VERSION ""

NS_ :

BS_:

BU_: SR_RR SR_RF SR_LR SR_LF DACU

BO_ 2671902706 TesterFuncDiagMsg_Vic4: 8 DACU
 SG_ FuncDiagDataTester : 0|64@1+ (1,0) [0|0] ""  SR_LF,SR_RF,SR_LR,SR_RR

BO_ 1754 SR_RR_Debug10_Vic4: 64 Vector__XXX
 SG_ Debug_10_SR_RR : 0|512@1+ (1,0) [0|0] ""  SR_RR

BO_ 1753 SR_RR_Debug09_Vic4: 64 Vector__XXX
 SG_ Debug_09_SR_RR : 0|512@1+ (1,0) [0|0] ""  SR_RR

BO_ 1752 SR_RR_Debug08_Vic4: 64 Vector__XXX
 SG_ Debug_08_SR_RR : 0|512@1+ (1,0) [0|0] ""  SR_RR

BO_ 1751 SR_RR_Debug07_Vic4: 64 Vector__XXX
 SG_ Debug_07_SR_RR : 0|512@1+ (1,0) [0|0] ""  SR_RR

BO_ 1750 SR_RR_Debug06_Vic4: 64 Vector__XXX
 SG_ Debug_06_SR_RR : 0|512@1+ (1,0) [0|0] ""  SR_RR

BO_ 1749 SR_RR_Debug05_Vic4: 64 SR_RR
 SG_ Debug_05_SR_RR : 0|512@1+ (1,0) [0|0] "" Vector__XXX

BO_ 1748 SR_RR_Debug04_Vic4: 64 SR_RR
 SG_ Debug_04_SR_RR : 0|512@1+ (1,0) [0|0] "" Vector__XXX

BO_ 1747 SR_RR_Debug03_Vic4: 64 SR_RR
 SG_ Debug_03_SR_RR : 0|512@1+ (1,0) [0|0] "" Vector__XXX

BO_ 1746 SR_RR_Debug02_Vic4: 64 SR_RR
 SG_ Debug_02_SR_RR : 0|512@1+ (1,0) [0|0] "" Vector__XXX

BO_ 1745 SR_RR_Debug01_Vic4: 64 SR_RR
 SG_ Debug_01_SR_RR : 0|512@1+ (1,0) [0|0] "" Vector__XXX

BO_ 1738 SR_RF_Debug10_Vic4: 64 Vector__XXX
 SG_ Debug_10_SR_RF : 0|512@1+ (1,0) [0|0] ""  SR_RF

BO_ 1737 SR_RF_Debug09_Vic4: 64 Vector__XXX
 SG_ Debug_09_SR_RF : 0|512@1+ (1,0) [0|0] ""  SR_RF

BO_ 1736 SR_RF_Debug08_Vic4: 64 Vector__XXX
 SG_ Debug_08_SR_RF : 0|512@1+ (1,0) [0|0] ""  SR_RF

BO_ 1735 SR_RF_Debug07_Vic4: 64 Vector__XXX
 SG_ Debug_07_SR_RF : 0|512@1+ (1,0) [0|0] ""  SR_RF

BO_ 1734 SR_RF_Debug06_Vic4: 64 Vector__XXX
 SG_ Debug_06_SR_RF : 0|512@1+ (1,0) [0|0] ""  SR_RF

BO_ 1733 SR_RF_Debug05_Vic4: 64 SR_RF
 SG_ Debug_05_SR_RF : 0|512@1+ (1,0) [0|0] "" Vector__XXX

BO_ 1732 SR_RF_Debug04_Vic4: 64 SR_RF
 SG_ Debug_04_SR_RF : 0|512@1+ (1,0) [0|0] "" Vector__XXX

BO_ 1731 SR_RF_Debug03_Vic4: 64 SR_RF
 SG_ Debug_03_SR_RF : 0|512@1+ (1,0) [0|0] "" Vector__XXX

BO_ 1730 SR_RF_Debug02_Vic4: 64 SR_RF
 SG_ Debug_02_SR_RF : 0|512@1+ (1,0) [0|0] "" Vector__XXX

BO_ 1729 SR_RF_Debug01_Vic4: 64 SR_RF
 SG_ Debug_01_SR_RF : 0|512@1+ (1,0) [0|0] "" Vector__XXX

BO_ 1722 SR_LR_Debug10_Vic4: 64 Vector__XXX
 SG_ Debug_10_SR_LR : 0|512@1+ (1,0) [0|0] ""  SR_LR

BO_ 1721 SR_LR_Debug09_Vic4: 64 Vector__XXX
 SG_ Debug_09_SR_LR : 0|512@1+ (1,0) [0|0] ""  SR_LR

BO_ 1720 SR_LR_Debug08_Vic4: 64 Vector__XXX
 SG_ Debug_08_SR_LR : 0|512@1+ (1,0) [0|0] ""  SR_LR

BO_ 1719 SR_LR_Debug07_Vic4: 64 Vector__XXX
 SG_ Debug_07_SR_LR : 0|512@1+ (1,0) [0|0] ""  SR_LR

BO_ 1718 SR_LR_Debug06_Vic4: 64 Vector__XXX
 SG_ Debug_06_SR_LR : 0|512@1+ (1,0) [0|0] ""  SR_LR

BO_ 1717 SR_LR_Debug05_Vic4: 64 SR_LR
 SG_ Debug_05_SR_LR : 0|512@1+ (1,0) [0|0] "" Vector__XXX

BO_ 1716 SR_LR_Debug04_Vic4: 64 SR_LR
 SG_ Debug_04_SR_LR : 0|512@1+ (1,0) [0|0] "" Vector__XXX

BO_ 1715 SR_LR_Debug03_Vic4: 64 SR_LR
 SG_ Debug_03_SR_LR : 0|512@1+ (1,0) [0|0] "" Vector__XXX

BO_ 1714 SR_LR_Debug02_Vic4: 64 SR_LR
 SG_ Debug_02_SR_LR : 0|512@1+ (1,0) [0|0] "" Vector__XXX

BO_ 1713 SR_LR_Debug01_Vic4: 64 SR_LR
 SG_ Debug_01_SR_LR : 0|512@1+ (1,0) [0|0] "" Vector__XXX

BO_ 1706 SR_LF_Debug10_Vic4: 64 Vector__XXX
 SG_ Debug_10_SR_LF : 0|512@1+ (1,0) [0|0] ""  SR_LF

BO_ 1705 SR_LF_Debug09_Vic4: 64 Vector__XXX
 SG_ Debug_09_SR_LF : 0|512@1+ (1,0) [0|0] ""  SR_LF

BO_ 1704 SR_LF_Debug08_Vic4: 64 Vector__XXX
 SG_ Debug_08_SR_LF : 0|512@1+ (1,0) [0|0] ""  SR_LF

BO_ 1703 SR_LF_Debug07_Vic4: 64 Vector__XXX
 SG_ Debug_07_SR_LF : 0|512@1+ (1,0) [0|0] ""  SR_LF

BO_ 1702 SR_LF_Debug06_Vic4: 64 Vector__XXX
 SG_ Debug_06_SR_LF : 0|512@1+ (1,0) [0|0] ""  SR_LF

BO_ 1701 SR_LF_Debug05_Vic4: 64 SR_LF
 SG_ Debug_05_SR_LF : 0|512@1+ (1,0) [0|0] "" Vector__XXX

BO_ 1700 SR_LF_Debug04_Vic4: 64 SR_LF
 SG_ Debug_04_SR_LF : 0|512@1+ (1,0) [0|0] "" Vector__XXX

BO_ 1699 SR_LF_Debug03_Vic4: 64 SR_LF
 SG_ Debug_03_SR_LF : 0|512@1+ (1,0) [0|0] "" Vector__XXX

BO_ 1698 SR_LF_Debug02_Vic4: 64 SR_LF
 SG_ Debug_02_SR_LF : 0|512@1+ (1,0) [0|0] "" Vector__XXX

BO_ 1697 SR_LF_Debug01_Vic4: 64 SR_LF
 SG_ Debug_01_SR_LF : 0|512@1+ (1,0) [0|0] "" Vector__XXX

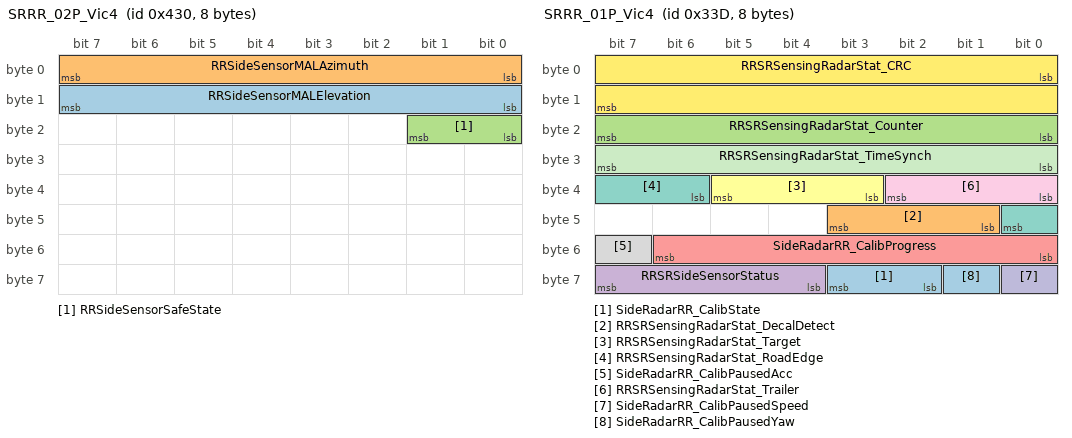
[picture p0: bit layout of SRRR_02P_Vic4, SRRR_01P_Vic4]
BO_ 1072 SRRR_02P_Vic4: 8 SR_RR
 SG_ RRSideSensorMALElevation : 8|8@1+ (0.0016,-0.2) [-0.2|0.208] "rad"  VCM
 SG_ RRSideSensorMALAzimuth : 0|8@1+ (0.0016,-0.2) [-0.2|0.208] "rad"  VCM
 SG_ RRSideSensorSafeState : 16|2@1+ (1,0) [0|0] ""  VCM

BO_ 829 SRRR_01P_Vic4: 8 SR_RR
 SG_ SideRadarRR_CalibState : 58|2@1+ (1,0) [0|0] ""  VCM
 SG_ RRSRSensingRadarStat_DecalDetect : 41|3@1+ (1,0) [0|0] ""  VCM
 SG_ RRSRSensingRadarStat_Counter : 16|8@1+ (1,0) [0|255] "Count"  VCM
 SG_ RRSRSideSensorStatus : 60|4@1+ (1,0) [0|0] ""  VCM
 SG_ SideRadarRR_CalibProgress : 48|7@1+ (1,0) [0|127] "Percent"  VCM
 SG_ RRSRSensingRadarStat_Target : 35|3@1+ (1,0) [0|0] ""  VCM
 SG_ RRSRSensingRadarStat_RoadEdge : 38|3@1+ (1,0) [0|0] ""  VCM
 SG_ SideRadarRR_CalibPausedAcc : 55|1@1+ (1,0) [0|0] ""  VCM
 SG_ RRSRSensingRadarStat_Trailer : 32|3@1+ (1,0) [0|0] ""  VCM
 SG_ SideRadarRR_CalibPausedSpeed : 56|1@1+ (1,0) [0|0] ""  VCM
 SG_ RRSRSensingRadarStat_TimeSynch : 24|8@1+ (1,0) [0|0] ""  VCM
 SG_ RRSRSensingRadarStat_CRC : 0|16@1+ (1,0) [0|65535] "NotApplicable"  VCM
 SG_ SideRadarRR_CalibPausedYaw : 57|1@1+ (1,0) [0|0] ""  VCM

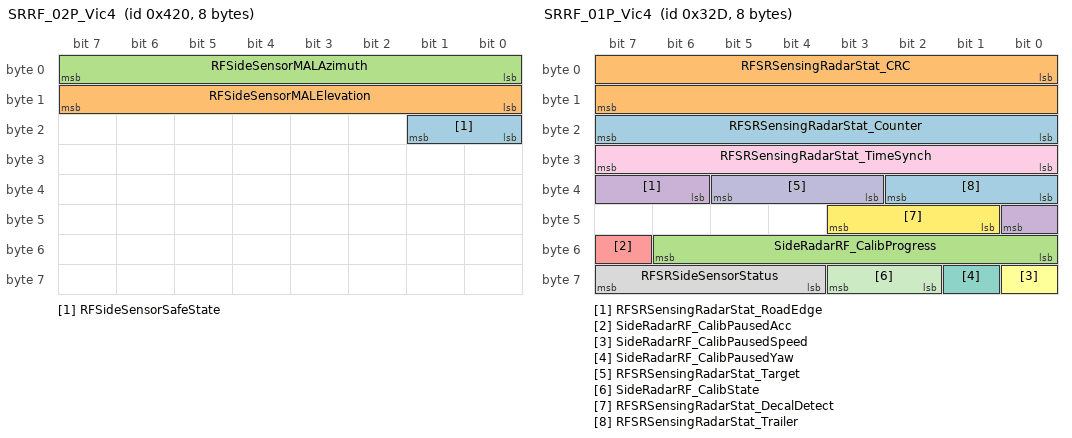
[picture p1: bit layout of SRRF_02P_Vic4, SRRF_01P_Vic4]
BO_ 1056 SRRF_02P_Vic4: 8 SR_RF
 SG_ RFSideSensorSafeState : 16|2@1+ (1,0) [0|0] ""  VCM
 SG_ RFSideSensorMALElevation : 8|8@1+ (0.0016,-0.2) [-0.2|0.208] "rad"  VCM
 SG_ RFSideSensorMALAzimuth : 0|8@1+ (0.0016,-0.2) [-0.2|0.208] "rad"  VCM

BO_ 813 SRRF_01P_Vic4: 8 SR_RF
 SG_ RFSRSensingRadarStat_Counter : 16|8@1+ (1,0) [0|255] "Count"  VCM
 SG_ RFSRSensingRadarStat_CRC : 0|16@1+ (1,0) [0|65535] "NotApplicable"  VCM
 SG_ SideRadarRF_CalibProgress : 48|7@1+ (1,0) [0|127] "Percent"  VCM
 SG_ RFSRSensingRadarStat_RoadEdge : 38|3@1+ (1,0) [0|0] ""  VCM
 SG_ SideRadarRF_CalibPausedAcc : 55|1@1+ (1,0) [0|0] ""  VCM
 SG_ SideRadarRF_CalibPausedSpeed : 56|1@1+ (1,0) [0|0] ""  VCM
 SG_ SideRadarRF_CalibPausedYaw : 57|1@1+ (1,0) [0|0] ""  VCM
 SG_ RFSRSideSensorStatus : 60|4@1+ (1,0) [0|0] ""  VCM
 SG_ RFSRSensingRadarStat_TimeSynch : 24|8@1+ (1,0) [0|0] ""  VCM
 SG_ RFSRSensingRadarStat_Target : 35|3@1+ (1,0) [0|0] ""  VCM
 SG_ SideRadarRF_CalibState : 58|2@1+ (1,0) [0|0] ""  VCM
 SG_ RFSRSensingRadarStat_DecalDetect : 41|3@1+ (1,0) [0|0] ""  VCM
 SG_ RFSRSensingRadarStat_Trailer : 32|3@1+ (1,0) [0|0] ""  VCM

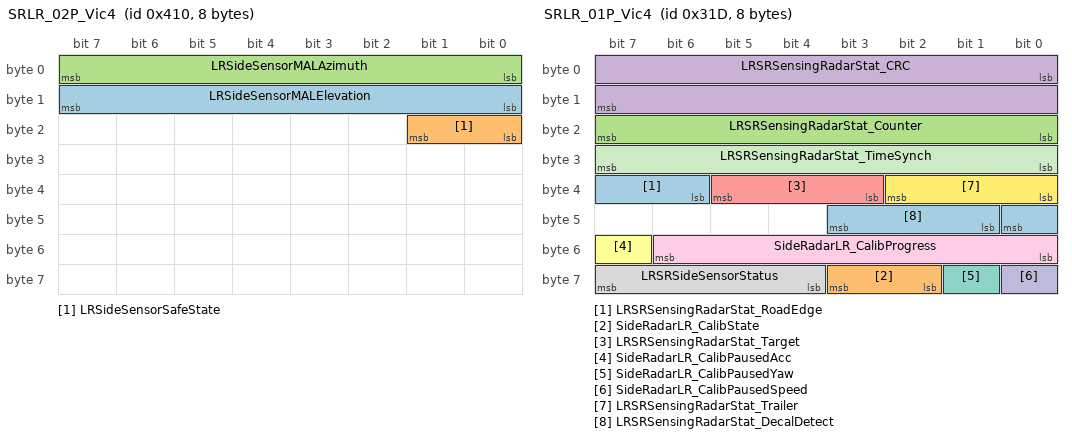
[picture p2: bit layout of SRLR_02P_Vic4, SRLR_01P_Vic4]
BO_ 1040 SRLR_02P_Vic4: 8 SR_LR
 SG_ LRSideSensorMALElevation : 8|8@1+ (0.0016,-0.2) [-0.2|0.208] "rad"  VCM
 SG_ LRSideSensorSafeState : 16|2@1+ (1,0) [0|0] ""  VCM
 SG_ LRSideSensorMALAzimuth : 0|8@1+ (0.0016,-0.2) [-0.2|0.208] "rad"  VCM

BO_ 797 SRLR_01P_Vic4: 8 SR_LR
 SG_ LRSRSensingRadarStat_RoadEdge : 38|3@1+ (1,0) [0|0] ""  VCM
 SG_ SideRadarLR_CalibState : 58|2@1+ (1,0) [0|0] ""  VCM
 SG_ LRSRSensingRadarStat_Counter : 16|8@1+ (1,0) [0|255] "Count"  VCM
 SG_ LRSRSensingRadarStat_CRC : 0|16@1+ (1,0) [0|65535] "NotApplicable"  VCM
 SG_ LRSRSensingRadarStat_Target : 35|3@1+ (1,0) [0|0] ""  VCM
 SG_ SideRadarLR_CalibPausedAcc : 55|1@1+ (1,0) [0|0] ""  VCM
 SG_ SideRadarLR_CalibPausedYaw : 57|1@1+ (1,0) [0|0] ""  VCM
 SG_ LRSRSideSensorStatus : 60|4@1+ (1,0) [0|0] ""  VCM
 SG_ SideRadarLR_CalibProgress : 48|7@1+ (1,0) [0|127] "Percent"  VCM
 SG_ SideRadarLR_CalibPausedSpeed : 56|1@1+ (1,0) [0|0] ""  VCM
 SG_ LRSRSensingRadarStat_TimeSynch : 24|8@1+ (1,0) [0|0] ""  VCM
 SG_ LRSRSensingRadarStat_Trailer : 32|3@1+ (1,0) [0|0] ""  VCM
 SG_ LRSRSensingRadarStat_DecalDetect : 41|3@1+ (1,0) [0|0] ""  VCM

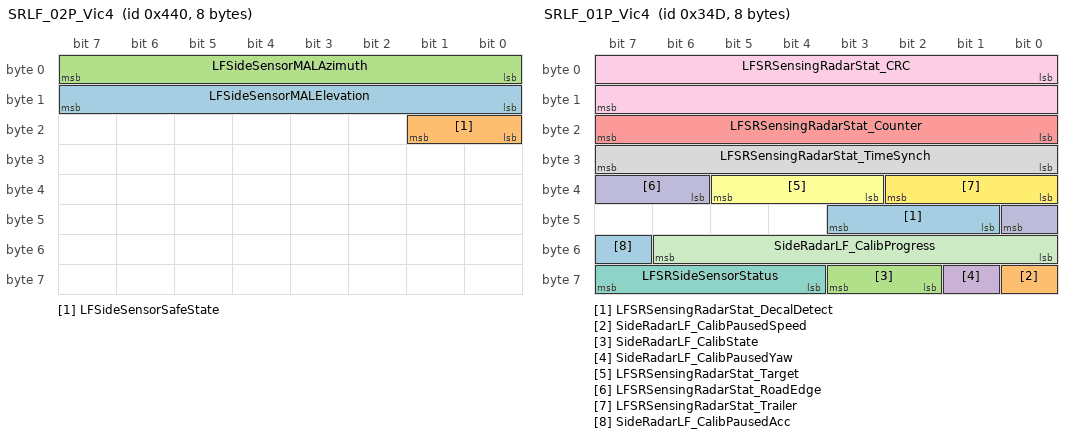
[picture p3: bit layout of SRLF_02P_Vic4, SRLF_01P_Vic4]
BO_ 1088 SRLF_02P_Vic4: 8 SR_LF
 SG_ LFSideSensorMALElevation : 8|8@1+ (0.0016,-0.2) [-0.2|0.208] "rad"  VCM
 SG_ LFSideSensorSafeState : 16|2@1+ (1,0) [0|0] ""  VCM
 SG_ LFSideSensorMALAzimuth : 0|8@1+ (0.0016,-0.2) [-0.2|0.208] "rad"  VCM

BO_ 845 SRLF_01P_Vic4: 8 SR_LF
 SG_ LFSRSensingRadarStat_DecalDetect : 41|3@1+ (1,0) [0|0] ""  VCM
 SG_ SideRadarLF_CalibPausedSpeed : 56|1@1+ (1,0) [0|0] ""  VCM
 SG_ SideRadarLF_CalibState : 58|2@1+ (1,0) [0|0] ""  VCM
 SG_ SideRadarLF_CalibPausedYaw : 57|1@1+ (1,0) [0|0] ""  VCM
 SG_ LFSRSensingRadarStat_Counter : 16|8@1+ (1,0) [0|255] "Count"  VCM
 SG_ LFSRSensingRadarStat_Target : 35|3@1+ (1,0) [0|0] ""  VCM
 SG_ LFSRSideSensorStatus : 60|4@1+ (1,0) [0|0] ""  VCM
 SG_ LFSRSensingRadarStat_TimeSynch : 24|8@1+ (1,0) [0|0] ""  VCM
 SG_ LFSRSensingRadarStat_CRC : 0|16@1+ (1,0) [0|65535] "NotApplicable"  VCM
 SG_ LFSRSensingRadarStat_RoadEdge : 38|3@1+ (1,0) [0|0] ""  VCM
 SG_ SideRadarLF_CalibProgress : 48|7@1+ (1,0) [0|127] "Percent"  VCM
 SG_ LFSRSensingRadarStat_Trailer : 32|3@1+ (1,0) [0|0] ""  VCM
 SG_ SideRadarLF_CalibPausedAcc : 55|1@1+ (1,0) [0|0] ""  VCM

BO_ 828 RRSideSensorTrlrObj: 32 SR_RR
 SG_ RRSideSensorTrlrObj_TrlAnglConf : 174|7@1+ (1,0) [0|0] ""  VCM
 SG_ RRSideSensorTrlrObj_Seg3Length : 9|9@1+ (0.05,0) [0|25.55] "m"  VCM
 SG_ RRSideSensorTrlrObj_SegTrlrType1 : 188|4@1+ (1,0) [0|0] ""  VCM
 SG_ RRSideSensorTrlrObj_SegAngle4 : 81|12@1+ (0.001745,-2.4) [-2.4|4.745775] "rad"  VCM
 SG_ RRSideSensorTrlrObj_WheelBased2 : 130|11@1+ (0.1,0) [0|204.7] "m"  VCM
 SG_ RRSideSensorTrlrObj_SegAngle3 : 69|12@1+ (0.001745,-2.4) [-2.4|4.745775] "rad"  VCM
 SG_ RRSideSensorTrlrObj_SegAngle5 : 93|12@1+ (0.001745,-2.4) [-2.4|4.745775] "rad"  VCM
 SG_ RRSideSensorTrlrObj_SegTrlrType5 : 204|4@1+ (1,0) [0|0] ""  VCM
 SG_ RRSideSensorTrlrObj_WheelBased1 : 119|11@1+ (0.1,0) [0|204.7] "m"  VCM
 SG_ RRSideSensorTrlrObj_SegTrlrType4 : 200|4@1+ (1,0) [0|0] ""  VCM
 SG_ RRSideSensorTrlrObj_WheelBased5 : 163|11@1+ (0.1,0) [0|204.7] "m"  VCM
 SG_ RRSideSensorTrlrObj_SegAngle1 : 45|12@1+ (0.001745,-2.4) [-2.4|4.745775] "rad"  VCM
 SG_ RRSideSensorTrlrObj_Seg5Length : 27|9@1+ (0.05,0) [0|25.55] "m"  VCM
 SG_ RRSideSensorTrlrObj_SegTrlrType3 : 196|4@1+ (1,0) [0|0] ""  VCM
 SG_ RRSideSensorTrlrObj_WheelBased4 : 152|11@1+ (0.1,0) [0|204.7] "m"  VCM
 SG_ RRSideSensorTrlrObj_Seg4Length : 18|9@1+ (0.05,0) [0|25.55] "m"  VCM
 SG_ RRSideSensorTrlrObj_WhlBasedConf : 181|7@1+ (1,0) [0|127] "Percent"  VCM
 SG_ RRSideSensorTrlrObj_Seg1Length : 36|9@1+ (0.05,0) [0|25.55] "m"  VCM
 SG_ RRSideSensorTrlrObj_SegTrlrType2 : 192|4@1+ (1,0) [0|0] ""  VCM
 SG_ RRSideSensorTrlrObj_SegAngle2 : 57|12@1+ (0.001745,-2.4) [-2.4|4.745775] "rad"  VCM
 SG_ RRSideSensorTrlrObj_WheelBased3 : 141|11@1+ (0.1,0) [0|204.7] "m"  VCM
 SG_ RRSideSensorTrlrObj_TotLenConf : 116|3@1+ (1,0) [0|0] ""  VCM
 SG_ RRSideSensorTrlrObj_TrlrTypeConf : 208|7@1+ (1,0) [0|127] "Percent"  VCM
 SG_ RRSideSensorTrlrObj_Seg2Length : 0|9@1+ (0.05,0) [0|25.55] "m"  VCM
 SG_ RRSideSensorTrlrObj_TotalLength : 105|11@1+ (0.1,0) [0|204.7] "m"  VCM

BO_ 827 RRSideSensorObj11: 48 SR_RR
 SG_ RRSideSensorObj11_TrackStatus : 192|3@1+ (1,0) [0|0] ""  VCM
 SG_ RRSideSensorObj11_CoastIndex : 155|5@1+ (1,0) [0|31] "NotApplicable"  VCM
 SG_ RRSideSensorObj11_ExistConf : 283|7@1+ (0.01,0) [0|1.27] "NotApplicable"  VCM
 SG_ RRSideSensorObj11_LatExtLeft : 276|7@1+ (0.05,0) [0|6.35] "m"  VCM
 SG_ RRSideSensorObj11_CRC : 0|16@1+ (1,0) [0|65535] "NotApplicable"  VCM
 SG_ RRSideSensorObj11_LongExtBkVar : 64|8@1+ (0.1,0) [0|25.5] "NotApplicable"  VCM
 SG_ RRSideSensorObj11_MOISPrio : 307|1@1+ (1,0) [0|0] ""  VCM
 SG_ RRSideSensorObj11_LongPosVar : 48|8@1+ (0.01,0) [0|2.55] "NotApplicable"  VCM
 SG_ RRSideSensorObj11_ObjClass : 292|4@1+ (1,0) [0|0] ""  VCM
 SG_ RRSideSensorObj11_LatVel : 208|13@1+ (0.032,-80) [-80|182.112] "m_per_s"  VCM
 SG_ RRSideSensorObj11_LatExtLeftVar : 104|8@1+ (0.1,0) [0|25.5] "NotApplicable"  VCM
 SG_ RRSideSensorObj11_LatPos : 221|13@1+ (0.05,-180) [-180|229.55] "m"  VCM
 SG_ RRSideSensorObj11_LongExtFront : 247|10@1+ (0.05,0) [0|51.15] "m"  VCM
 SG_ RRSideSensorObj11_LongAcc : 176|9@1+ (0.08,-20) [-20|20.88] "m_per_s_squared"  VCM
 SG_ RRSideSensorObj11_LifeTime : 128|16@1+ (0.1,0) [0|6553.5] "s"  VCM
 SG_ RRSideSensorObj11_LongVelVar : 40|8@1+ (0.01,0) [0|2.55] "NotApplicable"  VCM
 SG_ RRSideSensorObj11_TimeStamp : 24|16@1+ (0.1,0) [0|6553.5] "ms"  VCM
 SG_ RRSideSensorObj11_LatAcc : 267|9@1+ (0.08,-20) [-20|20.88] "m_per_s_squared"  VCM
 SG_ RRSideSensorObj11_HeadingVar : 120|8@1+ (0.001,0) [0|0.255] "NotApplicable"  VCM
 SG_ RRSideSensorObj11_Counter : 16|8@1+ (1,0) [0|255] "Count"  VCM
 SG_ RRSideSensorObj11_LatPosVar : 88|8@1+ (0.1,0) [0|25.5] "NotApplicable"  VCM
 SG_ RRSideSensorObj11_LongPos : 234|13@1+ (0.05,-180) [-180|229.55] "m"  VCM
 SG_ RRSideSensorObj11_LongVel : 195|13@1+ (0.032,-80) [-80|182.112] "m_per_s"  VCM
 SG_ RRSideSensorObj11_ObjID : 160|6@1+ (1,0) [0|63] "NotApplicable"  VCM
 SG_ RRSideSensorObj11_ObstacleConf : 300|7@1+ (0.01,0) [0|1.27] "NotApplicable"  VCM
 SG_ RRSideSensorObj11_LatExtRight : 185|7@1+ (0.05,-5) [-5|1.35] "m"  VCM
 SG_ RRSideSensorObj11_LongExtBack : 257|10@1+ (0.05,-50) [-50|1.15000000000001] "m"  VCM
 SG_ RRSideSensorObj11_ObjClassConf : 296|4@1+ (0.1,0) [0|1.5] "NotApplicable"  VCM
 SG_ RRSideSensorObj11_LatVelVar : 80|8@1+ (0.01,0) [0|2.55] "NotApplicable"  VCM
 SG_ RRSideSensorObj11_Heading : 144|11@1+ (0.005818,-4.71) [-4.71|7.199446] "rad"  VCM
 SG_ RRSideSensorObj11_Height : 168|8@1+ (0.02,0) [0|5.1] "m"  VCM
 SG_ RRSideSensorObj11_LatAccVar : 112|8@1+ (0.1,0) [0|25.5] "NotApplicable"  VCM
 SG_ RRSideSensorObj11_LongAccVar : 72|8@1+ (0.1,0) [0|25.5] "NotApplicable"  VCM
 SG_ RRSideSensorObj11_LatExtRtVar : 96|8@1+ (0.1,0) [0|25.5] "NotApplicable"  VCM
 SG_ RRSideSensorObj11_LongExtFrVar : 56|8@1+ (0.1,0) [0|25.5] "NotApplicable"  VCM
 SG_ RRSideSensorObj11_ObjDynClass : 166|2@1+ (1,0) [0|0] ""  VCM
 SG_ RRSideSensorObj11_Prioritisation : 290|2@1+ (1,0) [0|0] ""  VCM

BO_ 826 RRSideSensorObj10: 48 SR_RR
 SG_ RRSideSensorObj10_Counter : 16|8@1+ (1,0) [0|255] "Count"  VCM
 SG_ RRSideSensorObj10_LatExtRight : 185|7@1+ (0.05,-5) [-5|1.35] "m"  VCM
 SG_ RRSideSensorObj10_ObjClassConf : 296|4@1+ (0.1,0) [0|1.5] "NotApplicable"  VCM
 SG_ RRSideSensorObj10_ObjDynClass : 166|2@1+ (1,0) [0|0] ""  VCM
 SG_ RRSideSensorObj10_Prioritisation : 290|2@1+ (1,0) [0|0] ""  VCM
 SG_ RRSideSensorObj10_ObjClass : 292|4@1+ (1,0) [0|0] ""  VCM
 SG_ RRSideSensorObj10_LatPosVar : 88|8@1+ (0.1,0) [0|25.5] "NotApplicable"  VCM
 SG_ RRSideSensorObj10_Height : 168|8@1+ (0.02,0) [0|5.1] "m"  VCM
 SG_ RRSideSensorObj10_LatExtRtVar : 96|8@1+ (0.1,0) [0|25.5] "NotApplicable"  VCM
 SG_ RRSideSensorObj10_LatExtLeft : 276|7@1+ (0.05,0) [0|6.35] "m"  VCM
 SG_ RRSideSensorObj10_LongAccVar : 72|8@1+ (0.1,0) [0|25.5] "NotApplicable"  VCM
 SG_ RRSideSensorObj10_LongExtBack : 257|10@1+ (0.05,-50) [-50|1.15000000000001] "m"  VCM
 SG_ RRSideSensorObj10_HeadingVar : 120|8@1+ (0.001,0) [0|0.255] "NotApplicable"  VCM
 SG_ RRSideSensorObj10_CRC : 0|16@1+ (1,0) [0|65535] "NotApplicable"  VCM
 SG_ RRSideSensorObj10_LongExtBkVar : 64|8@1+ (0.1,0) [0|25.5] "NotApplicable"  VCM
 SG_ RRSideSensorObj10_TrackStatus : 192|3@1+ (1,0) [0|0] ""  VCM
 SG_ RRSideSensorObj10_LongVelVar : 40|8@1+ (0.01,0) [0|2.55] "NotApplicable"  VCM
 SG_ RRSideSensorObj10_ObjID : 160|6@1+ (1,0) [0|63] "NotApplicable"  VCM
 SG_ RRSideSensorObj10_LatExtLeftVar : 104|8@1+ (0.1,0) [0|25.5] "NotApplicable"  VCM
 SG_ RRSideSensorObj10_LongAcc : 176|9@1+ (0.08,-20) [-20|20.88] "m_per_s_squared"  VCM
 SG_ RRSideSensorObj10_ExistConf : 283|7@1+ (0.01,0) [0|1.27] "NotApplicable"  VCM
 SG_ RRSideSensorObj10_Heading : 144|11@1+ (0.005818,-4.71) [-4.71|7.199446] "rad"  VCM
 SG_ RRSideSensorObj10_LatAccVar : 112|8@1+ (0.1,0) [0|25.5] "NotApplicable"  VCM
 SG_ RRSideSensorObj10_LatAcc : 267|9@1+ (0.08,-20) [-20|20.88] "m_per_s_squared"  VCM
 SG_ RRSideSensorObj10_LongExtFront : 247|10@1+ (0.05,0) [0|51.15] "m"  VCM
 SG_ RRSideSensorObj10_LongExtFrVar : 56|8@1+ (0.1,0) [0|25.5] "NotApplicable"  VCM
 SG_ RRSideSensorObj10_LatVel : 208|13@1+ (0.032,-80) [-80|182.112] "m_per_s"  VCM
 SG_ RRSideSensorObj10_LongPos : 234|13@1+ (0.05,-180) [-180|229.55] "m"  VCM
 SG_ RRSideSensorObj10_LatPos : 221|13@1+ (0.05,-180) [-180|229.55] "m"  VCM
 SG_ RRSideSensorObj10_LongPosVar : 48|8@1+ (0.01,0) [0|2.55] "NotApplicable"  VCM
 SG_ RRSideSensorObj10_LongVel : 195|13@1+ (0.032,-80) [-80|182.112] "m_per_s"  VCM
 SG_ RRSideSensorObj10_ObstacleConf : 300|7@1+ (0.01,0) [0|1.27] "NotApplicable"  VCM
 SG_ RRSideSensorObj10_MOISPrio : 307|1@1+ (1,0) [0|0] ""  VCM
 SG_ RRSideSensorObj10_TimeStamp : 24|16@1+ (0.1,0) [0|6553.5] "ms"  VCM
 SG_ RRSideSensorObj10_LifeTime : 128|16@1+ (0.1,0) [0|6553.5] "s"  VCM
 SG_ RRSideSensorObj10_CoastIndex : 155|5@1+ (1,0) [0|31] "NotApplicable"  VCM
 SG_ RRSideSensorObj10_LatVelVar : 80|8@1+ (0.01,0) [0|2.55] "NotApplicable"  VCM

BO_ 825 RRSideSensorObj09: 48 SR_RR
 SG_ RRSideSensorObj09_LatExtRight : 185|7@1+ (0.05,-5) [-5|1.35] "m"  VCM
 SG_ RRSideSensorObj09_LongPosVar : 48|8@1+ (0.01,0) [0|2.55] "NotApplicable"  VCM
 SG_ RRSideSensorObj09_Height : 168|8@1+ (0.02,0) [0|5.1] "m"  VCM
 SG_ RRSideSensorObj09_LongAccVar : 72|8@1+ (0.1,0) [0|25.5] "NotApplicable"  VCM
 SG_ RRSideSensorObj09_LongExtBack : 257|10@1+ (0.05,-50) [-50|1.15000000000001] "m"  VCM
 SG_ RRSideSensorObj09_LatPosVar : 88|8@1+ (0.1,0) [0|25.5] "NotApplicable"  VCM
 SG_ RRSideSensorObj09_LatVelVar : 80|8@1+ (0.01,0) [0|2.55] "NotApplicable"  VCM
 SG_ RRSideSensorObj09_LatVel : 208|13@1+ (0.032,-80) [-80|182.112] "m_per_s"  VCM
 SG_ RRSideSensorObj09_LatExtLeft : 276|7@1+ (0.05,0) [0|6.35] "m"  VCM
 SG_ RRSideSensorObj09_HeadingVar : 120|8@1+ (0.001,0) [0|0.255] "NotApplicable"  VCM
 SG_ RRSideSensorObj09_LatExtRtVar : 96|8@1+ (0.1,0) [0|25.5] "NotApplicable"  VCM
 SG_ RRSideSensorObj09_ObjClassConf : 296|4@1+ (0.1,0) [0|1.5] "NotApplicable"  VCM
 SG_ RRSideSensorObj09_CoastIndex : 155|5@1+ (1,0) [0|31] "NotApplicable"  VCM
 SG_ RRSideSensorObj09_ObjDynClass : 166|2@1+ (1,0) [0|0] ""  VCM
 SG_ RRSideSensorObj09_LongExtFrVar : 56|8@1+ (0.1,0) [0|25.5] "NotApplicable"  VCM
 SG_ RRSideSensorObj09_LongPos : 234|13@1+ (0.05,-180) [-180|229.55] "m"  VCM
 SG_ RRSideSensorObj09_Counter : 16|8@1+ (1,0) [0|255] "Count"  VCM
 SG_ RRSideSensorObj09_CRC : 0|16@1+ (1,0) [0|65535] "NotApplicable"  VCM
 SG_ RRSideSensorObj09_LatAcc : 267|9@1+ (0.08,-20) [-20|20.88] "m_per_s_squared"  VCM
 SG_ RRSideSensorObj09_LongExtBkVar : 64|8@1+ (0.1,0) [0|25.5] "NotApplicable"  VCM
 SG_ RRSideSensorObj09_Heading : 144|11@1+ (0.005818,-4.71) [-4.71|7.199446] "rad"  VCM
 SG_ RRSideSensorObj09_LatAccVar : 112|8@1+ (0.1,0) [0|25.5] "NotApplicable"  VCM
 SG_ RRSideSensorObj09_ObjClass : 292|4@1+ (1,0) [0|0] ""  VCM
 SG_ RRSideSensorObj09_Prioritisation : 290|2@1+ (1,0) [0|0] ""  VCM
 SG_ RRSideSensorObj09_LongVel : 195|13@1+ (0.032,-80) [-80|182.112] "m_per_s"  VCM
 SG_ RRSideSensorObj09_TrackStatus : 192|3@1+ (1,0) [0|0] ""  VCM
 SG_ RRSideSensorObj09_LongExtFront : 247|10@1+ (0.05,0) [0|51.15] "m"  VCM
 SG_ RRSideSensorObj09_LatExtLeftVar : 104|8@1+ (0.1,0) [0|25.5] "NotApplicable"  VCM
 SG_ RRSideSensorObj09_TimeStamp : 24|16@1+ (0.1,0) [0|6553.5] "ms"  VCM
 SG_ RRSideSensorObj09_ObjID : 160|6@1+ (1,0) [0|63] "NotApplicable"  VCM
 SG_ RRSideSensorObj09_LongAcc : 176|9@1+ (0.08,-20) [-20|20.88] "m_per_s_squared"  VCM
 SG_ RRSideSensorObj09_LatPos : 221|13@1+ (0.05,-180) [-180|229.55] "m"  VCM
 SG_ RRSideSensorObj09_ObstacleConf : 300|7@1+ (0.01,0) [0|1.27] "NotApplicable"  VCM
 SG_ RRSideSensorObj09_MOISPrio : 307|1@1+ (1,0) [0|0] ""  VCM
 SG_ RRSideSensorObj09_LongVelVar : 40|8@1+ (0.01,0) [0|2.55] "NotApplicable"  VCM
 SG_ RRSideSensorObj09_ExistConf : 283|7@1+ (0.01,0) [0|1.27] "NotApplicable"  VCM
 SG_ RRSideSensorObj09_LifeTime : 128|16@1+ (0.1,0) [0|6553.5] "s"  VCM

BO_ 824 RRSideSensorObj08: 48 SR_RR
 SG_ RRSideSensorObj08_LongExtBkVar : 64|8@1+ (0.1,0) [0|25.5] "NotApplicable"  VCM
 SG_ RRSideSensorObj08_ExistConf : 283|7@1+ (0.01,0) [0|1.27] "NotApplicable"  VCM
 SG_ RRSideSensorObj08_CRC : 0|16@1+ (1,0) [0|65535] "NotApplicable"  VCM
 SG_ RRSideSensorObj08_LifeTime : 128|16@1+ (0.1,0) [0|6553.5] "s"  VCM
 SG_ RRSideSensorObj08_LatAcc : 267|9@1+ (0.08,-20) [-20|20.88] "m_per_s_squared"  VCM
 SG_ RRSideSensorObj08_LongAcc : 176|9@1+ (0.08,-20) [-20|20.88] "m_per_s_squared"  VCM
 SG_ RRSideSensorObj08_Counter : 16|8@1+ (1,0) [0|255] "Count"  VCM
 SG_ RRSideSensorObj08_LongExtBack : 257|10@1+ (0.05,-50) [-50|1.15000000000001] "m"  VCM
 SG_ RRSideSensorObj08_LatExtLeft : 276|7@1+ (0.05,0) [0|6.35] "m"  VCM
 SG_ RRSideSensorObj08_TimeStamp : 24|16@1+ (0.1,0) [0|6553.5] "ms"  VCM
 SG_ RRSideSensorObj08_LatPosVar : 88|8@1+ (0.1,0) [0|25.5] "NotApplicable"  VCM
 SG_ RRSideSensorObj08_LatExtLeftVar : 104|8@1+ (0.1,0) [0|25.5] "NotApplicable"  VCM
 SG_ RRSideSensorObj08_Height : 168|8@1+ (0.02,0) [0|5.1] "m"  VCM
 SG_ RRSideSensorObj08_LongExtFront : 247|10@1+ (0.05,0) [0|51.15] "m"  VCM
 SG_ RRSideSensorObj08_Prioritisation : 290|2@1+ (1,0) [0|0] ""  VCM
 SG_ RRSideSensorObj08_HeadingVar : 120|8@1+ (0.001,0) [0|0.255] "NotApplicable"  VCM
 SG_ RRSideSensorObj08_LongAccVar : 72|8@1+ (0.1,0) [0|25.5] "NotApplicable"  VCM
 SG_ RRSideSensorObj08_LatAccVar : 112|8@1+ (0.1,0) [0|25.5] "NotApplicable"  VCM
 SG_ RRSideSensorObj08_ObstacleConf : 300|7@1+ (0.01,0) [0|1.27] "NotApplicable"  VCM
 SG_ RRSideSensorObj08_LatVelVar : 80|8@1+ (0.01,0) [0|2.55] "NotApplicable"  VCM
 SG_ RRSideSensorObj08_TrackStatus : 192|3@1+ (1,0) [0|0] ""  VCM
 SG_ RRSideSensorObj08_MOISPrio : 307|1@1+ (1,0) [0|0] ""  VCM
 SG_ RRSideSensorObj08_LatExtRight : 185|7@1+ (0.05,-5) [-5|1.35] "m"  VCM
 SG_ RRSideSensorObj08_LongPosVar : 48|8@1+ (0.01,0) [0|2.55] "NotApplicable"  VCM
 SG_ RRSideSensorObj08_LongExtFrVar : 56|8@1+ (0.1,0) [0|25.5] "NotApplicable"  VCM
 SG_ RRSideSensorObj08_LatVel : 208|13@1+ (0.032,-80) [-80|182.112] "m_per_s"  VCM
 SG_ RRSideSensorObj08_LatExtRtVar : 96|8@1+ (0.1,0) [0|25.5] "NotApplicable"  VCM
 SG_ RRSideSensorObj08_ObjDynClass : 166|2@1+ (1,0) [0|0] ""  VCM
 SG_ RRSideSensorObj08_LongVelVar : 40|8@1+ (0.01,0) [0|2.55] "NotApplicable"  VCM
 SG_ RRSideSensorObj08_Heading : 144|11@1+ (0.005818,-4.71) [-4.71|7.199446] "rad"  VCM
 SG_ RRSideSensorObj08_CoastIndex : 155|5@1+ (1,0) [0|31] "NotApplicable"  VCM
 SG_ RRSideSensorObj08_ObjClass : 292|4@1+ (1,0) [0|0] ""  VCM
 SG_ RRSideSensorObj08_LongVel : 195|13@1+ (0.032,-80) [-80|182.112] "m_per_s"  VCM
 SG_ RRSideSensorObj08_LatPos : 221|13@1+ (0.05,-180) [-180|229.55] "m"  VCM
 SG_ RRSideSensorObj08_ObjID : 160|6@1+ (1,0) [0|63] "NotApplicable"  VCM
 SG_ RRSideSensorObj08_LongPos : 234|13@1+ (0.05,-180) [-180|229.55] "m"  VCM
 SG_ RRSideSensorObj08_ObjClassConf : 296|4@1+ (0.1,0) [0|1.5] "NotApplicable"  VCM

BO_ 823 RRSideSensorObj07: 48 SR_RR
 SG_ RRSideSensorObj07_LifeTime : 128|16@1+ (0.1,0) [0|6553.5] "s"  VCM
 SG_ RRSideSensorObj07_HeadingVar : 120|8@1+ (0.001,0) [0|0.255] "NotApplicable"  VCM
 SG_ RRSideSensorObj07_LongExtFrVar : 56|8@1+ (0.1,0) [0|25.5] "NotApplicable"  VCM
 SG_ RRSideSensorObj07_ObjID : 160|6@1+ (1,0) [0|63] "NotApplicable"  VCM
 SG_ RRSideSensorObj07_Heading : 144|11@1+ (0.005818,-4.71) [-4.71|7.199446] "rad"  VCM
 SG_ RRSideSensorObj07_LongVelVar : 40|8@1+ (0.01,0) [0|2.55] "NotApplicable"  VCM
 SG_ RRSideSensorObj07_TimeStamp : 24|16@1+ (0.1,0) [0|6553.5] "ms"  VCM
 SG_ RRSideSensorObj07_LatPosVar : 88|8@1+ (0.1,0) [0|25.5] "NotApplicable"  VCM
 SG_ RRSideSensorObj07_ExistConf : 283|7@1+ (0.01,0) [0|1.27] "NotApplicable"  VCM
 SG_ RRSideSensorObj07_Prioritisation : 290|2@1+ (1,0) [0|0] ""  VCM
 SG_ RRSideSensorObj07_Counter : 16|8@1+ (1,0) [0|255] "Count"  VCM
 SG_ RRSideSensorObj07_LatPos : 221|13@1+ (0.05,-180) [-180|229.55] "m"  VCM
 SG_ RRSideSensorObj07_LongVel : 195|13@1+ (0.032,-80) [-80|182.112] "m_per_s"  VCM
 SG_ RRSideSensorObj07_LongExtBack : 257|10@1+ (0.05,-50) [-50|1.15000000000001] "m"  VCM
 SG_ RRSideSensorObj07_LongExtFront : 247|10@1+ (0.05,0) [0|51.15] "m"  VCM
 SG_ RRSideSensorObj07_TrackStatus : 192|3@1+ (1,0) [0|0] ""  VCM
 SG_ RRSideSensorObj07_LongExtBkVar : 64|8@1+ (0.1,0) [0|25.5] "NotApplicable"  VCM
 SG_ RRSideSensorObj07_LatAccVar : 112|8@1+ (0.1,0) [0|25.5] "NotApplicable"  VCM
 SG_ RRSideSensorObj07_LongAcc : 176|9@1+ (0.08,-20) [-20|20.88] "m_per_s_squared"  VCM
 SG_ RRSideSensorObj07_LatAcc : 267|9@1+ (0.08,-20) [-20|20.88] "m_per_s_squared"  VCM
 SG_ RRSideSensorObj07_ObjDynClass : 166|2@1+ (1,0) [0|0] ""  VCM
 SG_ RRSideSensorObj07_ObjClassConf : 296|4@1+ (0.1,0) [0|1.5] "NotApplicable"  VCM
 SG_ RRSideSensorObj07_CRC : 0|16@1+ (1,0) [0|65535] "NotApplicable"  VCM
 SG_ RRSideSensorObj07_LongPosVar : 48|8@1+ (0.01,0) [0|2.55] "NotApplicable"  VCM
 SG_ RRSideSensorObj07_LatExtLeftVar : 104|8@1+ (0.1,0) [0|25.5] "NotApplicable"  VCM
 SG_ RRSideSensorObj07_MOISPrio : 307|1@1+ (1,0) [0|0] ""  VCM
 SG_ RRSideSensorObj07_ObjClass : 292|4@1+ (1,0) [0|0] ""  VCM
 SG_ RRSideSensorObj07_ObstacleConf : 300|7@1+ (0.01,0) [0|1.27] "NotApplicable"  VCM
 SG_ RRSideSensorObj07_LatExtRtVar : 96|8@1+ (0.1,0) [0|25.5] "NotApplicable"  VCM
 SG_ RRSideSensorObj07_LatExtRight : 185|7@1+ (0.05,-5) [-5|1.35] "m"  VCM
 SG_ RRSideSensorObj07_LatExtLeft : 276|7@1+ (0.05,0) [0|6.35] "m"  VCM
 SG_ RRSideSensorObj07_Height : 168|8@1+ (0.02,0) [0|5.1] "m"  VCM
 SG_ RRSideSensorObj07_LatVel : 208|13@1+ (0.032,-80) [-80|182.112] "m_per_s"  VCM
 SG_ RRSideSensorObj07_LongAccVar : 72|8@1+ (0.1,0) [0|25.5] "NotApplicable"  VCM
 SG_ RRSideSensorObj07_LongPos : 234|13@1+ (0.05,-180) [-180|229.55] "m"  VCM
 SG_ RRSideSensorObj07_CoastIndex : 155|5@1+ (1,0) [0|31] "NotApplicable"  VCM
 SG_ RRSideSensorObj07_LatVelVar : 80|8@1+ (0.01,0) [0|2.55] "NotApplicable"  VCM

BO_ 822 RRSideSensorObj06: 48 SR_RR
 SG_ RRSideSensorObj06_LongExtFront : 247|10@1+ (0.05,0) [0|51.15] "m"  VCM
 SG_ RRSideSensorObj06_ObjDynClass : 166|2@1+ (1,0) [0|0] ""  VCM
 SG_ RRSideSensorObj06_MOISPrio : 307|1@1+ (1,0) [0|0] ""  VCM
 SG_ RRSideSensorObj06_LatExtLeft : 276|7@1+ (0.05,0) [0|6.35] "m"  VCM
 SG_ RRSideSensorObj06_ObjClassConf : 296|4@1+ (0.1,0) [0|1.5] "NotApplicable"  VCM
 SG_ RRSideSensorObj06_LongPosVar : 48|8@1+ (0.01,0) [0|2.55] "NotApplicable"  VCM
 SG_ RRSideSensorObj06_LatExtRight : 185|7@1+ (0.05,-5) [-5|1.35] "m"  VCM
 SG_ RRSideSensorObj06_LongVel : 195|13@1+ (0.032,-80) [-80|182.112] "m_per_s"  VCM
 SG_ RRSideSensorObj06_LifeTime : 128|16@1+ (0.1,0) [0|6553.5] "s"  VCM
 SG_ RRSideSensorObj06_LongExtBack : 257|10@1+ (0.05,-50) [-50|1.15000000000001] "m"  VCM
 SG_ RRSideSensorObj06_HeadingVar : 120|8@1+ (0.001,0) [0|0.255] "NotApplicable"  VCM
 SG_ RRSideSensorObj06_LatVel : 208|13@1+ (0.032,-80) [-80|182.112] "m_per_s"  VCM
 SG_ RRSideSensorObj06_LatExtRtVar : 96|8@1+ (0.1,0) [0|25.5] "NotApplicable"  VCM
 SG_ RRSideSensorObj06_LongExtFrVar : 56|8@1+ (0.1,0) [0|25.5] "NotApplicable"  VCM
 SG_ RRSideSensorObj06_LongAccVar : 72|8@1+ (0.1,0) [0|25.5] "NotApplicable"  VCM
 SG_ RRSideSensorObj06_LatExtLeftVar : 104|8@1+ (0.1,0) [0|25.5] "NotApplicable"  VCM
 SG_ RRSideSensorObj06_LongVelVar : 40|8@1+ (0.01,0) [0|2.55] "NotApplicable"  VCM
 SG_ RRSideSensorObj06_Prioritisation : 290|2@1+ (1,0) [0|0] ""  VCM
 SG_ RRSideSensorObj06_LongPos : 234|13@1+ (0.05,-180) [-180|229.55] "m"  VCM
 SG_ RRSideSensorObj06_Counter : 16|8@1+ (1,0) [0|255] "Count"  VCM
 SG_ RRSideSensorObj06_LatVelVar : 80|8@1+ (0.01,0) [0|2.55] "NotApplicable"  VCM
 SG_ RRSideSensorObj06_LatAccVar : 112|8@1+ (0.1,0) [0|25.5] "NotApplicable"  VCM
 SG_ RRSideSensorObj06_Heading : 144|11@1+ (0.005818,-4.71) [-4.71|7.199446] "rad"  VCM
 SG_ RRSideSensorObj06_ObjClass : 292|4@1+ (1,0) [0|0] ""  VCM
 SG_ RRSideSensorObj06_ObstacleConf : 300|7@1+ (0.01,0) [0|1.27] "NotApplicable"  VCM
 SG_ RRSideSensorObj06_LatPosVar : 88|8@1+ (0.1,0) [0|25.5] "NotApplicable"  VCM
 SG_ RRSideSensorObj06_LongAcc : 176|9@1+ (0.08,-20) [-20|20.88] "m_per_s_squared"  VCM
 SG_ RRSideSensorObj06_LongExtBkVar : 64|8@1+ (0.1,0) [0|25.5] "NotApplicable"  VCM
 SG_ RRSideSensorObj06_Height : 168|8@1+ (0.02,0) [0|5.1] "m"  VCM
 SG_ RRSideSensorObj06_LatPos : 221|13@1+ (0.05,-180) [-180|229.55] "m"  VCM
 SG_ RRSideSensorObj06_CoastIndex : 155|5@1+ (1,0) [0|31] "NotApplicable"  VCM
 SG_ RRSideSensorObj06_TrackStatus : 192|3@1+ (1,0) [0|0] ""  VCM
 SG_ RRSideSensorObj06_LatAcc : 267|9@1+ (0.08,-20) [-20|20.88] "m_per_s_squared"  VCM
 SG_ RRSideSensorObj06_ExistConf : 283|7@1+ (0.01,0) [0|1.27] "NotApplicable"  VCM
 SG_ RRSideSensorObj06_CRC : 0|16@1+ (1,0) [0|65535] "NotApplicable"  VCM
 SG_ RRSideSensorObj06_ObjID : 160|6@1+ (1,0) [0|63] "NotApplicable"  VCM
 SG_ RRSideSensorObj06_TimeStamp : 24|16@1+ (0.1,0) [0|6553.5] "ms"  VCM

BO_ 821 RRSideSensorObj05: 48 SR_RR
 SG_ RRSideSensorObj05_LatPos : 221|13@1+ (0.05,-180) [-180|229.55] "m"  VCM
 SG_ RRSideSensorObj05_ObjClass : 292|4@1+ (1,0) [0|0] ""  VCM
 SG_ RRSideSensorObj05_LongVel : 195|13@1+ (0.032,-80) [-80|182.112] "m_per_s"  VCM
 SG_ RRSideSensorObj05_ObjID : 160|6@1+ (1,0) [0|63] "NotApplicable"  VCM
 SG_ RRSideSensorObj05_LatPosVar : 88|8@1+ (0.1,0) [0|25.5] "NotApplicable"  VCM
 SG_ RRSideSensorObj05_Prioritisation : 290|2@1+ (1,0) [0|0] ""  VCM
 SG_ RRSideSensorObj05_LifeTime : 128|16@1+ (0.1,0) [0|6553.5] "s"  VCM
 SG_ RRSideSensorObj05_LongAccVar : 72|8@1+ (0.1,0) [0|25.5] "NotApplicable"  VCM
 SG_ RRSideSensorObj05_CRC : 0|16@1+ (1,0) [0|65535] "NotApplicable"  VCM
 SG_ RRSideSensorObj05_TrackStatus : 192|3@1+ (1,0) [0|0] ""  VCM
 SG_ RRSideSensorObj05_ObstacleConf : 300|7@1+ (0.01,0) [0|1.27] "NotApplicable"  VCM
 SG_ RRSideSensorObj05_ObjDynClass : 166|2@1+ (1,0) [0|0] ""  VCM
 SG_ RRSideSensorObj05_LatExtRight : 185|7@1+ (0.05,-5) [-5|1.35] "m"  VCM
 SG_ RRSideSensorObj05_LongPosVar : 48|8@1+ (0.01,0) [0|2.55] "NotApplicable"  VCM
 SG_ RRSideSensorObj05_Heading : 144|11@1+ (0.005818,-4.71) [-4.71|7.199446] "rad"  VCM
 SG_ RRSideSensorObj05_LongExtFront : 247|10@1+ (0.05,0) [0|51.15] "m"  VCM
 SG_ RRSideSensorObj05_LatAcc : 267|9@1+ (0.08,-20) [-20|20.88] "m_per_s_squared"  VCM
 SG_ RRSideSensorObj05_MOISPrio : 307|1@1+ (1,0) [0|0] ""  VCM
 SG_ RRSideSensorObj05_LatVelVar : 80|8@1+ (0.01,0) [0|2.55] "NotApplicable"  VCM
 SG_ RRSideSensorObj05_LatAccVar : 112|8@1+ (0.1,0) [0|25.5] "NotApplicable"  VCM
 SG_ RRSideSensorObj05_LongAcc : 176|9@1+ (0.08,-20) [-20|20.88] "m_per_s_squared"  VCM
 SG_ RRSideSensorObj05_LongExtBack : 257|10@1+ (0.05,-50) [-50|1.15000000000001] "m"  VCM
 SG_ RRSideSensorObj05_ObjClassConf : 296|4@1+ (0.1,0) [0|1.5] "NotApplicable"  VCM
 SG_ RRSideSensorObj05_ExistConf : 283|7@1+ (0.01,0) [0|1.27] "NotApplicable"  VCM
 SG_ RRSideSensorObj05_Height : 168|8@1+ (0.02,0) [0|5.1] "m"  VCM
 SG_ RRSideSensorObj05_LongExtFrVar : 56|8@1+ (0.1,0) [0|25.5] "NotApplicable"  VCM
 SG_ RRSideSensorObj05_Counter : 16|8@1+ (1,0) [0|255] "Count"  VCM
 SG_ RRSideSensorObj05_TimeStamp : 24|16@1+ (0.1,0) [0|6553.5] "ms"  VCM
 SG_ RRSideSensorObj05_LongPos : 234|13@1+ (0.05,-180) [-180|229.55] "m"  VCM
 SG_ RRSideSensorObj05_LongVelVar : 40|8@1+ (0.01,0) [0|2.55] "NotApplicable"  VCM
 SG_ RRSideSensorObj05_HeadingVar : 120|8@1+ (0.001,0) [0|0.255] "NotApplicable"  VCM
 SG_ RRSideSensorObj05_LatExtRtVar : 96|8@1+ (0.1,0) [0|25.5] "NotApplicable"  VCM
 SG_ RRSideSensorObj05_LatVel : 208|13@1+ (0.032,-80) [-80|182.112] "m_per_s"  VCM
 SG_ RRSideSensorObj05_LatExtLeft : 276|7@1+ (0.05,0) [0|6.35] "m"  VCM
 SG_ RRSideSensorObj05_LongExtBkVar : 64|8@1+ (0.1,0) [0|25.5] "NotApplicable"  VCM
 SG_ RRSideSensorObj05_CoastIndex : 155|5@1+ (1,0) [0|31] "NotApplicable"  VCM
 SG_ RRSideSensorObj05_LatExtLeftVar : 104|8@1+ (0.1,0) [0|25.5] "NotApplicable"  VCM

BO_ 820 RRSideSensorObj04: 48 SR_RR
 SG_ RRSideSensorObj04_HeadingVar : 120|8@1+ (0.001,0) [0|0.255] "NotApplicable"  VCM
 SG_ RRSideSensorObj04_TrackStatus : 192|3@1+ (1,0) [0|0] ""  VCM
 SG_ RRSideSensorObj04_LongExtFront : 247|10@1+ (0.05,0) [0|51.15] "m"  VCM
 SG_ RRSideSensorObj04_LatAcc : 267|9@1+ (0.08,-20) [-20|20.88] "m_per_s_squared"  VCM
 SG_ RRSideSensorObj04_LongPosVar : 48|8@1+ (0.01,0) [0|2.55] "NotApplicable"  VCM
 SG_ RRSideSensorObj04_LatVelVar : 80|8@1+ (0.01,0) [0|2.55] "NotApplicable"  VCM
 SG_ RRSideSensorObj04_CoastIndex : 155|5@1+ (1,0) [0|31] "NotApplicable"  VCM
 SG_ RRSideSensorObj04_LatPosVar : 88|8@1+ (0.1,0) [0|25.5] "NotApplicable"  VCM
 SG_ RRSideSensorObj04_ExistConf : 283|7@1+ (0.01,0) [0|1.27] "NotApplicable"  VCM
 SG_ RRSideSensorObj04_LatExtRight : 185|7@1+ (0.05,-5) [-5|1.35] "m"  VCM
 SG_ RRSideSensorObj04_LatAccVar : 112|8@1+ (0.1,0) [0|25.5] "NotApplicable"  VCM
 SG_ RRSideSensorObj04_ObjID : 160|6@1+ (1,0) [0|63] "NotApplicable"  VCM
 SG_ RRSideSensorObj04_LongAccVar : 72|8@1+ (0.1,0) [0|25.5] "NotApplicable"  VCM
 SG_ RRSideSensorObj04_ObstacleConf : 300|7@1+ (0.01,0) [0|1.27] "NotApplicable"  VCM
 SG_ RRSideSensorObj04_MOISPrio : 307|1@1+ (1,0) [0|0] ""  VCM
 SG_ RRSideSensorObj04_LongPos : 234|13@1+ (0.05,-180) [-180|229.55] "m"  VCM
 SG_ RRSideSensorObj04_LatVel : 208|13@1+ (0.032,-80) [-80|182.112] "m_per_s"  VCM
 SG_ RRSideSensorObj04_LongExtBack : 257|10@1+ (0.05,-50) [-50|1.15000000000001] "m"  VCM
 SG_ RRSideSensorObj04_TimeStamp : 24|16@1+ (0.1,0) [0|6553.5] "ms"  VCM
 SG_ RRSideSensorObj04_LatExtRtVar : 96|8@1+ (0.1,0) [0|25.5] "NotApplicable"  VCM
 SG_ RRSideSensorObj04_CRC : 0|16@1+ (1,0) [0|65535] "NotApplicable"  VCM
 SG_ RRSideSensorObj04_LatExtLeft : 276|7@1+ (0.05,0) [0|6.35] "m"  VCM
 SG_ RRSideSensorObj04_LongVel : 195|13@1+ (0.032,-80) [-80|182.112] "m_per_s"  VCM
 SG_ RRSideSensorObj04_LongExtFrVar : 56|8@1+ (0.1,0) [0|25.5] "NotApplicable"  VCM
 SG_ RRSideSensorObj04_Counter : 16|8@1+ (1,0) [0|255] "Count"  VCM
 SG_ RRSideSensorObj04_LatPos : 221|13@1+ (0.05,-180) [-180|229.55] "m"  VCM
 SG_ RRSideSensorObj04_LatExtLeftVar : 104|8@1+ (0.1,0) [0|25.5] "NotApplicable"  VCM
 SG_ RRSideSensorObj04_LifeTime : 128|16@1+ (0.1,0) [0|6553.5] "s"  VCM
 SG_ RRSideSensorObj04_Height : 168|8@1+ (0.02,0) [0|5.1] "m"  VCM
 SG_ RRSideSensorObj04_LongAcc : 176|9@1+ (0.08,-20) [-20|20.88] "m_per_s_squared"  VCM
 SG_ RRSideSensorObj04_ObjDynClass : 166|2@1+ (1,0) [0|0] ""  VCM
 SG_ RRSideSensorObj04_LongVelVar : 40|8@1+ (0.01,0) [0|2.55] "NotApplicable"  VCM
 SG_ RRSideSensorObj04_ObjClass : 292|4@1+ (1,0) [0|0] ""  VCM
 SG_ RRSideSensorObj04_ObjClassConf : 296|4@1+ (0.1,0) [0|1.5] "NotApplicable"  VCM
 SG_ RRSideSensorObj04_Prioritisation : 290|2@1+ (1,0) [0|0] ""  VCM
 SG_ RRSideSensorObj04_Heading : 144|11@1+ (0.005818,-4.71) [-4.71|7.199446] "rad"  VCM
 SG_ RRSideSensorObj04_LongExtBkVar : 64|8@1+ (0.1,0) [0|25.5] "NotApplicable"  VCM

BO_ 819 RRSideSensorObj03: 48 SR_RR
 SG_ RRSideSensorObj03_LongExtBack : 257|10@1+ (0.05,-50) [-50|1.15000000000001] "m"  VCM
 SG_ RRSideSensorObj03_ObjDynClass : 166|2@1+ (1,0) [0|0] ""  VCM
 SG_ RRSideSensorObj03_ObjClass : 292|4@1+ (1,0) [0|0] ""  VCM
 SG_ RRSideSensorObj03_LatAcc : 267|9@1+ (0.08,-20) [-20|20.88] "m_per_s_squared"  VCM
 SG_ RRSideSensorObj03_Heading : 144|11@1+ (0.005818,-4.71) [-4.71|7.199446] "rad"  VCM
 SG_ RRSideSensorObj03_ObjClassConf : 296|4@1+ (0.1,0) [0|1.5] "NotApplicable"  VCM
 SG_ RRSideSensorObj03_LongPos : 234|13@1+ (0.05,-180) [-180|229.55] "m"  VCM
 SG_ RRSideSensorObj03_ObjID : 160|6@1+ (1,0) [0|63] "NotApplicable"  VCM
 SG_ RRSideSensorObj03_TimeStamp : 24|16@1+ (0.1,0) [0|6553.5] "ms"  VCM
 SG_ RRSideSensorObj03_LongPosVar : 48|8@1+ (0.01,0) [0|2.55] "NotApplicable"  VCM
 SG_ RRSideSensorObj03_LatExtLeft : 276|7@1+ (0.05,0) [0|6.35] "m"  VCM
 SG_ RRSideSensorObj03_LongExtFrVar : 56|8@1+ (0.1,0) [0|25.5] "NotApplicable"  VCM
 SG_ RRSideSensorObj03_LongVel : 195|13@1+ (0.032,-80) [-80|182.112] "m_per_s"  VCM
 SG_ RRSideSensorObj03_LatVel : 208|13@1+ (0.032,-80) [-80|182.112] "m_per_s"  VCM
 SG_ RRSideSensorObj03_Prioritisation : 290|2@1+ (1,0) [0|0] ""  VCM
 SG_ RRSideSensorObj03_Height : 168|8@1+ (0.02,0) [0|5.1] "m"  VCM
 SG_ RRSideSensorObj03_CRC : 0|16@1+ (1,0) [0|65535] "NotApplicable"  VCM
 SG_ RRSideSensorObj03_LatExtRtVar : 96|8@1+ (0.1,0) [0|25.5] "NotApplicable"  VCM
 SG_ RRSideSensorObj03_ExistConf : 283|7@1+ (0.01,0) [0|1.27] "NotApplicable"  VCM
 SG_ RRSideSensorObj03_Counter : 16|8@1+ (1,0) [0|255] "Count"  VCM
 SG_ RRSideSensorObj03_LongExtBkVar : 64|8@1+ (0.1,0) [0|25.5] "NotApplicable"  VCM
 SG_ RRSideSensorObj03_LatVelVar : 80|8@1+ (0.01,0) [0|2.55] "NotApplicable"  VCM
 SG_ RRSideSensorObj03_LatExtRight : 185|7@1+ (0.05,-5) [-5|1.35] "m"  VCM
 SG_ RRSideSensorObj03_LifeTime : 128|16@1+ (0.1,0) [0|6553.5] "s"  VCM
 SG_ RRSideSensorObj03_LatExtLeftVar : 104|8@1+ (0.1,0) [0|25.5] "NotApplicable"  VCM
 SG_ RRSideSensorObj03_HeadingVar : 120|8@1+ (0.001,0) [0|0.255] "NotApplicable"  VCM
 SG_ RRSideSensorObj03_LatPos : 221|13@1+ (0.05,-180) [-180|229.55] "m"  VCM
 SG_ RRSideSensorObj03_ObstacleConf : 300|7@1+ (0.01,0) [0|1.27] "NotApplicable"  VCM
 SG_ RRSideSensorObj03_LatPosVar : 88|8@1+ (0.1,0) [0|25.5] "NotApplicable"  VCM
 SG_ RRSideSensorObj03_LongExtFront : 247|10@1+ (0.05,0) [0|51.15] "m"  VCM
 SG_ RRSideSensorObj03_LongAcc : 176|9@1+ (0.08,-20) [-20|20.88] "m_per_s_squared"  VCM
 SG_ RRSideSensorObj03_CoastIndex : 155|5@1+ (1,0) [0|31] "NotApplicable"  VCM
 SG_ RRSideSensorObj03_TrackStatus : 192|3@1+ (1,0) [0|0] ""  VCM
 SG_ RRSideSensorObj03_MOISPrio : 307|1@1+ (1,0) [0|0] ""  VCM
 SG_ RRSideSensorObj03_LongAccVar : 72|8@1+ (0.1,0) [0|25.5] "NotApplicable"  VCM
 SG_ RRSideSensorObj03_LongVelVar : 40|8@1+ (0.01,0) [0|2.55] "NotApplicable"  VCM
 SG_ RRSideSensorObj03_LatAccVar : 112|8@1+ (0.1,0) [0|25.5] "NotApplicable"  VCM

BO_ 818 RRSideSensorObj02: 48 SR_RR
 SG_ RRSideSensorObj02_Prioritisation : 290|2@1+ (1,0) [0|0] ""  VCM
 SG_ RRSideSensorObj02_LongAcc : 176|9@1+ (0.08,-20) [-20|20.88] "m_per_s_squared"  VCM
 SG_ RRSideSensorObj02_LatAcc : 267|9@1+ (0.08,-20) [-20|20.88] "m_per_s_squared"  VCM
 SG_ RRSideSensorObj02_LatExtRight : 185|7@1+ (0.05,-5) [-5|1.35] "m"  VCM
 SG_ RRSideSensorObj02_LongAccVar : 72|8@1+ (0.1,0) [0|25.5] "NotApplicable"  VCM
 SG_ RRSideSensorObj02_LongPos : 234|13@1+ (0.05,-180) [-180|229.55] "m"  VCM
 SG_ RRSideSensorObj02_ObstacleConf : 300|7@1+ (0.01,0) [0|1.27] "NotApplicable"  VCM
 SG_ RRSideSensorObj02_LongExtFrVar : 56|8@1+ (0.1,0) [0|25.5] "NotApplicable"  VCM
 SG_ RRSideSensorObj02_LatVelVar : 80|8@1+ (0.01,0) [0|2.55] "NotApplicable"  VCM
 SG_ RRSideSensorObj02_MOISPrio : 307|1@1+ (1,0) [0|0] ""  VCM
 SG_ RRSideSensorObj02_LatPos : 221|13@1+ (0.05,-180) [-180|229.55] "m"  VCM
 SG_ RRSideSensorObj02_LatVel : 208|13@1+ (0.032,-80) [-80|182.112] "m_per_s"  VCM
 SG_ RRSideSensorObj02_LongVelVar : 40|8@1+ (0.01,0) [0|2.55] "NotApplicable"  VCM
 SG_ RRSideSensorObj02_LongExtBack : 257|10@1+ (0.05,-50) [-50|1.15000000000001] "m"  VCM
 SG_ RRSideSensorObj02_Height : 168|8@1+ (0.02,0) [0|5.1] "m"  VCM
 SG_ RRSideSensorObj02_ExistConf : 283|7@1+ (0.01,0) [0|1.27] "NotApplicable"  VCM
 SG_ RRSideSensorObj02_ObjDynClass : 166|2@1+ (1,0) [0|0] ""  VCM
 SG_ RRSideSensorObj02_ObjID : 160|6@1+ (1,0) [0|63] "NotApplicable"  VCM
 SG_ RRSideSensorObj02_ObjClassConf : 296|4@1+ (0.1,0) [0|1.5] "NotApplicable"  VCM
 SG_ RRSideSensorObj02_LongPosVar : 48|8@1+ (0.01,0) [0|2.55] "NotApplicable"  VCM
 SG_ RRSideSensorObj02_TrackStatus : 192|3@1+ (1,0) [0|0] ""  VCM
 SG_ RRSideSensorObj02_CoastIndex : 155|5@1+ (1,0) [0|31] "NotApplicable"  VCM
 SG_ RRSideSensorObj02_LatExtLeft : 276|7@1+ (0.05,0) [0|6.35] "m"  VCM
 SG_ RRSideSensorObj02_Counter : 16|8@1+ (1,0) [0|255] "Count"  VCM
 SG_ RRSideSensorObj02_HeadingVar : 120|8@1+ (0.001,0) [0|0.255] "NotApplicable"  VCM
 SG_ RRSideSensorObj02_LatExtRtVar : 96|8@1+ (0.1,0) [0|25.5] "NotApplicable"  VCM
 SG_ RRSideSensorObj02_Heading : 144|11@1+ (0.005818,-4.71) [-4.71|7.199446] "rad"  VCM
 SG_ RRSideSensorObj02_TimeStamp : 24|16@1+ (0.1,0) [0|6553.5] "ms"  VCM
 SG_ RRSideSensorObj02_LatExtLeftVar : 104|8@1+ (0.1,0) [0|25.5] "NotApplicable"  VCM
 SG_ RRSideSensorObj02_CRC : 0|16@1+ (1,0) [0|65535] "NotApplicable"  VCM
 SG_ RRSideSensorObj02_LatPosVar : 88|8@1+ (0.1,0) [0|25.5] "NotApplicable"  VCM
 SG_ RRSideSensorObj02_LongVel : 195|13@1+ (0.032,-80) [-80|182.112] "m_per_s"  VCM
 SG_ RRSideSensorObj02_LongExtBkVar : 64|8@1+ (0.1,0) [0|25.5] "NotApplicable"  VCM
 SG_ RRSideSensorObj02_LatAccVar : 112|8@1+ (0.1,0) [0|25.5] "NotApplicable"  VCM
 SG_ RRSideSensorObj02_LifeTime : 128|16@1+ (0.1,0) [0|6553.5] "s"  VCM
 SG_ RRSideSensorObj02_ObjClass : 292|4@1+ (1,0) [0|0] ""  VCM
 SG_ RRSideSensorObj02_LongExtFront : 247|10@1+ (0.05,0) [0|51.15] "m"  VCM

BO_ 817 RRSideSensorObj01: 48 SR_RR
 SG_ RRSideSensorObj01_ExistConf : 283|7@1+ (0.01,0) [0|1.27] "NotApplicable"  VCM
 SG_ RRSideSensorObj01_MOISPrio : 307|1@1+ (1,0) [0|0] ""  VCM
 SG_ RRSideSensorObj01_LatVelVar : 80|8@1+ (0.01,0) [0|2.55] "NotApplicable"  VCM
 SG_ RRSideSensorObj01_LongAcc : 176|9@1+ (0.08,-20) [-20|20.88] "m_per_s_squared"  VCM
 SG_ RRSideSensorObj01_Prioritisation : 290|2@1+ (1,0) [0|0] ""  VCM
 SG_ RRSideSensorObj01_LifeTime : 128|16@1+ (0.1,0) [0|6553.5] "s"  VCM
 SG_ RRSideSensorObj01_LatExtRight : 185|7@1+ (0.05,-5) [-5|1.35] "m"  VCM
 SG_ RRSideSensorObj01_HeadingVar : 120|8@1+ (0.001,0) [0|0.255] "NotApplicable"  VCM
 SG_ RRSideSensorObj01_LatAccVar : 112|8@1+ (0.1,0) [0|25.5] "NotApplicable"  VCM
 SG_ RRSideSensorObj01_LongAccVar : 72|8@1+ (0.1,0) [0|25.5] "NotApplicable"  VCM
 SG_ RRSideSensorObj01_CoastIndex : 155|5@1+ (1,0) [0|31] "NotApplicable"  VCM
 SG_ RRSideSensorObj01_ObstacleConf : 300|7@1+ (0.01,0) [0|1.27] "NotApplicable"  VCM
 SG_ RRSideSensorObj01_TimeStamp : 24|16@1+ (0.1,0) [0|6553.5] "ms"  VCM
 SG_ RRSideSensorObj01_LongVel : 195|13@1+ (0.032,-80) [-80|182.112] "m_per_s"  VCM
 SG_ RRSideSensorObj01_ObjID : 160|6@1+ (1,0) [0|63] "NotApplicable"  VCM
 SG_ RRSideSensorObj01_LongPos : 234|13@1+ (0.05,-180) [-180|229.55] "m"  VCM
 SG_ RRSideSensorObj01_LatPos : 221|13@1+ (0.05,-180) [-180|229.55] "m"  VCM
 SG_ RRSideSensorObj01_LatAcc : 267|9@1+ (0.08,-20) [-20|20.88] "m_per_s_squared"  VCM
 SG_ RRSideSensorObj01_LongExtBack : 257|10@1+ (0.05,-50) [-50|1.15000000000001] "m"  VCM
 SG_ RRSideSensorObj01_LongVelVar : 40|8@1+ (0.01,0) [0|2.55] "NotApplicable"  VCM
 SG_ RRSideSensorObj01_LongExtFrVar : 56|8@1+ (0.1,0) [0|25.5] "NotApplicable"  VCM
 SG_ RRSideSensorObj01_ObjDynClass : 166|2@1+ (1,0) [0|0] ""  VCM
 SG_ RRSideSensorObj01_Counter : 16|8@1+ (1,0) [0|255] "Count"  VCM
 SG_ RRSideSensorObj01_ObjClassConf : 296|4@1+ (0.1,0) [0|1.5] "NotApplicable"  VCM
 SG_ RRSideSensorObj01_LatExtLeft : 276|7@1+ (0.05,0) [0|6.35] "m"  VCM
 SG_ RRSideSensorObj01_Height : 168|8@1+ (0.02,0) [0|5.1] "m"  VCM
 SG_ RRSideSensorObj01_ObjClass : 292|4@1+ (1,0) [0|0] ""  VCM
 SG_ RRSideSensorObj01_LongPosVar : 48|8@1+ (0.01,0) [0|2.55] "NotApplicable"  VCM
 SG_ RRSideSensorObj01_Heading : 144|11@1+ (0.005818,-4.71) [-4.71|7.199446] "rad"  VCM
 SG_ RRSideSensorObj01_LatExtRtVar : 96|8@1+ (0.1,0) [0|25.5] "NotApplicable"  VCM
 SG_ RRSideSensorObj01_LongExtFront : 247|10@1+ (0.05,0) [0|51.15] "m"  VCM
 SG_ RRSideSensorObj01_LatExtLeftVar : 104|8@1+ (0.1,0) [0|25.5] "NotApplicable"  VCM
 SG_ RRSideSensorObj01_LatPosVar : 88|8@1+ (0.1,0) [0|25.5] "NotApplicable"  VCM
 SG_ RRSideSensorObj01_TrackStatus : 192|3@1+ (1,0) [0|0] ""  VCM
 SG_ RRSideSensorObj01_LatVel : 208|13@1+ (0.032,-80) [-80|182.112] "m_per_s"  VCM
 SG_ RRSideSensorObj01_LongExtBkVar : 64|8@1+ (0.1,0) [0|25.5] "NotApplicable"  VCM
 SG_ RRSideSensorObj01_CRC : 0|16@1+ (1,0) [0|65535] "NotApplicable"  VCM

CM_ "COM_MATRIX_T2_1.27.0";
CM_ BU_ SR_RR "Side Radar, Right-hand side, Rearward-looking";
CM_ BU_ SR_RF "Side Radar, Right-hand side, Forward-looking";
CM_ BU_ SR_LR "Side Radar, Left-hand side, Rearward-looking";
CM_ BU_ SR_LF "Side Radar, Left-hand side, Forward-looking";
CM_ BU_ DACU "Driver Assistance Control Unit";
BA_DEF_ BO_  "GenMsgStartDelayTime" INT 0 0;
BA_DEF_ BO_  "GenMsgDelayTime" INT 0 0;
BA_DEF_ BO_  "GenMsgCycleTime" INT 0 0;
BA_DEF_ BO_  "GenMsgSendType" ENUM  "Cyclic","NotUsed","NotUsed","NotUsed","NotUsed","NotUsed","NotUsed","IfActive","NoMsgSendType","NotUsed";
BA_DEF_ SG_  "GenSigStartValue" INT 0 0;
BA_DEF_ SG_  "GenSigCycleTimeActive" INT 0 0;
BA_DEF_ SG_  "GenSigCycleTime" INT 0 0;
BA_DEF_ SG_  "GenSigSendType" ENUM  "Cyclic","OnWrite","OnWriteWithRepetition","OnChange","OnChangeWithRepetition","IfActive","IfActiveWithRepetition","NoSigSendType","NotUsed","NotUsed","NotUsed","NotUsed","NotUsed";
BA_DEF_  "Baudrate" INT 0 1000000;
BA_DEF_  "NmType" STRING ;
BA_DEF_  "Manufacturer" STRING ;
BA_DEF_  "VersionYear" INT 0 99;
BA_DEF_  "VersionNumber" INT 0 99;
BA_DEF_  "VersionMonth" INT 1 12;
BA_DEF_  "VersionDay" INT 1 31;
BA_DEF_ BO_  "VFrameFormat" ENUM  "StandardCAN","ExtendedCAN","reserved","J1939PG","reserved","reserved","reserved","reserved","reserved","reserved","reserved","reserved","reserved","reserved","StandardCAN_FD","ExtendedCAN_FD";
BA_DEF_ BU_  "TpOwnSystemEcuNumber" HEX 0 255;
BA_DEF_ SG_  "SigType" ENUM  "Default","Range","RangeSigned","ASCII","Discrete","Control","ReferencePGN","DTC","StringDelimiter","StringLength","StringLengthControl";
BA_DEF_ SG_  "SeToolVersion_SIGNAL" STRING ;
BA_DEF_ SG_  "SeToolUniqueID_SIGNAL" STRING ;
BA_DEF_ SG_  "SeToolName_SIGNAL" STRING ;
BA_DEF_ SG_  "SeToolItemID_SIGNAL" STRING ;
BA_DEF_ SG_  "SeToolAncestorID_SIGNAL" STRING ;
BA_DEF_  "ProtocolType" STRING ;
BA_DEF_ SG_  "Platform_VMCU1_Sig" ENUM  "No","Yes";
BA_DEF_ BU_  "NmStationAddress" INT 0 255;
BA_DEF_  "NmAsrWaitBusSleepTime" INT 0 65535;
BA_DEF_  "NmAsrTimeoutTime" INT 0 65535;
BA_DEF_  "NmAsrRepeatMessageTime" INT 0 65535;
BA_DEF_ BU_  "NmAsrNodeIdentifier" HEX 0 253;
BA_DEF_ BU_  "NmAsrNode" ENUM  "No","Yes";
BA_DEF_  "NmAsrMessageCount" INT 1 256;
BA_DEF_  "NmAsrCanMsgCycleTime" INT 0 65535;
BA_DEF_  "NmAsrBaseAddress" HEX 0 536870911;
BA_DEF_ SG_  "NeedsUpdateBit" ENUM  "No","Yes";
BA_DEF_ SG_  "GenSigMaxLatency" INT 0 65535;
BA_DEF_ SG_  "GenSigILSupport" ENUM  "Yes","No";
BA_DEF_ BO_  "GenMsgILSupport" ENUM  "No","Yes";
BA_DEF_ SG_  "E2EProfile" STRING ;
BA_DEF_  "E2EP05WindowSize" INT 0 65535;
BA_DEF_  "E2EP05ProfileName" STRING ;
BA_DEF_  "E2EP05MinOkStateValid" INT 0 65535;
BA_DEF_  "E2EP05MinOkStateInvalid" INT 0 65535;
BA_DEF_  "E2EP05MinOkStateInit" INT 0 65535;
BA_DEF_  "E2EP05MaxErrorStateValid" INT 0 65535;
BA_DEF_  "E2EP05MaxErrorStateInvalid" INT 0 65535;
BA_DEF_  "E2EP05MaxErrorStateInit" INT 0 65535;
BA_DEF_  "E2EP05MaxDeltaCounter" INT 0 65535;
BA_DEF_  "E2EP01WindowSize" INT 0 65535;
BA_DEF_  "E2EP01SyncCounterInit" INT 0 65535;
BA_DEF_  "E2EP01ProfileName" STRING ;
BA_DEF_  "E2EP01MinOkStateValid" INT 0 65535;
BA_DEF_  "E2EP01MinOkStateInvalid" INT 0 65535;
BA_DEF_  "E2EP01MinOkStateInit" INT 0 65535;
BA_DEF_  "E2EP01MaxNoNewOrRepeatedData" INT 0 65535;
BA_DEF_  "E2EP01MaxErrorStateValid" INT 0 65535;
BA_DEF_  "E2EP01MaxErrorStateInvalid" INT 0 65535;
BA_DEF_  "E2EP01MaxErrorStateInit" INT 0 65535;
BA_DEF_  "E2EP01MaxDeltaCounter" INT 0 65535;
BA_DEF_  "E2EP01DataIdMode" ENUM  "all16Bit","alternating8Bit","lower12Bit","lower8Bit";
BA_DEF_  "E2EP01CounterOffset" INT 0 65535;
BA_DEF_ SG_  "E2EDataLength" INT 0 65535;
BA_DEF_ SG_  "E2EDataId" INT 0 65535;
BA_DEF_ BO_  "DiagUUDTResponse" ENUM  "No","Yes";
BA_DEF_ BO_  "DiagState" ENUM  "No","Yes";
BA_DEF_ BO_  "DiagResponse" ENUM  "No","Yes";
BA_DEF_ BO_  "DiagRequest" ENUM  "No","Yes";
BA_DEF_ BO_  "DiagConnection" HEX 0 65535;
BA_DEF_  "DBName" STRING ;
BA_DEF_ BO_  "CanTpFcFrameId" HEX 0 2147483647;
BA_DEF_ BO_  "CanTpBs" INT 0 255;
BA_DEF_ BO_  "CANFD_BRS" ENUM  "0","1";
BA_DEF_  "BusType" STRING ;
BA_DEF_  "BaudrateCANFD" INT 0 5000000;
BA_DEF_REL_ BU_SG_REL_  "GenSigTimeoutTime" INT 0 65535;
BA_DEF_REL_ BU_SG_REL_  "GenSigFirstTimeoutTime" INT 0 65535;
BA_DEF_DEF_  "GenMsgStartDelayTime" 0;
BA_DEF_DEF_  "GenMsgDelayTime" 0;
BA_DEF_DEF_  "GenMsgCycleTime" 0;
BA_DEF_DEF_  "GenMsgSendType" "Cyclic";
BA_DEF_DEF_  "GenSigStartValue" 0;
BA_DEF_DEF_  "GenSigCycleTimeActive" 0;
BA_DEF_DEF_  "GenSigCycleTime" 0;
BA_DEF_DEF_  "GenSigSendType" "Cyclic";
BA_DEF_DEF_  "Baudrate" 500000;
BA_DEF_DEF_  "NmType" "";
BA_DEF_DEF_  "Manufacturer" "VOLVO_AB";
BA_DEF_DEF_  "VersionYear" 0;
BA_DEF_DEF_  "VersionNumber" 0;
BA_DEF_DEF_  "VersionMonth" 1;
BA_DEF_DEF_  "VersionDay" 1;
BA_DEF_DEF_  "VFrameFormat" "ExtendedCAN";
BA_DEF_DEF_  "TpOwnSystemEcuNumber" 0;
BA_DEF_DEF_  "SigType" "Default";
BA_DEF_DEF_  "SeToolVersion_SIGNAL" "";
BA_DEF_DEF_  "SeToolUniqueID_SIGNAL" "";
BA_DEF_DEF_  "SeToolName_SIGNAL" "";
BA_DEF_DEF_  "SeToolItemID_SIGNAL" "";
BA_DEF_DEF_  "SeToolAncestorID_SIGNAL" "";
BA_DEF_DEF_  "ProtocolType" "";
BA_DEF_DEF_  "Platform_VMCU1_Sig" "No";
BA_DEF_DEF_  "NmStationAddress" 254;
BA_DEF_DEF_  "NmAsrWaitBusSleepTime" 750;
BA_DEF_DEF_  "NmAsrTimeoutTime" 5000;
BA_DEF_DEF_  "NmAsrRepeatMessageTime" 300;
BA_DEF_DEF_  "NmAsrNodeIdentifier" 0;
BA_DEF_DEF_  "NmAsrNode" "Yes";
BA_DEF_DEF_  "NmAsrMessageCount" 256;
BA_DEF_DEF_  "NmAsrCanMsgCycleTime" 200;
BA_DEF_DEF_  "NmAsrBaseAddress" 486506496;
BA_DEF_DEF_  "NeedsUpdateBit" "No";
BA_DEF_DEF_  "GenSigMaxLatency" 0;
BA_DEF_DEF_  "GenSigILSupport" "Yes";
BA_DEF_DEF_  "GenMsgILSupport" "Yes";
BA_DEF_DEF_  "E2EProfile" "none";
BA_DEF_DEF_  "E2EP05WindowSize" 5;
BA_DEF_DEF_  "E2EP05ProfileName" "PROFILE_05";
BA_DEF_DEF_  "E2EP05MinOkStateValid" 1;
BA_DEF_DEF_  "E2EP05MinOkStateInvalid" 3;
BA_DEF_DEF_  "E2EP05MinOkStateInit" 1;
BA_DEF_DEF_  "E2EP05MaxErrorStateValid" 3;
BA_DEF_DEF_  "E2EP05MaxErrorStateInvalid" 1;
BA_DEF_DEF_  "E2EP05MaxErrorStateInit" 2;
BA_DEF_DEF_  "E2EP05MaxDeltaCounter" 1;
BA_DEF_DEF_  "E2EP01WindowSize" 5;
BA_DEF_DEF_  "E2EP01SyncCounterInit" 1;
BA_DEF_DEF_  "E2EP01ProfileName" "PROFILE_01";
BA_DEF_DEF_  "E2EP01MinOkStateValid" 1;
BA_DEF_DEF_  "E2EP01MinOkStateInvalid" 3;
BA_DEF_DEF_  "E2EP01MinOkStateInit" 1;
BA_DEF_DEF_  "E2EP01MaxNoNewOrRepeatedData" 5;
BA_DEF_DEF_  "E2EP01MaxErrorStateValid" 3;
BA_DEF_DEF_  "E2EP01MaxErrorStateInvalid" 1;
BA_DEF_DEF_  "E2EP01MaxErrorStateInit" 2;
BA_DEF_DEF_  "E2EP01MaxDeltaCounter" 1;
BA_DEF_DEF_  "E2EP01DataIdMode" "all16Bit";
BA_DEF_DEF_  "E2EP01CounterOffset" 8;
BA_DEF_DEF_  "E2EDataLength" 0;
BA_DEF_DEF_  "E2EDataId" 0;
BA_DEF_DEF_  "DiagUUDTResponse" "No";
BA_DEF_DEF_  "DiagState" "No";
BA_DEF_DEF_  "DiagResponse" "No";
BA_DEF_DEF_  "DiagRequest" "No";
BA_DEF_DEF_  "DiagConnection" 0;
BA_DEF_DEF_  "DBName" "";
BA_DEF_DEF_  "CanTpFcFrameId" 2147483647;
BA_DEF_DEF_  "CanTpBs" 255;
BA_DEF_DEF_  "CANFD_BRS" "0";
BA_DEF_DEF_  "BusType" "";
BA_DEF_DEF_  "BaudrateCANFD" 0;
BA_DEF_DEF_REL_ "GenSigTimeoutTime" 0;
BA_DEF_DEF_REL_ "GenSigFirstTimeoutTime" 0;
BA_ "BusType" "CAN FD";
BA_ "BaudrateCANFD" 1000000;
BA_ "ProtocolType" "CAN";
BA_ "VersionDay" 8;
BA_ "VersionMonth" 6;
BA_ "VersionNumber" 1;
BA_ "VersionYear" 22;
BA_ "DBName" "VicinityNet4";
BA_ "TpOwnSystemEcuNumber" BU_ SR_RR 106;
BA_ "NmAsrNode" BU_ SR_RR 0;
BA_ "NmAsrNodeIdentifier" BU_ SR_RR 106;
BA_ "TpOwnSystemEcuNumber" BU_ SR_RF 107;
BA_ "NmAsrNode" BU_ SR_RF 0;
BA_ "NmAsrNodeIdentifier" BU_ SR_RF 107;
BA_ "TpOwnSystemEcuNumber" BU_ SR_LR 104;
BA_ "NmAsrNode" BU_ SR_LR 0;
BA_ "NmAsrNodeIdentifier" BU_ SR_LR 104;
BA_ "TpOwnSystemEcuNumber" BU_ SR_LF 105;
BA_ "NmAsrNode" BU_ SR_LF 0;
BA_ "NmAsrNodeIdentifier" BU_ SR_LF 105;
BA_ "TpOwnSystemEcuNumber" BU_ DACU 80;
BA_ "NmAsrNode" BU_ DACU 0;
BA_ "NmAsrNodeIdentifier" BU_ DACU 80;
BA_ "DiagConnection" BO_ 2671902706 62056;
BA_ "DiagState" BO_ 2671902706 1;
BA_ "GenMsgILSupport" BO_ 2671902706 0;
BA_ "GenMsgSendType" BO_ 2671902706 8;
BA_ "CANFD_BRS" BO_ 1754 1;
BA_ "VFrameFormat" BO_ 1754 14;
BA_ "CANFD_BRS" BO_ 1753 1;
BA_ "VFrameFormat" BO_ 1753 14;
BA_ "CANFD_BRS" BO_ 1752 1;
BA_ "VFrameFormat" BO_ 1752 14;
BA_ "CANFD_BRS" BO_ 1751 1;
BA_ "VFrameFormat" BO_ 1751 14;
BA_ "CANFD_BRS" BO_ 1750 1;
BA_ "VFrameFormat" BO_ 1750 14;
BA_ "CANFD_BRS" BO_ 1749 1;
BA_ "GenMsgSendType" BO_ 1749 8;
BA_ "VFrameFormat" BO_ 1749 14;
BA_ "CANFD_BRS" BO_ 1748 1;
BA_ "GenMsgSendType" BO_ 1748 8;
BA_ "VFrameFormat" BO_ 1748 14;
BA_ "CANFD_BRS" BO_ 1747 1;
BA_ "GenMsgSendType" BO_ 1747 8;
BA_ "VFrameFormat" BO_ 1747 14;
BA_ "CANFD_BRS" BO_ 1746 1;
BA_ "GenMsgSendType" BO_ 1746 8;
BA_ "VFrameFormat" BO_ 1746 14;
BA_ "CANFD_BRS" BO_ 1745 1;
BA_ "GenMsgSendType" BO_ 1745 8;
BA_ "VFrameFormat" BO_ 1745 14;
BA_ "CANFD_BRS" BO_ 1738 1;
BA_ "VFrameFormat" BO_ 1738 14;
BA_ "CANFD_BRS" BO_ 1737 1;
BA_ "VFrameFormat" BO_ 1737 14;
BA_ "CANFD_BRS" BO_ 1736 1;
BA_ "VFrameFormat" BO_ 1736 14;
BA_ "CANFD_BRS" BO_ 1735 1;
BA_ "VFrameFormat" BO_ 1735 14;
BA_ "CANFD_BRS" BO_ 1734 1;
BA_ "VFrameFormat" BO_ 1734 14;
BA_ "CANFD_BRS" BO_ 1733 1;
BA_ "GenMsgSendType" BO_ 1733 8;
BA_ "VFrameFormat" BO_ 1733 14;
BA_ "CANFD_BRS" BO_ 1732 1;
BA_ "GenMsgSendType" BO_ 1732 8;
BA_ "VFrameFormat" BO_ 1732 14;
BA_ "CANFD_BRS" BO_ 1731 1;
BA_ "GenMsgSendType" BO_ 1731 8;
BA_ "VFrameFormat" BO_ 1731 14;
BA_ "CANFD_BRS" BO_ 1730 1;
BA_ "GenMsgSendType" BO_ 1730 8;
BA_ "VFrameFormat" BO_ 1730 14;
BA_ "CANFD_BRS" BO_ 1729 1;
BA_ "GenMsgSendType" BO_ 1729 8;
BA_ "VFrameFormat" BO_ 1729 14;
BA_ "CANFD_BRS" BO_ 1722 1;
BA_ "VFrameFormat" BO_ 1722 14;
BA_ "CANFD_BRS" BO_ 1721 1;
BA_ "VFrameFormat" BO_ 1721 14;
BA_ "CANFD_BRS" BO_ 1720 1;
BA_ "VFrameFormat" BO_ 1720 14;
BA_ "CANFD_BRS" BO_ 1719 1;
BA_ "VFrameFormat" BO_ 1719 14;
BA_ "CANFD_BRS" BO_ 1718 1;
BA_ "VFrameFormat" BO_ 1718 14;
BA_ "CANFD_BRS" BO_ 1717 1;
BA_ "GenMsgSendType" BO_ 1717 8;
BA_ "VFrameFormat" BO_ 1717 14;
BA_ "CANFD_BRS" BO_ 1716 1;
BA_ "GenMsgSendType" BO_ 1716 8;
BA_ "VFrameFormat" BO_ 1716 14;
BA_ "CANFD_BRS" BO_ 1715 1;
BA_ "GenMsgSendType" BO_ 1715 8;
BA_ "VFrameFormat" BO_ 1715 14;
BA_ "CANFD_BRS" BO_ 1714 1;
BA_ "GenMsgSendType" BO_ 1714 8;
BA_ "VFrameFormat" BO_ 1714 14;
BA_ "CANFD_BRS" BO_ 1713 1;
BA_ "GenMsgSendType" BO_ 1713 8;
BA_ "VFrameFormat" BO_ 1713 14;
BA_ "CANFD_BRS" BO_ 1706 1;
BA_ "VFrameFormat" BO_ 1706 14;
BA_ "CANFD_BRS" BO_ 1705 1;
BA_ "VFrameFormat" BO_ 1705 14;
BA_ "CANFD_BRS" BO_ 1704 1;
BA_ "VFrameFormat" BO_ 1704 14;
BA_ "CANFD_BRS" BO_ 1703 1;
BA_ "VFrameFormat" BO_ 1703 14;
BA_ "CANFD_BRS" BO_ 1702 1;
BA_ "VFrameFormat" BO_ 1702 14;
BA_ "CANFD_BRS" BO_ 1701 1;
BA_ "GenMsgSendType" BO_ 1701 8;
BA_ "VFrameFormat" BO_ 1701 14;
BA_ "CANFD_BRS" BO_ 1700 1;
BA_ "GenMsgSendType" BO_ 1700 8;
BA_ "VFrameFormat" BO_ 1700 14;
BA_ "CANFD_BRS" BO_ 1699 1;
BA_ "GenMsgSendType" BO_ 1699 8;
BA_ "VFrameFormat" BO_ 1699 14;
BA_ "CANFD_BRS" BO_ 1698 1;
BA_ "GenMsgSendType" BO_ 1698 8;
BA_ "VFrameFormat" BO_ 1698 14;
BA_ "CANFD_BRS" BO_ 1697 1;
BA_ "GenMsgSendType" BO_ 1697 8;
BA_ "VFrameFormat" BO_ 1697 14;
BA_ "CANFD_BRS" BO_ 1072 1;
BA_ "GenMsgSendType" BO_ 1072 8;
BA_ "VFrameFormat" BO_ 1072 14;
BA_ "CANFD_BRS" BO_ 829 1;
BA_ "GenMsgSendType" BO_ 829 8;
BA_ "GenMsgDelayTime" BO_ 829 10;
BA_ "VFrameFormat" BO_ 829 14;
BA_ "CANFD_BRS" BO_ 1056 1;
BA_ "GenMsgSendType" BO_ 1056 8;
BA_ "VFrameFormat" BO_ 1056 14;
BA_ "CANFD_BRS" BO_ 813 1;
BA_ "GenMsgSendType" BO_ 813 8;
BA_ "GenMsgDelayTime" BO_ 813 10;
BA_ "VFrameFormat" BO_ 813 14;
BA_ "CANFD_BRS" BO_ 1040 1;
BA_ "GenMsgSendType" BO_ 1040 8;
BA_ "VFrameFormat" BO_ 1040 14;
BA_ "CANFD_BRS" BO_ 797 1;
BA_ "GenMsgSendType" BO_ 797 8;
BA_ "GenMsgDelayTime" BO_ 797 10;
BA_ "VFrameFormat" BO_ 797 14;
BA_ "CANFD_BRS" BO_ 1088 1;
BA_ "GenMsgSendType" BO_ 1088 8;
BA_ "VFrameFormat" BO_ 1088 14;
BA_ "CANFD_BRS" BO_ 845 1;
BA_ "GenMsgSendType" BO_ 845 8;
BA_ "GenMsgDelayTime" BO_ 845 10;
BA_ "VFrameFormat" BO_ 845 14;
BA_ "CANFD_BRS" BO_ 828 1;
BA_ "GenMsgSendType" BO_ 828 8;
BA_ "GenMsgDelayTime" BO_ 828 10;
BA_ "VFrameFormat" BO_ 828 14;
BA_ "CANFD_BRS" BO_ 827 1;
BA_ "GenMsgSendType" BO_ 827 8;
BA_ "GenMsgDelayTime" BO_ 827 10;
BA_ "VFrameFormat" BO_ 827 14;
BA_ "CANFD_BRS" BO_ 826 1;
BA_ "GenMsgSendType" BO_ 826 8;
BA_ "GenMsgDelayTime" BO_ 826 10;
BA_ "VFrameFormat" BO_ 826 14;
BA_ "CANFD_BRS" BO_ 825 1;
BA_ "GenMsgSendType" BO_ 825 8;
BA_ "GenMsgDelayTime" BO_ 825 10;
BA_ "VFrameFormat" BO_ 825 14;
BA_ "CANFD_BRS" BO_ 824 1;
BA_ "GenMsgSendType" BO_ 824 8;
BA_ "GenMsgDelayTime" BO_ 824 10;
BA_ "VFrameFormat" BO_ 824 14;
BA_ "CANFD_BRS" BO_ 823 1;
BA_ "GenMsgSendType" BO_ 823 8;
BA_ "GenMsgDelayTime" BO_ 823 10;
BA_ "VFrameFormat" BO_ 823 14;
BA_ "CANFD_BRS" BO_ 822 1;
BA_ "GenMsgSendType" BO_ 822 8;
BA_ "GenMsgDelayTime" BO_ 822 10;
BA_ "VFrameFormat" BO_ 822 14;
BA_ "CANFD_BRS" BO_ 821 1;
BA_ "GenMsgSendType" BO_ 821 8;
BA_ "GenMsgDelayTime" BO_ 821 10;
BA_ "VFrameFormat" BO_ 821 14;
BA_ "CANFD_BRS" BO_ 820 1;
BA_ "GenMsgSendType" BO_ 820 8;
BA_ "GenMsgDelayTime" BO_ 820 10;
BA_ "VFrameFormat" BO_ 820 14;
BA_ "CANFD_BRS" BO_ 819 1;
BA_ "GenMsgSendType" BO_ 819 8;
BA_ "GenMsgDelayTime" BO_ 819 10;
BA_ "VFrameFormat" BO_ 819 14;
BA_ "CANFD_BRS" BO_ 818 1;
BA_ "GenMsgSendType" BO_ 818 8;
BA_ "GenMsgDelayTime" BO_ 818 10;
BA_ "VFrameFormat" BO_ 818 14;
BA_ "CANFD_BRS" BO_ 817 1;
BA_ "GenMsgSendType" BO_ 817 8;
BA_ "GenMsgDelayTime" BO_ 817 10;
BA_ "VFrameFormat" BO_ 817 14;
BA_ "GenSigSendType" SG_ 2671902706 FuncDiagDataTester 7;
BA_ "Platform_VMCU1_Sig" SG_ 2671902706 FuncDiagDataTester 1;
BA_ "GenSigSendType" SG_ 1754 Debug_10_SR_RR 1;
BA_ "GenSigSendType" SG_ 1753 Debug_09_SR_RR 1;
BA_ "GenSigSendType" SG_ 1752 Debug_08_SR_RR 1;
BA_ "GenSigSendType" SG_ 1751 Debug_07_SR_RR 1;
BA_ "GenSigSendType" SG_ 1750 Debug_06_SR_RR 1;
BA_ "GenSigSendType" SG_ 1749 Debug_05_SR_RR 1;
BA_ "GenSigSendType" SG_ 1748 Debug_04_SR_RR 1;
BA_ "GenSigSendType" SG_ 1747 Debug_03_SR_RR 1;
BA_ "GenSigSendType" SG_ 1746 Debug_02_SR_RR 1;
BA_ "GenSigSendType" SG_ 1745 Debug_01_SR_RR 1;
BA_ "GenSigSendType" SG_ 1738 Debug_10_SR_RF 1;
BA_ "GenSigSendType" SG_ 1737 Debug_09_SR_RF 1;
BA_ "GenSigSendType" SG_ 1736 Debug_08_SR_RF 1;
BA_ "GenSigSendType" SG_ 1735 Debug_07_SR_RF 1;
BA_ "GenSigSendType" SG_ 1734 Debug_06_SR_RF 1;
BA_ "GenSigSendType" SG_ 1733 Debug_05_SR_RF 1;
BA_ "GenSigSendType" SG_ 1732 Debug_04_SR_RF 1;
BA_ "GenSigSendType" SG_ 1731 Debug_03_SR_RF 1;
BA_ "GenSigSendType" SG_ 1730 Debug_02_SR_RF 1;
BA_ "GenSigSendType" SG_ 1729 Debug_01_SR_RF 1;
BA_ "GenSigSendType" SG_ 1722 Debug_10_SR_LR 1;
BA_ "GenSigSendType" SG_ 1721 Debug_09_SR_LR 1;
BA_ "GenSigSendType" SG_ 1720 Debug_08_SR_LR 1;
BA_ "GenSigSendType" SG_ 1719 Debug_07_SR_LR 1;
BA_ "GenSigSendType" SG_ 1718 Debug_06_SR_LR 1;
BA_ "GenSigSendType" SG_ 1717 Debug_05_SR_LR 1;
BA_ "GenSigSendType" SG_ 1716 Debug_04_SR_LR 1;
BA_ "GenSigSendType" SG_ 1715 Debug_03_SR_LR 1;
BA_ "GenSigSendType" SG_ 1714 Debug_02_SR_LR 1;
BA_ "GenSigSendType" SG_ 1713 Debug_01_SR_LR 1;
BA_ "GenSigSendType" SG_ 1706 Debug_10_SR_LF 1;
BA_ "GenSigSendType" SG_ 1705 Debug_09_SR_LF 1;
BA_ "GenSigSendType" SG_ 1704 Debug_08_SR_LF 1;
BA_ "GenSigSendType" SG_ 1703 Debug_07_SR_LF 1;
BA_ "GenSigSendType" SG_ 1702 Debug_06_SR_LF 1;
BA_ "GenSigSendType" SG_ 1701 Debug_05_SR_LF 1;
BA_ "GenSigSendType" SG_ 1700 Debug_04_SR_LF 1;
BA_ "GenSigSendType" SG_ 1699 Debug_03_SR_LF 1;
BA_ "GenSigSendType" SG_ 1698 Debug_02_SR_LF 1;
BA_ "GenSigSendType" SG_ 1697 Debug_01_SR_LF 1;
BA_ "GenSigSendType" SG_ 1072 RRSideSensorMALElevation 1;
BA_ "GenSigStartValue" SG_ 1072 RRSideSensorMALElevation 255;
BA_ "GenSigSendType" SG_ 1072 RRSideSensorMALAzimuth 1;
BA_ "GenSigStartValue" SG_ 1072 RRSideSensorMALAzimuth 255;
BA_ "GenSigSendType" SG_ 1072 RRSideSensorSafeState 1;
BA_ "GenSigStartValue" SG_ 1072 RRSideSensorSafeState 3;
BA_ "GenSigSendType" SG_ 829 SideRadarRR_CalibState 1;
BA_ "GenSigStartValue" SG_ 829 SideRadarRR_CalibState 3;
BA_ "GenSigSendType" SG_ 829 RRSRSensingRadarStat_DecalDetect 1;
BA_ "GenSigStartValue" SG_ 829 RRSRSensingRadarStat_DecalDetect 7;
BA_ "GenSigSendType" SG_ 829 RRSRSensingRadarStat_Counter 1;
BA_ "GenSigStartValue" SG_ 829 RRSRSensingRadarStat_Counter 255;
BA_ "GenSigSendType" SG_ 829 RRSRSideSensorStatus 1;
BA_ "GenSigStartValue" SG_ 829 RRSRSideSensorStatus 15;
BA_ "GenSigSendType" SG_ 829 SideRadarRR_CalibProgress 1;
BA_ "GenSigStartValue" SG_ 829 SideRadarRR_CalibProgress 127;
BA_ "GenSigSendType" SG_ 829 RRSRSensingRadarStat_Target 1;
BA_ "GenSigStartValue" SG_ 829 RRSRSensingRadarStat_Target 7;
BA_ "GenSigSendType" SG_ 829 RRSRSensingRadarStat_RoadEdge 1;
BA_ "GenSigStartValue" SG_ 829 RRSRSensingRadarStat_RoadEdge 7;
BA_ "GenSigSendType" SG_ 829 SideRadarRR_CalibPausedAcc 1;
BA_ "GenSigSendType" SG_ 829 RRSRSensingRadarStat_Trailer 1;
BA_ "GenSigStartValue" SG_ 829 RRSRSensingRadarStat_Trailer 7;
BA_ "GenSigSendType" SG_ 829 SideRadarRR_CalibPausedSpeed 1;
BA_ "GenSigSendType" SG_ 829 RRSRSensingRadarStat_TimeSynch 1;
BA_ "GenSigSendType" SG_ 829 RRSRSensingRadarStat_CRC 1;
BA_ "GenSigStartValue" SG_ 829 RRSRSensingRadarStat_CRC 65535;
BA_ "E2EDataId" SG_ 829 RRSRSensingRadarStat_CRC 160;
BA_ "E2EDataLength" SG_ 829 RRSRSensingRadarStat_CRC 48;
BA_ "E2EProfile" SG_ 829 RRSRSensingRadarStat_CRC "P05";
BA_ "GenSigSendType" SG_ 829 SideRadarRR_CalibPausedYaw 1;
BA_ "GenSigSendType" SG_ 1056 RFSideSensorSafeState 1;
BA_ "GenSigStartValue" SG_ 1056 RFSideSensorSafeState 3;
BA_ "GenSigSendType" SG_ 1056 RFSideSensorMALElevation 1;
BA_ "GenSigStartValue" SG_ 1056 RFSideSensorMALElevation 255;
BA_ "GenSigSendType" SG_ 1056 RFSideSensorMALAzimuth 1;
BA_ "GenSigStartValue" SG_ 1056 RFSideSensorMALAzimuth 255;
BA_ "GenSigSendType" SG_ 813 RFSRSensingRadarStat_Counter 1;
BA_ "GenSigStartValue" SG_ 813 RFSRSensingRadarStat_Counter 255;
BA_ "GenSigSendType" SG_ 813 RFSRSensingRadarStat_CRC 1;
BA_ "GenSigStartValue" SG_ 813 RFSRSensingRadarStat_CRC 65535;
BA_ "E2EDataId" SG_ 813 RFSRSensingRadarStat_CRC 159;
BA_ "E2EDataLength" SG_ 813 RFSRSensingRadarStat_CRC 48;
BA_ "E2EProfile" SG_ 813 RFSRSensingRadarStat_CRC "P05";
BA_ "GenSigSendType" SG_ 813 SideRadarRF_CalibProgress 1;
BA_ "GenSigStartValue" SG_ 813 SideRadarRF_CalibProgress 127;
BA_ "GenSigSendType" SG_ 813 RFSRSensingRadarStat_RoadEdge 1;
BA_ "GenSigStartValue" SG_ 813 RFSRSensingRadarStat_RoadEdge 7;
BA_ "GenSigSendType" SG_ 813 SideRadarRF_CalibPausedAcc 1;
BA_ "GenSigSendType" SG_ 813 SideRadarRF_CalibPausedSpeed 1;
BA_ "GenSigSendType" SG_ 813 SideRadarRF_CalibPausedYaw 1;
BA_ "GenSigSendType" SG_ 813 RFSRSideSensorStatus 1;
BA_ "GenSigStartValue" SG_ 813 RFSRSideSensorStatus 15;
BA_ "GenSigSendType" SG_ 813 RFSRSensingRadarStat_TimeSynch 1;
BA_ "GenSigSendType" SG_ 813 RFSRSensingRadarStat_Target 1;
BA_ "GenSigStartValue" SG_ 813 RFSRSensingRadarStat_Target 7;
BA_ "GenSigSendType" SG_ 813 SideRadarRF_CalibState 1;
BA_ "GenSigStartValue" SG_ 813 SideRadarRF_CalibState 3;
BA_ "GenSigSendType" SG_ 813 RFSRSensingRadarStat_DecalDetect 1;
BA_ "GenSigStartValue" SG_ 813 RFSRSensingRadarStat_DecalDetect 7;
BA_ "GenSigSendType" SG_ 813 RFSRSensingRadarStat_Trailer 1;
BA_ "GenSigStartValue" SG_ 813 RFSRSensingRadarStat_Trailer 7;
BA_ "GenSigSendType" SG_ 1040 LRSideSensorMALElevation 1;
BA_ "GenSigStartValue" SG_ 1040 LRSideSensorMALElevation 255;
BA_ "GenSigSendType" SG_ 1040 LRSideSensorSafeState 1;
BA_ "GenSigStartValue" SG_ 1040 LRSideSensorSafeState 3;
BA_ "GenSigSendType" SG_ 1040 LRSideSensorMALAzimuth 1;
BA_ "GenSigStartValue" SG_ 1040 LRSideSensorMALAzimuth 255;
BA_ "GenSigSendType" SG_ 797 LRSRSensingRadarStat_RoadEdge 1;
BA_ "GenSigStartValue" SG_ 797 LRSRSensingRadarStat_RoadEdge 7;
BA_ "GenSigSendType" SG_ 797 SideRadarLR_CalibState 1;
BA_ "GenSigStartValue" SG_ 797 SideRadarLR_CalibState 3;
BA_ "GenSigSendType" SG_ 797 LRSRSensingRadarStat_Counter 1;
BA_ "GenSigStartValue" SG_ 797 LRSRSensingRadarStat_Counter 255;
BA_ "GenSigSendType" SG_ 797 LRSRSensingRadarStat_CRC 1;
BA_ "GenSigStartValue" SG_ 797 LRSRSensingRadarStat_CRC 65535;
BA_ "E2EDataId" SG_ 797 LRSRSensingRadarStat_CRC 158;
BA_ "E2EDataLength" SG_ 797 LRSRSensingRadarStat_CRC 48;
BA_ "E2EProfile" SG_ 797 LRSRSensingRadarStat_CRC "P05";
BA_ "GenSigSendType" SG_ 797 LRSRSensingRadarStat_Target 1;
BA_ "GenSigStartValue" SG_ 797 LRSRSensingRadarStat_Target 7;
BA_ "GenSigSendType" SG_ 797 SideRadarLR_CalibPausedAcc 1;
BA_ "GenSigSendType" SG_ 797 SideRadarLR_CalibPausedYaw 1;
BA_ "GenSigSendType" SG_ 797 LRSRSideSensorStatus 1;
BA_ "GenSigStartValue" SG_ 797 LRSRSideSensorStatus 15;
BA_ "GenSigSendType" SG_ 797 SideRadarLR_CalibProgress 1;
BA_ "GenSigStartValue" SG_ 797 SideRadarLR_CalibProgress 127;
BA_ "GenSigSendType" SG_ 797 SideRadarLR_CalibPausedSpeed 1;
BA_ "GenSigSendType" SG_ 797 LRSRSensingRadarStat_TimeSynch 1;
BA_ "GenSigSendType" SG_ 797 LRSRSensingRadarStat_Trailer 1;
BA_ "GenSigStartValue" SG_ 797 LRSRSensingRadarStat_Trailer 7;
BA_ "GenSigSendType" SG_ 797 LRSRSensingRadarStat_DecalDetect 1;
BA_ "GenSigStartValue" SG_ 797 LRSRSensingRadarStat_DecalDetect 7;
BA_ "GenSigSendType" SG_ 1088 LFSideSensorMALElevation 1;
BA_ "GenSigStartValue" SG_ 1088 LFSideSensorMALElevation 255;
BA_ "GenSigSendType" SG_ 1088 LFSideSensorSafeState 1;
BA_ "GenSigStartValue" SG_ 1088 LFSideSensorSafeState 3;
BA_ "GenSigSendType" SG_ 1088 LFSideSensorMALAzimuth 1;
BA_ "GenSigStartValue" SG_ 1088 LFSideSensorMALAzimuth 255;
BA_ "GenSigSendType" SG_ 845 LFSRSensingRadarStat_DecalDetect 1;
BA_ "GenSigStartValue" SG_ 845 LFSRSensingRadarStat_DecalDetect 7;
BA_ "GenSigSendType" SG_ 845 SideRadarLF_CalibPausedSpeed 1;
BA_ "GenSigSendType" SG_ 845 SideRadarLF_CalibState 1;
BA_ "GenSigStartValue" SG_ 845 SideRadarLF_CalibState 3;
BA_ "GenSigSendType" SG_ 845 SideRadarLF_CalibPausedYaw 1;
BA_ "GenSigSendType" SG_ 845 LFSRSensingRadarStat_Counter 1;
BA_ "GenSigStartValue" SG_ 845 LFSRSensingRadarStat_Counter 255;
BA_ "GenSigSendType" SG_ 845 LFSRSensingRadarStat_Target 1;
BA_ "GenSigStartValue" SG_ 845 LFSRSensingRadarStat_Target 7;
BA_ "GenSigSendType" SG_ 845 LFSRSideSensorStatus 1;
BA_ "GenSigStartValue" SG_ 845 LFSRSideSensorStatus 15;
BA_ "GenSigSendType" SG_ 845 LFSRSensingRadarStat_TimeSynch 1;
BA_ "GenSigSendType" SG_ 845 LFSRSensingRadarStat_CRC 1;
BA_ "GenSigStartValue" SG_ 845 LFSRSensingRadarStat_CRC 65535;
BA_ "E2EDataId" SG_ 845 LFSRSensingRadarStat_CRC 157;
BA_ "E2EDataLength" SG_ 845 LFSRSensingRadarStat_CRC 48;
BA_ "E2EProfile" SG_ 845 LFSRSensingRadarStat_CRC "P05";
BA_ "GenSigSendType" SG_ 845 LFSRSensingRadarStat_RoadEdge 1;
BA_ "GenSigStartValue" SG_ 845 LFSRSensingRadarStat_RoadEdge 7;
BA_ "GenSigSendType" SG_ 845 SideRadarLF_CalibProgress 1;
BA_ "GenSigStartValue" SG_ 845 SideRadarLF_CalibProgress 127;
BA_ "GenSigSendType" SG_ 845 LFSRSensingRadarStat_Trailer 1;
BA_ "GenSigStartValue" SG_ 845 LFSRSensingRadarStat_Trailer 7;
BA_ "GenSigSendType" SG_ 845 SideRadarLF_CalibPausedAcc 1;
BA_ "GenSigSendType" SG_ 828 RRSideSensorTrlrObj_TrlAnglConf 1;
BA_ "GenSigStartValue" SG_ 828 RRSideSensorTrlrObj_TrlAnglConf 127;
BA_ "GenSigSendType" SG_ 828 RRSideSensorTrlrObj_Seg3Length 1;
BA_ "GenSigStartValue" SG_ 828 RRSideSensorTrlrObj_Seg3Length 511;
BA_ "GenSigSendType" SG_ 828 RRSideSensorTrlrObj_SegTrlrType1 1;
BA_ "GenSigStartValue" SG_ 828 RRSideSensorTrlrObj_SegTrlrType1 15;
BA_ "GenSigSendType" SG_ 828 RRSideSensorTrlrObj_SegAngle4 1;
BA_ "GenSigStartValue" SG_ 828 RRSideSensorTrlrObj_SegAngle4 4095;
BA_ "GenSigSendType" SG_ 828 RRSideSensorTrlrObj_WheelBased2 1;
BA_ "GenSigStartValue" SG_ 828 RRSideSensorTrlrObj_WheelBased2 2047;
BA_ "GenSigSendType" SG_ 828 RRSideSensorTrlrObj_SegAngle3 1;
BA_ "GenSigStartValue" SG_ 828 RRSideSensorTrlrObj_SegAngle3 4095;
BA_ "GenSigSendType" SG_ 828 RRSideSensorTrlrObj_SegAngle5 1;
BA_ "GenSigStartValue" SG_ 828 RRSideSensorTrlrObj_SegAngle5 4095;
BA_ "GenSigSendType" SG_ 828 RRSideSensorTrlrObj_SegTrlrType5 1;
BA_ "GenSigStartValue" SG_ 828 RRSideSensorTrlrObj_SegTrlrType5 15;
BA_ "GenSigSendType" SG_ 828 RRSideSensorTrlrObj_WheelBased1 1;
BA_ "GenSigStartValue" SG_ 828 RRSideSensorTrlrObj_WheelBased1 2047;
BA_ "GenSigSendType" SG_ 828 RRSideSensorTrlrObj_SegTrlrType4 1;
BA_ "GenSigStartValue" SG_ 828 RRSideSensorTrlrObj_SegTrlrType4 15;
BA_ "GenSigSendType" SG_ 828 RRSideSensorTrlrObj_WheelBased5 1;
BA_ "GenSigStartValue" SG_ 828 RRSideSensorTrlrObj_WheelBased5 2047;
BA_ "GenSigSendType" SG_ 828 RRSideSensorTrlrObj_SegAngle1 1;
BA_ "GenSigStartValue" SG_ 828 RRSideSensorTrlrObj_SegAngle1 4095;
BA_ "GenSigSendType" SG_ 828 RRSideSensorTrlrObj_Seg5Length 1;
BA_ "GenSigStartValue" SG_ 828 RRSideSensorTrlrObj_Seg5Length 511;
BA_ "GenSigSendType" SG_ 828 RRSideSensorTrlrObj_SegTrlrType3 1;
BA_ "GenSigStartValue" SG_ 828 RRSideSensorTrlrObj_SegTrlrType3 15;
BA_ "GenSigSendType" SG_ 828 RRSideSensorTrlrObj_WheelBased4 1;
BA_ "GenSigStartValue" SG_ 828 RRSideSensorTrlrObj_WheelBased4 2047;
BA_ "GenSigSendType" SG_ 828 RRSideSensorTrlrObj_Seg4Length 1;
BA_ "GenSigStartValue" SG_ 828 RRSideSensorTrlrObj_Seg4Length 511;
BA_ "GenSigSendType" SG_ 828 RRSideSensorTrlrObj_WhlBasedConf 1;
BA_ "GenSigStartValue" SG_ 828 RRSideSensorTrlrObj_WhlBasedConf 127;
BA_ "GenSigSendType" SG_ 828 RRSideSensorTrlrObj_Seg1Length 1;
BA_ "GenSigStartValue" SG_ 828 RRSideSensorTrlrObj_Seg1Length 511;
BA_ "GenSigSendType" SG_ 828 RRSideSensorTrlrObj_SegTrlrType2 1;
BA_ "GenSigStartValue" SG_ 828 RRSideSensorTrlrObj_SegTrlrType2 15;
BA_ "GenSigSendType" SG_ 828 RRSideSensorTrlrObj_SegAngle2 1;
BA_ "GenSigStartValue" SG_ 828 RRSideSensorTrlrObj_SegAngle2 4095;
BA_ "GenSigSendType" SG_ 828 RRSideSensorTrlrObj_WheelBased3 1;
BA_ "GenSigStartValue" SG_ 828 RRSideSensorTrlrObj_WheelBased3 2047;
BA_ "GenSigSendType" SG_ 828 RRSideSensorTrlrObj_TotLenConf 1;
BA_ "GenSigStartValue" SG_ 828 RRSideSensorTrlrObj_TotLenConf 7;
BA_ "GenSigSendType" SG_ 828 RRSideSensorTrlrObj_TrlrTypeConf 1;
BA_ "GenSigStartValue" SG_ 828 RRSideSensorTrlrObj_TrlrTypeConf 127;
BA_ "GenSigSendType" SG_ 828 RRSideSensorTrlrObj_Seg2Length 1;
BA_ "GenSigStartValue" SG_ 828 RRSideSensorTrlrObj_Seg2Length 511;
BA_ "GenSigSendType" SG_ 828 RRSideSensorTrlrObj_TotalLength 1;
BA_ "GenSigStartValue" SG_ 828 RRSideSensorTrlrObj_TotalLength 2047;
BA_ "GenSigSendType" SG_ 827 RRSideSensorObj11_TrackStatus 1;
BA_ "GenSigStartValue" SG_ 827 RRSideSensorObj11_TrackStatus 7;
BA_ "GenSigSendType" SG_ 827 RRSideSensorObj11_CoastIndex 1;
BA_ "GenSigStartValue" SG_ 827 RRSideSensorObj11_CoastIndex 31;
BA_ "GenSigSendType" SG_ 827 RRSideSensorObj11_ExistConf 1;
BA_ "GenSigStartValue" SG_ 827 RRSideSensorObj11_ExistConf 127;
BA_ "GenSigSendType" SG_ 827 RRSideSensorObj11_LatExtLeft 1;
BA_ "GenSigStartValue" SG_ 827 RRSideSensorObj11_LatExtLeft 127;
BA_ "GenSigSendType" SG_ 827 RRSideSensorObj11_CRC 1;
BA_ "GenSigStartValue" SG_ 827 RRSideSensorObj11_CRC 65535;
BA_ "E2EDataId" SG_ 827 RRSideSensorObj11_CRC 65;
BA_ "E2EDataLength" SG_ 827 RRSideSensorObj11_CRC 312;
BA_ "E2EProfile" SG_ 827 RRSideSensorObj11_CRC "P05";
BA_ "GenSigSendType" SG_ 827 RRSideSensorObj11_LongExtBkVar 1;
BA_ "GenSigStartValue" SG_ 827 RRSideSensorObj11_LongExtBkVar 255;
BA_ "GenSigSendType" SG_ 827 RRSideSensorObj11_MOISPrio 1;
BA_ "GenSigSendType" SG_ 827 RRSideSensorObj11_LongPosVar 1;
BA_ "GenSigStartValue" SG_ 827 RRSideSensorObj11_LongPosVar 255;
BA_ "GenSigSendType" SG_ 827 RRSideSensorObj11_ObjClass 1;
BA_ "GenSigStartValue" SG_ 827 RRSideSensorObj11_ObjClass 15;
BA_ "GenSigSendType" SG_ 827 RRSideSensorObj11_LatVel 1;
BA_ "GenSigStartValue" SG_ 827 RRSideSensorObj11_LatVel 8191;
BA_ "GenSigSendType" SG_ 827 RRSideSensorObj11_LatExtLeftVar 1;
BA_ "GenSigStartValue" SG_ 827 RRSideSensorObj11_LatExtLeftVar 255;
BA_ "GenSigSendType" SG_ 827 RRSideSensorObj11_LatPos 1;
BA_ "GenSigStartValue" SG_ 827 RRSideSensorObj11_LatPos 8191;
BA_ "GenSigSendType" SG_ 827 RRSideSensorObj11_LongExtFront 1;
BA_ "GenSigStartValue" SG_ 827 RRSideSensorObj11_LongExtFront 1023;
BA_ "GenSigSendType" SG_ 827 RRSideSensorObj11_LongAcc 1;
BA_ "GenSigStartValue" SG_ 827 RRSideSensorObj11_LongAcc 511;
BA_ "GenSigSendType" SG_ 827 RRSideSensorObj11_LifeTime 1;
BA_ "GenSigStartValue" SG_ 827 RRSideSensorObj11_LifeTime 65535;
BA_ "GenSigSendType" SG_ 827 RRSideSensorObj11_LongVelVar 1;
BA_ "GenSigStartValue" SG_ 827 RRSideSensorObj11_LongVelVar 255;
BA_ "GenSigSendType" SG_ 827 RRSideSensorObj11_TimeStamp 1;
BA_ "GenSigStartValue" SG_ 827 RRSideSensorObj11_TimeStamp 65535;
BA_ "GenSigSendType" SG_ 827 RRSideSensorObj11_LatAcc 1;
BA_ "GenSigStartValue" SG_ 827 RRSideSensorObj11_LatAcc 511;
BA_ "GenSigSendType" SG_ 827 RRSideSensorObj11_HeadingVar 1;
BA_ "GenSigStartValue" SG_ 827 RRSideSensorObj11_HeadingVar 255;
BA_ "GenSigSendType" SG_ 827 RRSideSensorObj11_Counter 1;
BA_ "GenSigStartValue" SG_ 827 RRSideSensorObj11_Counter 255;
BA_ "GenSigSendType" SG_ 827 RRSideSensorObj11_LatPosVar 1;
BA_ "GenSigStartValue" SG_ 827 RRSideSensorObj11_LatPosVar 255;
BA_ "GenSigSendType" SG_ 827 RRSideSensorObj11_LongPos 1;
BA_ "GenSigStartValue" SG_ 827 RRSideSensorObj11_LongPos 8191;
BA_ "GenSigSendType" SG_ 827 RRSideSensorObj11_LongVel 1;
BA_ "GenSigStartValue" SG_ 827 RRSideSensorObj11_LongVel 8191;
BA_ "GenSigSendType" SG_ 827 RRSideSensorObj11_ObjID 1;
BA_ "GenSigStartValue" SG_ 827 RRSideSensorObj11_ObjID 63;
BA_ "GenSigSendType" SG_ 827 RRSideSensorObj11_ObstacleConf 1;
BA_ "GenSigStartValue" SG_ 827 RRSideSensorObj11_ObstacleConf 127;
BA_ "GenSigSendType" SG_ 827 RRSideSensorObj11_LatExtRight 1;
BA_ "GenSigStartValue" SG_ 827 RRSideSensorObj11_LatExtRight 127;
BA_ "GenSigSendType" SG_ 827 RRSideSensorObj11_LongExtBack 1;
BA_ "GenSigStartValue" SG_ 827 RRSideSensorObj11_LongExtBack 1023;
BA_ "GenSigSendType" SG_ 827 RRSideSensorObj11_ObjClassConf 1;
BA_ "GenSigStartValue" SG_ 827 RRSideSensorObj11_ObjClassConf 15;
BA_ "GenSigSendType" SG_ 827 RRSideSensorObj11_LatVelVar 1;
BA_ "GenSigStartValue" SG_ 827 RRSideSensorObj11_LatVelVar 255;
BA_ "GenSigSendType" SG_ 827 RRSideSensorObj11_Heading 1;
BA_ "GenSigStartValue" SG_ 827 RRSideSensorObj11_Heading 2047;
BA_ "GenSigSendType" SG_ 827 RRSideSensorObj11_Height 1;
BA_ "GenSigStartValue" SG_ 827 RRSideSensorObj11_Height 255;
BA_ "GenSigSendType" SG_ 827 RRSideSensorObj11_LatAccVar 1;
BA_ "GenSigStartValue" SG_ 827 RRSideSensorObj11_LatAccVar 255;
BA_ "GenSigSendType" SG_ 827 RRSideSensorObj11_LongAccVar 1;
BA_ "GenSigStartValue" SG_ 827 RRSideSensorObj11_LongAccVar 255;
BA_ "GenSigSendType" SG_ 827 RRSideSensorObj11_LatExtRtVar 1;
BA_ "GenSigStartValue" SG_ 827 RRSideSensorObj11_LatExtRtVar 255;
BA_ "GenSigSendType" SG_ 827 RRSideSensorObj11_LongExtFrVar 1;
BA_ "GenSigStartValue" SG_ 827 RRSideSensorObj11_LongExtFrVar 255;
BA_ "GenSigSendType" SG_ 827 RRSideSensorObj11_ObjDynClass 1;
BA_ "GenSigStartValue" SG_ 827 RRSideSensorObj11_ObjDynClass 3;
BA_ "GenSigSendType" SG_ 827 RRSideSensorObj11_Prioritisation 1;
BA_ "GenSigStartValue" SG_ 827 RRSideSensorObj11_Prioritisation 3;
BA_ "GenSigSendType" SG_ 826 RRSideSensorObj10_Counter 1;
BA_ "GenSigStartValue" SG_ 826 RRSideSensorObj10_Counter 255;
BA_ "GenSigSendType" SG_ 826 RRSideSensorObj10_LatExtRight 1;
BA_ "GenSigStartValue" SG_ 826 RRSideSensorObj10_LatExtRight 127;
BA_ "GenSigSendType" SG_ 826 RRSideSensorObj10_ObjClassConf 1;
BA_ "GenSigStartValue" SG_ 826 RRSideSensorObj10_ObjClassConf 15;
BA_ "GenSigSendType" SG_ 826 RRSideSensorObj10_ObjDynClass 1;
BA_ "GenSigStartValue" SG_ 826 RRSideSensorObj10_ObjDynClass 3;
BA_ "GenSigSendType" SG_ 826 RRSideSensorObj10_Prioritisation 1;
BA_ "GenSigStartValue" SG_ 826 RRSideSensorObj10_Prioritisation 3;
BA_ "GenSigSendType" SG_ 826 RRSideSensorObj10_ObjClass 1;
BA_ "GenSigStartValue" SG_ 826 RRSideSensorObj10_ObjClass 15;
BA_ "GenSigSendType" SG_ 826 RRSideSensorObj10_LatPosVar 1;
BA_ "GenSigStartValue" SG_ 826 RRSideSensorObj10_LatPosVar 255;
BA_ "GenSigSendType" SG_ 826 RRSideSensorObj10_Height 1;
BA_ "GenSigStartValue" SG_ 826 RRSideSensorObj10_Height 255;
BA_ "GenSigSendType" SG_ 826 RRSideSensorObj10_LatExtRtVar 1;
BA_ "GenSigStartValue" SG_ 826 RRSideSensorObj10_LatExtRtVar 255;
BA_ "GenSigSendType" SG_ 826 RRSideSensorObj10_LatExtLeft 1;
BA_ "GenSigStartValue" SG_ 826 RRSideSensorObj10_LatExtLeft 127;
BA_ "GenSigSendType" SG_ 826 RRSideSensorObj10_LongAccVar 1;
BA_ "GenSigStartValue" SG_ 826 RRSideSensorObj10_LongAccVar 255;
BA_ "GenSigSendType" SG_ 826 RRSideSensorObj10_LongExtBack 1;
BA_ "GenSigStartValue" SG_ 826 RRSideSensorObj10_LongExtBack 1023;
BA_ "GenSigSendType" SG_ 826 RRSideSensorObj10_HeadingVar 1;
BA_ "GenSigStartValue" SG_ 826 RRSideSensorObj10_HeadingVar 255;
BA_ "GenSigSendType" SG_ 826 RRSideSensorObj10_CRC 1;
BA_ "GenSigStartValue" SG_ 826 RRSideSensorObj10_CRC 65535;
BA_ "E2EDataId" SG_ 826 RRSideSensorObj10_CRC 64;
BA_ "E2EDataLength" SG_ 826 RRSideSensorObj10_CRC 312;
BA_ "E2EProfile" SG_ 826 RRSideSensorObj10_CRC "P05";
BA_ "GenSigSendType" SG_ 826 RRSideSensorObj10_LongExtBkVar 1;
BA_ "GenSigStartValue" SG_ 826 RRSideSensorObj10_LongExtBkVar 255;
BA_ "GenSigSendType" SG_ 826 RRSideSensorObj10_TrackStatus 1;
BA_ "GenSigStartValue" SG_ 826 RRSideSensorObj10_TrackStatus 7;
BA_ "GenSigSendType" SG_ 826 RRSideSensorObj10_LongVelVar 1;
BA_ "GenSigStartValue" SG_ 826 RRSideSensorObj10_LongVelVar 255;
BA_ "GenSigSendType" SG_ 826 RRSideSensorObj10_ObjID 1;
BA_ "GenSigStartValue" SG_ 826 RRSideSensorObj10_ObjID 63;
BA_ "GenSigSendType" SG_ 826 RRSideSensorObj10_LatExtLeftVar 1;
BA_ "GenSigStartValue" SG_ 826 RRSideSensorObj10_LatExtLeftVar 255;
BA_ "GenSigSendType" SG_ 826 RRSideSensorObj10_LongAcc 1;
BA_ "GenSigStartValue" SG_ 826 RRSideSensorObj10_LongAcc 511;
BA_ "GenSigSendType" SG_ 826 RRSideSensorObj10_ExistConf 1;
BA_ "GenSigStartValue" SG_ 826 RRSideSensorObj10_ExistConf 127;
BA_ "GenSigSendType" SG_ 826 RRSideSensorObj10_Heading 1;
BA_ "GenSigStartValue" SG_ 826 RRSideSensorObj10_Heading 2047;
BA_ "GenSigSendType" SG_ 826 RRSideSensorObj10_LatAccVar 1;
BA_ "GenSigStartValue" SG_ 826 RRSideSensorObj10_LatAccVar 255;
BA_ "GenSigSendType" SG_ 826 RRSideSensorObj10_LatAcc 1;
BA_ "GenSigStartValue" SG_ 826 RRSideSensorObj10_LatAcc 511;
BA_ "GenSigSendType" SG_ 826 RRSideSensorObj10_LongExtFront 1;
BA_ "GenSigStartValue" SG_ 826 RRSideSensorObj10_LongExtFront 1023;
BA_ "GenSigSendType" SG_ 826 RRSideSensorObj10_LongExtFrVar 1;
BA_ "GenSigStartValue" SG_ 826 RRSideSensorObj10_LongExtFrVar 255;
BA_ "GenSigSendType" SG_ 826 RRSideSensorObj10_LatVel 1;
BA_ "GenSigStartValue" SG_ 826 RRSideSensorObj10_LatVel 8191;
BA_ "GenSigSendType" SG_ 826 RRSideSensorObj10_LongPos 1;
BA_ "GenSigStartValue" SG_ 826 RRSideSensorObj10_LongPos 8191;
BA_ "GenSigSendType" SG_ 826 RRSideSensorObj10_LatPos 1;
BA_ "GenSigStartValue" SG_ 826 RRSideSensorObj10_LatPos 8191;
BA_ "GenSigSendType" SG_ 826 RRSideSensorObj10_LongPosVar 1;
BA_ "GenSigStartValue" SG_ 826 RRSideSensorObj10_LongPosVar 255;
BA_ "GenSigSendType" SG_ 826 RRSideSensorObj10_LongVel 1;
BA_ "GenSigStartValue" SG_ 826 RRSideSensorObj10_LongVel 8191;
BA_ "GenSigSendType" SG_ 826 RRSideSensorObj10_ObstacleConf 1;
BA_ "GenSigStartValue" SG_ 826 RRSideSensorObj10_ObstacleConf 127;
BA_ "GenSigSendType" SG_ 826 RRSideSensorObj10_MOISPrio 1;
BA_ "GenSigSendType" SG_ 826 RRSideSensorObj10_TimeStamp 1;
BA_ "GenSigStartValue" SG_ 826 RRSideSensorObj10_TimeStamp 65535;
BA_ "GenSigSendType" SG_ 826 RRSideSensorObj10_LifeTime 1;
BA_ "GenSigStartValue" SG_ 826 RRSideSensorObj10_LifeTime 65535;
BA_ "GenSigSendType" SG_ 826 RRSideSensorObj10_CoastIndex 1;
BA_ "GenSigStartValue" SG_ 826 RRSideSensorObj10_CoastIndex 31;
BA_ "GenSigSendType" SG_ 826 RRSideSensorObj10_LatVelVar 1;
BA_ "GenSigStartValue" SG_ 826 RRSideSensorObj10_LatVelVar 255;
BA_ "GenSigSendType" SG_ 825 RRSideSensorObj09_LatExtRight 1;
BA_ "GenSigStartValue" SG_ 825 RRSideSensorObj09_LatExtRight 127;
BA_ "GenSigSendType" SG_ 825 RRSideSensorObj09_LongPosVar 1;
BA_ "GenSigStartValue" SG_ 825 RRSideSensorObj09_LongPosVar 255;
BA_ "GenSigSendType" SG_ 825 RRSideSensorObj09_Height 1;
BA_ "GenSigStartValue" SG_ 825 RRSideSensorObj09_Height 255;
BA_ "GenSigSendType" SG_ 825 RRSideSensorObj09_LongAccVar 1;
BA_ "GenSigStartValue" SG_ 825 RRSideSensorObj09_LongAccVar 255;
BA_ "GenSigSendType" SG_ 825 RRSideSensorObj09_LongExtBack 1;
BA_ "GenSigStartValue" SG_ 825 RRSideSensorObj09_LongExtBack 1023;
BA_ "GenSigSendType" SG_ 825 RRSideSensorObj09_LatPosVar 1;
BA_ "GenSigStartValue" SG_ 825 RRSideSensorObj09_LatPosVar 255;
BA_ "GenSigSendType" SG_ 825 RRSideSensorObj09_LatVelVar 1;
BA_ "GenSigStartValue" SG_ 825 RRSideSensorObj09_LatVelVar 255;
BA_ "GenSigSendType" SG_ 825 RRSideSensorObj09_LatVel 1;
BA_ "GenSigStartValue" SG_ 825 RRSideSensorObj09_LatVel 8191;
BA_ "GenSigSendType" SG_ 825 RRSideSensorObj09_LatExtLeft 1;
BA_ "GenSigStartValue" SG_ 825 RRSideSensorObj09_LatExtLeft 127;
BA_ "GenSigSendType" SG_ 825 RRSideSensorObj09_HeadingVar 1;
BA_ "GenSigStartValue" SG_ 825 RRSideSensorObj09_HeadingVar 255;
BA_ "GenSigSendType" SG_ 825 RRSideSensorObj09_LatExtRtVar 1;
BA_ "GenSigStartValue" SG_ 825 RRSideSensorObj09_LatExtRtVar 255;
BA_ "GenSigSendType" SG_ 825 RRSideSensorObj09_ObjClassConf 1;
BA_ "GenSigStartValue" SG_ 825 RRSideSensorObj09_ObjClassConf 15;
BA_ "GenSigSendType" SG_ 825 RRSideSensorObj09_CoastIndex 1;
BA_ "GenSigStartValue" SG_ 825 RRSideSensorObj09_CoastIndex 31;
BA_ "GenSigSendType" SG_ 825 RRSideSensorObj09_ObjDynClass 1;
BA_ "GenSigStartValue" SG_ 825 RRSideSensorObj09_ObjDynClass 3;
BA_ "GenSigSendType" SG_ 825 RRSideSensorObj09_LongExtFrVar 1;
BA_ "GenSigStartValue" SG_ 825 RRSideSensorObj09_LongExtFrVar 255;
BA_ "GenSigSendType" SG_ 825 RRSideSensorObj09_LongPos 1;
BA_ "GenSigStartValue" SG_ 825 RRSideSensorObj09_LongPos 8191;
BA_ "GenSigSendType" SG_ 825 RRSideSensorObj09_Counter 1;
BA_ "GenSigStartValue" SG_ 825 RRSideSensorObj09_Counter 255;
BA_ "GenSigSendType" SG_ 825 RRSideSensorObj09_CRC 1;
BA_ "GenSigStartValue" SG_ 825 RRSideSensorObj09_CRC 65535;
BA_ "E2EDataId" SG_ 825 RRSideSensorObj09_CRC 63;
BA_ "E2EDataLength" SG_ 825 RRSideSensorObj09_CRC 312;
BA_ "E2EProfile" SG_ 825 RRSideSensorObj09_CRC "P05";
BA_ "GenSigSendType" SG_ 825 RRSideSensorObj09_LatAcc 1;
BA_ "GenSigStartValue" SG_ 825 RRSideSensorObj09_LatAcc 511;
BA_ "GenSigSendType" SG_ 825 RRSideSensorObj09_LongExtBkVar 1;
BA_ "GenSigStartValue" SG_ 825 RRSideSensorObj09_LongExtBkVar 255;
BA_ "GenSigSendType" SG_ 825 RRSideSensorObj09_Heading 1;
BA_ "GenSigStartValue" SG_ 825 RRSideSensorObj09_Heading 2047;
BA_ "GenSigSendType" SG_ 825 RRSideSensorObj09_LatAccVar 1;
BA_ "GenSigStartValue" SG_ 825 RRSideSensorObj09_LatAccVar 255;
BA_ "GenSigSendType" SG_ 825 RRSideSensorObj09_ObjClass 1;
BA_ "GenSigStartValue" SG_ 825 RRSideSensorObj09_ObjClass 15;
BA_ "GenSigSendType" SG_ 825 RRSideSensorObj09_Prioritisation 1;
BA_ "GenSigStartValue" SG_ 825 RRSideSensorObj09_Prioritisation 3;
BA_ "GenSigSendType" SG_ 825 RRSideSensorObj09_LongVel 1;
BA_ "GenSigStartValue" SG_ 825 RRSideSensorObj09_LongVel 8191;
BA_ "GenSigSendType" SG_ 825 RRSideSensorObj09_TrackStatus 1;
BA_ "GenSigStartValue" SG_ 825 RRSideSensorObj09_TrackStatus 7;
BA_ "GenSigSendType" SG_ 825 RRSideSensorObj09_LongExtFront 1;
BA_ "GenSigStartValue" SG_ 825 RRSideSensorObj09_LongExtFront 1023;
BA_ "GenSigSendType" SG_ 825 RRSideSensorObj09_LatExtLeftVar 1;
BA_ "GenSigStartValue" SG_ 825 RRSideSensorObj09_LatExtLeftVar 255;
BA_ "GenSigSendType" SG_ 825 RRSideSensorObj09_TimeStamp 1;
BA_ "GenSigStartValue" SG_ 825 RRSideSensorObj09_TimeStamp 65535;
BA_ "GenSigSendType" SG_ 825 RRSideSensorObj09_ObjID 1;
BA_ "GenSigStartValue" SG_ 825 RRSideSensorObj09_ObjID 63;
BA_ "GenSigSendType" SG_ 825 RRSideSensorObj09_LongAcc 1;
BA_ "GenSigStartValue" SG_ 825 RRSideSensorObj09_LongAcc 511;
BA_ "GenSigSendType" SG_ 825 RRSideSensorObj09_LatPos 1;
BA_ "GenSigStartValue" SG_ 825 RRSideSensorObj09_LatPos 8191;
BA_ "GenSigSendType" SG_ 825 RRSideSensorObj09_ObstacleConf 1;
BA_ "GenSigStartValue" SG_ 825 RRSideSensorObj09_ObstacleConf 127;
BA_ "GenSigSendType" SG_ 825 RRSideSensorObj09_MOISPrio 1;
BA_ "GenSigSendType" SG_ 825 RRSideSensorObj09_LongVelVar 1;
BA_ "GenSigStartValue" SG_ 825 RRSideSensorObj09_LongVelVar 255;
BA_ "GenSigSendType" SG_ 825 RRSideSensorObj09_ExistConf 1;
BA_ "GenSigStartValue" SG_ 825 RRSideSensorObj09_ExistConf 127;
BA_ "GenSigSendType" SG_ 825 RRSideSensorObj09_LifeTime 1;
BA_ "GenSigStartValue" SG_ 825 RRSideSensorObj09_LifeTime 65535;
BA_ "GenSigSendType" SG_ 824 RRSideSensorObj08_LongExtBkVar 1;
BA_ "GenSigStartValue" SG_ 824 RRSideSensorObj08_LongExtBkVar 255;
BA_ "GenSigSendType" SG_ 824 RRSideSensorObj08_ExistConf 1;
BA_ "GenSigStartValue" SG_ 824 RRSideSensorObj08_ExistConf 127;
BA_ "GenSigSendType" SG_ 824 RRSideSensorObj08_CRC 1;
BA_ "GenSigStartValue" SG_ 824 RRSideSensorObj08_CRC 65535;
BA_ "E2EDataId" SG_ 824 RRSideSensorObj08_CRC 62;
BA_ "E2EDataLength" SG_ 824 RRSideSensorObj08_CRC 312;
BA_ "E2EProfile" SG_ 824 RRSideSensorObj08_CRC "P05";
BA_ "GenSigSendType" SG_ 824 RRSideSensorObj08_LifeTime 1;
BA_ "GenSigStartValue" SG_ 824 RRSideSensorObj08_LifeTime 65535;
BA_ "GenSigSendType" SG_ 824 RRSideSensorObj08_LatAcc 1;
BA_ "GenSigStartValue" SG_ 824 RRSideSensorObj08_LatAcc 511;
BA_ "GenSigSendType" SG_ 824 RRSideSensorObj08_LongAcc 1;
BA_ "GenSigStartValue" SG_ 824 RRSideSensorObj08_LongAcc 511;
BA_ "GenSigSendType" SG_ 824 RRSideSensorObj08_Counter 1;
BA_ "GenSigStartValue" SG_ 824 RRSideSensorObj08_Counter 255;
BA_ "GenSigSendType" SG_ 824 RRSideSensorObj08_LongExtBack 1;
BA_ "GenSigStartValue" SG_ 824 RRSideSensorObj08_LongExtBack 1023;
BA_ "GenSigSendType" SG_ 824 RRSideSensorObj08_LatExtLeft 1;
BA_ "GenSigStartValue" SG_ 824 RRSideSensorObj08_LatExtLeft 127;
BA_ "GenSigSendType" SG_ 824 RRSideSensorObj08_TimeStamp 1;
BA_ "GenSigStartValue" SG_ 824 RRSideSensorObj08_TimeStamp 65535;
BA_ "GenSigSendType" SG_ 824 RRSideSensorObj08_LatPosVar 1;
BA_ "GenSigStartValue" SG_ 824 RRSideSensorObj08_LatPosVar 255;
BA_ "GenSigSendType" SG_ 824 RRSideSensorObj08_LatExtLeftVar 1;
BA_ "GenSigStartValue" SG_ 824 RRSideSensorObj08_LatExtLeftVar 255;
BA_ "GenSigSendType" SG_ 824 RRSideSensorObj08_Height 1;
BA_ "GenSigStartValue" SG_ 824 RRSideSensorObj08_Height 255;
BA_ "GenSigSendType" SG_ 824 RRSideSensorObj08_LongExtFront 1;
BA_ "GenSigStartValue" SG_ 824 RRSideSensorObj08_LongExtFront 1023;
BA_ "GenSigSendType" SG_ 824 RRSideSensorObj08_Prioritisation 1;
BA_ "GenSigStartValue" SG_ 824 RRSideSensorObj08_Prioritisation 3;
BA_ "GenSigSendType" SG_ 824 RRSideSensorObj08_HeadingVar 1;
BA_ "GenSigStartValue" SG_ 824 RRSideSensorObj08_HeadingVar 255;
BA_ "GenSigSendType" SG_ 824 RRSideSensorObj08_LongAccVar 1;
BA_ "GenSigStartValue" SG_ 824 RRSideSensorObj08_LongAccVar 255;
BA_ "GenSigSendType" SG_ 824 RRSideSensorObj08_LatAccVar 1;
BA_ "GenSigStartValue" SG_ 824 RRSideSensorObj08_LatAccVar 255;
BA_ "GenSigSendType" SG_ 824 RRSideSensorObj08_ObstacleConf 1;
BA_ "GenSigStartValue" SG_ 824 RRSideSensorObj08_ObstacleConf 127;
BA_ "GenSigSendType" SG_ 824 RRSideSensorObj08_LatVelVar 1;
BA_ "GenSigStartValue" SG_ 824 RRSideSensorObj08_LatVelVar 255;
BA_ "GenSigSendType" SG_ 824 RRSideSensorObj08_TrackStatus 1;
BA_ "GenSigStartValue" SG_ 824 RRSideSensorObj08_TrackStatus 7;
BA_ "GenSigSendType" SG_ 824 RRSideSensorObj08_MOISPrio 1;
BA_ "GenSigSendType" SG_ 824 RRSideSensorObj08_LatExtRight 1;
BA_ "GenSigStartValue" SG_ 824 RRSideSensorObj08_LatExtRight 127;
BA_ "GenSigSendType" SG_ 824 RRSideSensorObj08_LongPosVar 1;
BA_ "GenSigStartValue" SG_ 824 RRSideSensorObj08_LongPosVar 255;
BA_ "GenSigSendType" SG_ 824 RRSideSensorObj08_LongExtFrVar 1;
BA_ "GenSigStartValue" SG_ 824 RRSideSensorObj08_LongExtFrVar 255;
BA_ "GenSigSendType" SG_ 824 RRSideSensorObj08_LatVel 1;
BA_ "GenSigStartValue" SG_ 824 RRSideSensorObj08_LatVel 8191;
BA_ "GenSigSendType" SG_ 824 RRSideSensorObj08_LatExtRtVar 1;
BA_ "GenSigStartValue" SG_ 824 RRSideSensorObj08_LatExtRtVar 255;
BA_ "GenSigSendType" SG_ 824 RRSideSensorObj08_ObjDynClass 1;
BA_ "GenSigStartValue" SG_ 824 RRSideSensorObj08_ObjDynClass 3;
BA_ "GenSigSendType" SG_ 824 RRSideSensorObj08_LongVelVar 1;
BA_ "GenSigStartValue" SG_ 824 RRSideSensorObj08_LongVelVar 255;
BA_ "GenSigSendType" SG_ 824 RRSideSensorObj08_Heading 1;
BA_ "GenSigStartValue" SG_ 824 RRSideSensorObj08_Heading 2047;
BA_ "GenSigSendType" SG_ 824 RRSideSensorObj08_CoastIndex 1;
BA_ "GenSigStartValue" SG_ 824 RRSideSensorObj08_CoastIndex 31;
BA_ "GenSigSendType" SG_ 824 RRSideSensorObj08_ObjClass 1;
BA_ "GenSigStartValue" SG_ 824 RRSideSensorObj08_ObjClass 15;
BA_ "GenSigSendType" SG_ 824 RRSideSensorObj08_LongVel 1;
BA_ "GenSigStartValue" SG_ 824 RRSideSensorObj08_LongVel 8191;
BA_ "GenSigSendType" SG_ 824 RRSideSensorObj08_LatPos 1;
BA_ "GenSigStartValue" SG_ 824 RRSideSensorObj08_LatPos 8191;
BA_ "GenSigSendType" SG_ 824 RRSideSensorObj08_ObjID 1;
BA_ "GenSigStartValue" SG_ 824 RRSideSensorObj08_ObjID 63;
BA_ "GenSigSendType" SG_ 824 RRSideSensorObj08_LongPos 1;
BA_ "GenSigStartValue" SG_ 824 RRSideSensorObj08_LongPos 8191;
BA_ "GenSigSendType" SG_ 824 RRSideSensorObj08_ObjClassConf 1;
BA_ "GenSigStartValue" SG_ 824 RRSideSensorObj08_ObjClassConf 15;
BA_ "GenSigSendType" SG_ 823 RRSideSensorObj07_LifeTime 1;
BA_ "GenSigStartValue" SG_ 823 RRSideSensorObj07_LifeTime 65535;
BA_ "GenSigSendType" SG_ 823 RRSideSensorObj07_HeadingVar 1;
BA_ "GenSigStartValue" SG_ 823 RRSideSensorObj07_HeadingVar 255;
BA_ "GenSigSendType" SG_ 823 RRSideSensorObj07_LongExtFrVar 1;
BA_ "GenSigStartValue" SG_ 823 RRSideSensorObj07_LongExtFrVar 255;
BA_ "GenSigSendType" SG_ 823 RRSideSensorObj07_ObjID 1;
BA_ "GenSigStartValue" SG_ 823 RRSideSensorObj07_ObjID 63;
BA_ "GenSigSendType" SG_ 823 RRSideSensorObj07_Heading 1;
BA_ "GenSigStartValue" SG_ 823 RRSideSensorObj07_Heading 2047;
BA_ "GenSigSendType" SG_ 823 RRSideSensorObj07_LongVelVar 1;
BA_ "GenSigStartValue" SG_ 823 RRSideSensorObj07_LongVelVar 255;
BA_ "GenSigSendType" SG_ 823 RRSideSensorObj07_TimeStamp 1;
BA_ "GenSigStartValue" SG_ 823 RRSideSensorObj07_TimeStamp 65535;
BA_ "GenSigSendType" SG_ 823 RRSideSensorObj07_LatPosVar 1;
BA_ "GenSigStartValue" SG_ 823 RRSideSensorObj07_LatPosVar 255;
BA_ "GenSigSendType" SG_ 823 RRSideSensorObj07_ExistConf 1;
BA_ "GenSigStartValue" SG_ 823 RRSideSensorObj07_ExistConf 127;
BA_ "GenSigSendType" SG_ 823 RRSideSensorObj07_Prioritisation 1;
BA_ "GenSigStartValue" SG_ 823 RRSideSensorObj07_Prioritisation 3;
BA_ "GenSigSendType" SG_ 823 RRSideSensorObj07_Counter 1;
BA_ "GenSigStartValue" SG_ 823 RRSideSensorObj07_Counter 255;
BA_ "GenSigSendType" SG_ 823 RRSideSensorObj07_LatPos 1;
BA_ "GenSigStartValue" SG_ 823 RRSideSensorObj07_LatPos 8191;
BA_ "GenSigSendType" SG_ 823 RRSideSensorObj07_LongVel 1;
BA_ "GenSigStartValue" SG_ 823 RRSideSensorObj07_LongVel 8191;
BA_ "GenSigSendType" SG_ 823 RRSideSensorObj07_LongExtBack 1;
BA_ "GenSigStartValue" SG_ 823 RRSideSensorObj07_LongExtBack 1023;
BA_ "GenSigSendType" SG_ 823 RRSideSensorObj07_LongExtFront 1;
BA_ "GenSigStartValue" SG_ 823 RRSideSensorObj07_LongExtFront 1023;
BA_ "GenSigSendType" SG_ 823 RRSideSensorObj07_TrackStatus 1;
BA_ "GenSigStartValue" SG_ 823 RRSideSensorObj07_TrackStatus 7;
BA_ "GenSigSendType" SG_ 823 RRSideSensorObj07_LongExtBkVar 1;
BA_ "GenSigStartValue" SG_ 823 RRSideSensorObj07_LongExtBkVar 255;
BA_ "GenSigSendType" SG_ 823 RRSideSensorObj07_LatAccVar 1;
BA_ "GenSigStartValue" SG_ 823 RRSideSensorObj07_LatAccVar 255;
BA_ "GenSigSendType" SG_ 823 RRSideSensorObj07_LongAcc 1;
BA_ "GenSigStartValue" SG_ 823 RRSideSensorObj07_LongAcc 511;
BA_ "GenSigSendType" SG_ 823 RRSideSensorObj07_LatAcc 1;
BA_ "GenSigStartValue" SG_ 823 RRSideSensorObj07_LatAcc 511;
BA_ "GenSigSendType" SG_ 823 RRSideSensorObj07_ObjDynClass 1;
BA_ "GenSigStartValue" SG_ 823 RRSideSensorObj07_ObjDynClass 3;
BA_ "GenSigSendType" SG_ 823 RRSideSensorObj07_ObjClassConf 1;
BA_ "GenSigStartValue" SG_ 823 RRSideSensorObj07_ObjClassConf 15;
BA_ "GenSigSendType" SG_ 823 RRSideSensorObj07_CRC 1;
BA_ "GenSigStartValue" SG_ 823 RRSideSensorObj07_CRC 65535;
BA_ "E2EDataId" SG_ 823 RRSideSensorObj07_CRC 61;
BA_ "E2EDataLength" SG_ 823 RRSideSensorObj07_CRC 312;
BA_ "E2EProfile" SG_ 823 RRSideSensorObj07_CRC "P05";
BA_ "GenSigSendType" SG_ 823 RRSideSensorObj07_LongPosVar 1;
BA_ "GenSigStartValue" SG_ 823 RRSideSensorObj07_LongPosVar 255;
BA_ "GenSigSendType" SG_ 823 RRSideSensorObj07_LatExtLeftVar 1;
BA_ "GenSigStartValue" SG_ 823 RRSideSensorObj07_LatExtLeftVar 255;
BA_ "GenSigSendType" SG_ 823 RRSideSensorObj07_MOISPrio 1;
BA_ "GenSigSendType" SG_ 823 RRSideSensorObj07_ObjClass 1;
BA_ "GenSigStartValue" SG_ 823 RRSideSensorObj07_ObjClass 15;
BA_ "GenSigSendType" SG_ 823 RRSideSensorObj07_ObstacleConf 1;
BA_ "GenSigStartValue" SG_ 823 RRSideSensorObj07_ObstacleConf 127;
BA_ "GenSigSendType" SG_ 823 RRSideSensorObj07_LatExtRtVar 1;
BA_ "GenSigStartValue" SG_ 823 RRSideSensorObj07_LatExtRtVar 255;
BA_ "GenSigSendType" SG_ 823 RRSideSensorObj07_LatExtRight 1;
BA_ "GenSigStartValue" SG_ 823 RRSideSensorObj07_LatExtRight 127;
BA_ "GenSigSendType" SG_ 823 RRSideSensorObj07_LatExtLeft 1;
BA_ "GenSigStartValue" SG_ 823 RRSideSensorObj07_LatExtLeft 127;
BA_ "GenSigSendType" SG_ 823 RRSideSensorObj07_Height 1;
BA_ "GenSigStartValue" SG_ 823 RRSideSensorObj07_Height 255;
BA_ "GenSigSendType" SG_ 823 RRSideSensorObj07_LatVel 1;
BA_ "GenSigStartValue" SG_ 823 RRSideSensorObj07_LatVel 8191;
BA_ "GenSigSendType" SG_ 823 RRSideSensorObj07_LongAccVar 1;
BA_ "GenSigStartValue" SG_ 823 RRSideSensorObj07_LongAccVar 255;
BA_ "GenSigSendType" SG_ 823 RRSideSensorObj07_LongPos 1;
BA_ "GenSigStartValue" SG_ 823 RRSideSensorObj07_LongPos 8191;
BA_ "GenSigSendType" SG_ 823 RRSideSensorObj07_CoastIndex 1;
BA_ "GenSigStartValue" SG_ 823 RRSideSensorObj07_CoastIndex 31;
BA_ "GenSigSendType" SG_ 823 RRSideSensorObj07_LatVelVar 1;
BA_ "GenSigStartValue" SG_ 823 RRSideSensorObj07_LatVelVar 255;
BA_ "GenSigSendType" SG_ 822 RRSideSensorObj06_LongExtFront 1;
BA_ "GenSigStartValue" SG_ 822 RRSideSensorObj06_LongExtFront 1023;
BA_ "GenSigSendType" SG_ 822 RRSideSensorObj06_ObjDynClass 1;
BA_ "GenSigStartValue" SG_ 822 RRSideSensorObj06_ObjDynClass 3;
BA_ "GenSigSendType" SG_ 822 RRSideSensorObj06_MOISPrio 1;
BA_ "GenSigSendType" SG_ 822 RRSideSensorObj06_LatExtLeft 1;
BA_ "GenSigStartValue" SG_ 822 RRSideSensorObj06_LatExtLeft 127;
BA_ "GenSigSendType" SG_ 822 RRSideSensorObj06_ObjClassConf 1;
BA_ "GenSigStartValue" SG_ 822 RRSideSensorObj06_ObjClassConf 15;
BA_ "GenSigSendType" SG_ 822 RRSideSensorObj06_LongPosVar 1;
BA_ "GenSigStartValue" SG_ 822 RRSideSensorObj06_LongPosVar 255;
BA_ "GenSigSendType" SG_ 822 RRSideSensorObj06_LatExtRight 1;
BA_ "GenSigStartValue" SG_ 822 RRSideSensorObj06_LatExtRight 127;
BA_ "GenSigSendType" SG_ 822 RRSideSensorObj06_LongVel 1;
BA_ "GenSigStartValue" SG_ 822 RRSideSensorObj06_LongVel 8191;
BA_ "GenSigSendType" SG_ 822 RRSideSensorObj06_LifeTime 1;
BA_ "GenSigStartValue" SG_ 822 RRSideSensorObj06_LifeTime 65535;
BA_ "GenSigSendType" SG_ 822 RRSideSensorObj06_LongExtBack 1;
BA_ "GenSigStartValue" SG_ 822 RRSideSensorObj06_LongExtBack 1023;
BA_ "GenSigSendType" SG_ 822 RRSideSensorObj06_HeadingVar 1;
BA_ "GenSigStartValue" SG_ 822 RRSideSensorObj06_HeadingVar 255;
BA_ "GenSigSendType" SG_ 822 RRSideSensorObj06_LatVel 1;
BA_ "GenSigStartValue" SG_ 822 RRSideSensorObj06_LatVel 8191;
BA_ "GenSigSendType" SG_ 822 RRSideSensorObj06_LatExtRtVar 1;
BA_ "GenSigStartValue" SG_ 822 RRSideSensorObj06_LatExtRtVar 255;
BA_ "GenSigSendType" SG_ 822 RRSideSensorObj06_LongExtFrVar 1;
BA_ "GenSigStartValue" SG_ 822 RRSideSensorObj06_LongExtFrVar 255;
BA_ "GenSigSendType" SG_ 822 RRSideSensorObj06_LongAccVar 1;
BA_ "GenSigStartValue" SG_ 822 RRSideSensorObj06_LongAccVar 255;
BA_ "GenSigSendType" SG_ 822 RRSideSensorObj06_LatExtLeftVar 1;
BA_ "GenSigStartValue" SG_ 822 RRSideSensorObj06_LatExtLeftVar 255;
BA_ "GenSigSendType" SG_ 822 RRSideSensorObj06_LongVelVar 1;
BA_ "GenSigStartValue" SG_ 822 RRSideSensorObj06_LongVelVar 255;
BA_ "GenSigSendType" SG_ 822 RRSideSensorObj06_Prioritisation 1;
BA_ "GenSigStartValue" SG_ 822 RRSideSensorObj06_Prioritisation 3;
BA_ "GenSigSendType" SG_ 822 RRSideSensorObj06_LongPos 1;
BA_ "GenSigStartValue" SG_ 822 RRSideSensorObj06_LongPos 8191;
BA_ "GenSigSendType" SG_ 822 RRSideSensorObj06_Counter 1;
BA_ "GenSigStartValue" SG_ 822 RRSideSensorObj06_Counter 255;
BA_ "GenSigSendType" SG_ 822 RRSideSensorObj06_LatVelVar 1;
BA_ "GenSigStartValue" SG_ 822 RRSideSensorObj06_LatVelVar 255;
BA_ "GenSigSendType" SG_ 822 RRSideSensorObj06_LatAccVar 1;
BA_ "GenSigStartValue" SG_ 822 RRSideSensorObj06_LatAccVar 255;
BA_ "GenSigSendType" SG_ 822 RRSideSensorObj06_Heading 1;
BA_ "GenSigStartValue" SG_ 822 RRSideSensorObj06_Heading 2047;
BA_ "GenSigSendType" SG_ 822 RRSideSensorObj06_ObjClass 1;
BA_ "GenSigStartValue" SG_ 822 RRSideSensorObj06_ObjClass 15;
BA_ "GenSigSendType" SG_ 822 RRSideSensorObj06_ObstacleConf 1;
BA_ "GenSigStartValue" SG_ 822 RRSideSensorObj06_ObstacleConf 127;
BA_ "GenSigSendType" SG_ 822 RRSideSensorObj06_LatPosVar 1;
BA_ "GenSigStartValue" SG_ 822 RRSideSensorObj06_LatPosVar 255;
BA_ "GenSigSendType" SG_ 822 RRSideSensorObj06_LongAcc 1;
BA_ "GenSigStartValue" SG_ 822 RRSideSensorObj06_LongAcc 511;
BA_ "GenSigSendType" SG_ 822 RRSideSensorObj06_LongExtBkVar 1;
BA_ "GenSigStartValue" SG_ 822 RRSideSensorObj06_LongExtBkVar 255;
BA_ "GenSigSendType" SG_ 822 RRSideSensorObj06_Height 1;
BA_ "GenSigStartValue" SG_ 822 RRSideSensorObj06_Height 255;
BA_ "GenSigSendType" SG_ 822 RRSideSensorObj06_LatPos 1;
BA_ "GenSigStartValue" SG_ 822 RRSideSensorObj06_LatPos 8191;
BA_ "GenSigSendType" SG_ 822 RRSideSensorObj06_CoastIndex 1;
BA_ "GenSigStartValue" SG_ 822 RRSideSensorObj06_CoastIndex 31;
BA_ "GenSigSendType" SG_ 822 RRSideSensorObj06_TrackStatus 1;
BA_ "GenSigStartValue" SG_ 822 RRSideSensorObj06_TrackStatus 7;
BA_ "GenSigSendType" SG_ 822 RRSideSensorObj06_LatAcc 1;
BA_ "GenSigStartValue" SG_ 822 RRSideSensorObj06_LatAcc 511;
BA_ "GenSigSendType" SG_ 822 RRSideSensorObj06_ExistConf 1;
BA_ "GenSigStartValue" SG_ 822 RRSideSensorObj06_ExistConf 127;
BA_ "GenSigSendType" SG_ 822 RRSideSensorObj06_CRC 1;
BA_ "GenSigStartValue" SG_ 822 RRSideSensorObj06_CRC 65535;
BA_ "E2EDataId" SG_ 822 RRSideSensorObj06_CRC 60;
BA_ "E2EDataLength" SG_ 822 RRSideSensorObj06_CRC 312;
BA_ "E2EProfile" SG_ 822 RRSideSensorObj06_CRC "P05";
BA_ "GenSigSendType" SG_ 822 RRSideSensorObj06_ObjID 1;
BA_ "GenSigStartValue" SG_ 822 RRSideSensorObj06_ObjID 63;
BA_ "GenSigSendType" SG_ 822 RRSideSensorObj06_TimeStamp 1;
BA_ "GenSigStartValue" SG_ 822 RRSideSensorObj06_TimeStamp 65535;
BA_ "GenSigSendType" SG_ 821 RRSideSensorObj05_LatPos 1;
BA_ "GenSigStartValue" SG_ 821 RRSideSensorObj05_LatPos 8191;
BA_ "GenSigSendType" SG_ 821 RRSideSensorObj05_ObjClass 1;
BA_ "GenSigStartValue" SG_ 821 RRSideSensorObj05_ObjClass 15;
BA_ "GenSigSendType" SG_ 821 RRSideSensorObj05_LongVel 1;
BA_ "GenSigStartValue" SG_ 821 RRSideSensorObj05_LongVel 8191;
BA_ "GenSigSendType" SG_ 821 RRSideSensorObj05_ObjID 1;
BA_ "GenSigStartValue" SG_ 821 RRSideSensorObj05_ObjID 63;
BA_ "GenSigSendType" SG_ 821 RRSideSensorObj05_LatPosVar 1;
BA_ "GenSigStartValue" SG_ 821 RRSideSensorObj05_LatPosVar 255;
BA_ "GenSigSendType" SG_ 821 RRSideSensorObj05_Prioritisation 1;
BA_ "GenSigStartValue" SG_ 821 RRSideSensorObj05_Prioritisation 3;
BA_ "GenSigSendType" SG_ 821 RRSideSensorObj05_LifeTime 1;
BA_ "GenSigStartValue" SG_ 821 RRSideSensorObj05_LifeTime 65535;
BA_ "GenSigSendType" SG_ 821 RRSideSensorObj05_LongAccVar 1;
BA_ "GenSigStartValue" SG_ 821 RRSideSensorObj05_LongAccVar 255;
BA_ "GenSigSendType" SG_ 821 RRSideSensorObj05_CRC 1;
BA_ "GenSigStartValue" SG_ 821 RRSideSensorObj05_CRC 65535;
BA_ "E2EDataId" SG_ 821 RRSideSensorObj05_CRC 59;
BA_ "E2EDataLength" SG_ 821 RRSideSensorObj05_CRC 312;
BA_ "E2EProfile" SG_ 821 RRSideSensorObj05_CRC "P05";
BA_ "GenSigSendType" SG_ 821 RRSideSensorObj05_TrackStatus 1;
BA_ "GenSigStartValue" SG_ 821 RRSideSensorObj05_TrackStatus 7;
BA_ "GenSigSendType" SG_ 821 RRSideSensorObj05_ObstacleConf 1;
BA_ "GenSigStartValue" SG_ 821 RRSideSensorObj05_ObstacleConf 127;
BA_ "GenSigSendType" SG_ 821 RRSideSensorObj05_ObjDynClass 1;
BA_ "GenSigStartValue" SG_ 821 RRSideSensorObj05_ObjDynClass 3;
BA_ "GenSigSendType" SG_ 821 RRSideSensorObj05_LatExtRight 1;
BA_ "GenSigStartValue" SG_ 821 RRSideSensorObj05_LatExtRight 127;
BA_ "GenSigSendType" SG_ 821 RRSideSensorObj05_LongPosVar 1;
BA_ "GenSigStartValue" SG_ 821 RRSideSensorObj05_LongPosVar 255;
BA_ "GenSigSendType" SG_ 821 RRSideSensorObj05_Heading 1;
BA_ "GenSigStartValue" SG_ 821 RRSideSensorObj05_Heading 2047;
BA_ "GenSigSendType" SG_ 821 RRSideSensorObj05_LongExtFront 1;
BA_ "GenSigStartValue" SG_ 821 RRSideSensorObj05_LongExtFront 1023;
BA_ "GenSigSendType" SG_ 821 RRSideSensorObj05_LatAcc 1;
BA_ "GenSigStartValue" SG_ 821 RRSideSensorObj05_LatAcc 511;
BA_ "GenSigSendType" SG_ 821 RRSideSensorObj05_MOISPrio 1;
BA_ "GenSigSendType" SG_ 821 RRSideSensorObj05_LatVelVar 1;
BA_ "GenSigStartValue" SG_ 821 RRSideSensorObj05_LatVelVar 255;
BA_ "GenSigSendType" SG_ 821 RRSideSensorObj05_LatAccVar 1;
BA_ "GenSigStartValue" SG_ 821 RRSideSensorObj05_LatAccVar 255;
BA_ "GenSigSendType" SG_ 821 RRSideSensorObj05_LongAcc 1;
BA_ "GenSigStartValue" SG_ 821 RRSideSensorObj05_LongAcc 511;
BA_ "GenSigSendType" SG_ 821 RRSideSensorObj05_LongExtBack 1;
BA_ "GenSigStartValue" SG_ 821 RRSideSensorObj05_LongExtBack 1023;
BA_ "GenSigSendType" SG_ 821 RRSideSensorObj05_ObjClassConf 1;
BA_ "GenSigStartValue" SG_ 821 RRSideSensorObj05_ObjClassConf 15;
BA_ "GenSigSendType" SG_ 821 RRSideSensorObj05_ExistConf 1;
BA_ "GenSigStartValue" SG_ 821 RRSideSensorObj05_ExistConf 127;
BA_ "GenSigSendType" SG_ 821 RRSideSensorObj05_Height 1;
BA_ "GenSigStartValue" SG_ 821 RRSideSensorObj05_Height 255;
BA_ "GenSigSendType" SG_ 821 RRSideSensorObj05_LongExtFrVar 1;
BA_ "GenSigStartValue" SG_ 821 RRSideSensorObj05_LongExtFrVar 255;
BA_ "GenSigSendType" SG_ 821 RRSideSensorObj05_Counter 1;
BA_ "GenSigStartValue" SG_ 821 RRSideSensorObj05_Counter 255;
BA_ "GenSigSendType" SG_ 821 RRSideSensorObj05_TimeStamp 1;
BA_ "GenSigStartValue" SG_ 821 RRSideSensorObj05_TimeStamp 65535;
BA_ "GenSigSendType" SG_ 821 RRSideSensorObj05_LongPos 1;
BA_ "GenSigStartValue" SG_ 821 RRSideSensorObj05_LongPos 8191;
BA_ "GenSigSendType" SG_ 821 RRSideSensorObj05_LongVelVar 1;
BA_ "GenSigStartValue" SG_ 821 RRSideSensorObj05_LongVelVar 255;
BA_ "GenSigSendType" SG_ 821 RRSideSensorObj05_HeadingVar 1;
BA_ "GenSigStartValue" SG_ 821 RRSideSensorObj05_HeadingVar 255;
BA_ "GenSigSendType" SG_ 821 RRSideSensorObj05_LatExtRtVar 1;
BA_ "GenSigStartValue" SG_ 821 RRSideSensorObj05_LatExtRtVar 255;
BA_ "GenSigSendType" SG_ 821 RRSideSensorObj05_LatVel 1;
BA_ "GenSigStartValue" SG_ 821 RRSideSensorObj05_LatVel 8191;
BA_ "GenSigSendType" SG_ 821 RRSideSensorObj05_LatExtLeft 1;
BA_ "GenSigStartValue" SG_ 821 RRSideSensorObj05_LatExtLeft 127;
BA_ "GenSigSendType" SG_ 821 RRSideSensorObj05_LongExtBkVar 1;
BA_ "GenSigStartValue" SG_ 821 RRSideSensorObj05_LongExtBkVar 255;
BA_ "GenSigSendType" SG_ 821 RRSideSensorObj05_CoastIndex 1;
BA_ "GenSigStartValue" SG_ 821 RRSideSensorObj05_CoastIndex 31;
BA_ "GenSigSendType" SG_ 821 RRSideSensorObj05_LatExtLeftVar 1;
BA_ "GenSigStartValue" SG_ 821 RRSideSensorObj05_LatExtLeftVar 255;
BA_ "GenSigSendType" SG_ 820 RRSideSensorObj04_HeadingVar 1;
BA_ "GenSigStartValue" SG_ 820 RRSideSensorObj04_HeadingVar 255;
BA_ "GenSigSendType" SG_ 820 RRSideSensorObj04_TrackStatus 1;
BA_ "GenSigStartValue" SG_ 820 RRSideSensorObj04_TrackStatus 7;
BA_ "GenSigSendType" SG_ 820 RRSideSensorObj04_LongExtFront 1;
BA_ "GenSigStartValue" SG_ 820 RRSideSensorObj04_LongExtFront 1023;
BA_ "GenSigSendType" SG_ 820 RRSideSensorObj04_LatAcc 1;
BA_ "GenSigStartValue" SG_ 820 RRSideSensorObj04_LatAcc 511;
BA_ "GenSigSendType" SG_ 820 RRSideSensorObj04_LongPosVar 1;
BA_ "GenSigStartValue" SG_ 820 RRSideSensorObj04_LongPosVar 255;
BA_ "GenSigSendType" SG_ 820 RRSideSensorObj04_LatVelVar 1;
BA_ "GenSigStartValue" SG_ 820 RRSideSensorObj04_LatVelVar 255;
BA_ "GenSigSendType" SG_ 820 RRSideSensorObj04_CoastIndex 1;
BA_ "GenSigStartValue" SG_ 820 RRSideSensorObj04_CoastIndex 31;
BA_ "GenSigSendType" SG_ 820 RRSideSensorObj04_LatPosVar 1;
BA_ "GenSigStartValue" SG_ 820 RRSideSensorObj04_LatPosVar 255;
BA_ "GenSigSendType" SG_ 820 RRSideSensorObj04_ExistConf 1;
BA_ "GenSigStartValue" SG_ 820 RRSideSensorObj04_ExistConf 127;
BA_ "GenSigSendType" SG_ 820 RRSideSensorObj04_LatExtRight 1;
BA_ "GenSigStartValue" SG_ 820 RRSideSensorObj04_LatExtRight 127;
BA_ "GenSigSendType" SG_ 820 RRSideSensorObj04_LatAccVar 1;
BA_ "GenSigStartValue" SG_ 820 RRSideSensorObj04_LatAccVar 255;
BA_ "GenSigSendType" SG_ 820 RRSideSensorObj04_ObjID 1;
BA_ "GenSigStartValue" SG_ 820 RRSideSensorObj04_ObjID 63;
BA_ "GenSigSendType" SG_ 820 RRSideSensorObj04_LongAccVar 1;
BA_ "GenSigStartValue" SG_ 820 RRSideSensorObj04_LongAccVar 255;
BA_ "GenSigSendType" SG_ 820 RRSideSensorObj04_ObstacleConf 1;
BA_ "GenSigStartValue" SG_ 820 RRSideSensorObj04_ObstacleConf 127;
BA_ "GenSigSendType" SG_ 820 RRSideSensorObj04_MOISPrio 1;
BA_ "GenSigSendType" SG_ 820 RRSideSensorObj04_LongPos 1;
BA_ "GenSigStartValue" SG_ 820 RRSideSensorObj04_LongPos 8191;
BA_ "GenSigSendType" SG_ 820 RRSideSensorObj04_LatVel 1;
BA_ "GenSigStartValue" SG_ 820 RRSideSensorObj04_LatVel 8191;
BA_ "GenSigSendType" SG_ 820 RRSideSensorObj04_LongExtBack 1;
BA_ "GenSigStartValue" SG_ 820 RRSideSensorObj04_LongExtBack 1023;
BA_ "GenSigSendType" SG_ 820 RRSideSensorObj04_TimeStamp 1;
BA_ "GenSigStartValue" SG_ 820 RRSideSensorObj04_TimeStamp 65535;
BA_ "GenSigSendType" SG_ 820 RRSideSensorObj04_LatExtRtVar 1;
BA_ "GenSigStartValue" SG_ 820 RRSideSensorObj04_LatExtRtVar 255;
BA_ "GenSigSendType" SG_ 820 RRSideSensorObj04_CRC 1;
BA_ "GenSigStartValue" SG_ 820 RRSideSensorObj04_CRC 65535;
BA_ "E2EDataId" SG_ 820 RRSideSensorObj04_CRC 58;
BA_ "E2EDataLength" SG_ 820 RRSideSensorObj04_CRC 312;
BA_ "E2EProfile" SG_ 820 RRSideSensorObj04_CRC "P05";
BA_ "GenSigSendType" SG_ 820 RRSideSensorObj04_LatExtLeft 1;
BA_ "GenSigStartValue" SG_ 820 RRSideSensorObj04_LatExtLeft 127;
BA_ "GenSigSendType" SG_ 820 RRSideSensorObj04_LongVel 1;
BA_ "GenSigStartValue" SG_ 820 RRSideSensorObj04_LongVel 8191;
BA_ "GenSigSendType" SG_ 820 RRSideSensorObj04_LongExtFrVar 1;
BA_ "GenSigStartValue" SG_ 820 RRSideSensorObj04_LongExtFrVar 255;
BA_ "GenSigSendType" SG_ 820 RRSideSensorObj04_Counter 1;
BA_ "GenSigStartValue" SG_ 820 RRSideSensorObj04_Counter 255;
BA_ "GenSigSendType" SG_ 820 RRSideSensorObj04_LatPos 1;
BA_ "GenSigStartValue" SG_ 820 RRSideSensorObj04_LatPos 8191;
BA_ "GenSigSendType" SG_ 820 RRSideSensorObj04_LatExtLeftVar 1;
BA_ "GenSigStartValue" SG_ 820 RRSideSensorObj04_LatExtLeftVar 255;
BA_ "GenSigSendType" SG_ 820 RRSideSensorObj04_LifeTime 1;
BA_ "GenSigStartValue" SG_ 820 RRSideSensorObj04_LifeTime 65535;
BA_ "GenSigSendType" SG_ 820 RRSideSensorObj04_Height 1;
BA_ "GenSigStartValue" SG_ 820 RRSideSensorObj04_Height 255;
BA_ "GenSigSendType" SG_ 820 RRSideSensorObj04_LongAcc 1;
BA_ "GenSigStartValue" SG_ 820 RRSideSensorObj04_LongAcc 511;
BA_ "GenSigSendType" SG_ 820 RRSideSensorObj04_ObjDynClass 1;
BA_ "GenSigStartValue" SG_ 820 RRSideSensorObj04_ObjDynClass 3;
BA_ "GenSigSendType" SG_ 820 RRSideSensorObj04_LongVelVar 1;
BA_ "GenSigStartValue" SG_ 820 RRSideSensorObj04_LongVelVar 255;
BA_ "GenSigSendType" SG_ 820 RRSideSensorObj04_ObjClass 1;
BA_ "GenSigStartValue" SG_ 820 RRSideSensorObj04_ObjClass 15;
BA_ "GenSigSendType" SG_ 820 RRSideSensorObj04_ObjClassConf 1;
BA_ "GenSigStartValue" SG_ 820 RRSideSensorObj04_ObjClassConf 15;
BA_ "GenSigSendType" SG_ 820 RRSideSensorObj04_Prioritisation 1;
BA_ "GenSigStartValue" SG_ 820 RRSideSensorObj04_Prioritisation 3;
BA_ "GenSigSendType" SG_ 820 RRSideSensorObj04_Heading 1;
BA_ "GenSigStartValue" SG_ 820 RRSideSensorObj04_Heading 2047;
BA_ "GenSigSendType" SG_ 820 RRSideSensorObj04_LongExtBkVar 1;
BA_ "GenSigStartValue" SG_ 820 RRSideSensorObj04_LongExtBkVar 255;
BA_ "GenSigSendType" SG_ 819 RRSideSensorObj03_LongExtBack 1;
BA_ "GenSigStartValue" SG_ 819 RRSideSensorObj03_LongExtBack 1023;
BA_ "GenSigSendType" SG_ 819 RRSideSensorObj03_ObjDynClass 1;
BA_ "GenSigStartValue" SG_ 819 RRSideSensorObj03_ObjDynClass 3;
BA_ "GenSigSendType" SG_ 819 RRSideSensorObj03_ObjClass 1;
BA_ "GenSigStartValue" SG_ 819 RRSideSensorObj03_ObjClass 15;
BA_ "GenSigSendType" SG_ 819 RRSideSensorObj03_LatAcc 1;
BA_ "GenSigStartValue" SG_ 819 RRSideSensorObj03_LatAcc 511;
BA_ "GenSigSendType" SG_ 819 RRSideSensorObj03_Heading 1;
BA_ "GenSigStartValue" SG_ 819 RRSideSensorObj03_Heading 2047;
BA_ "GenSigSendType" SG_ 819 RRSideSensorObj03_ObjClassConf 1;
BA_ "GenSigStartValue" SG_ 819 RRSideSensorObj03_ObjClassConf 15;
BA_ "GenSigSendType" SG_ 819 RRSideSensorObj03_LongPos 1;
BA_ "GenSigStartValue" SG_ 819 RRSideSensorObj03_LongPos 8191;
BA_ "GenSigSendType" SG_ 819 RRSideSensorObj03_ObjID 1;
BA_ "GenSigStartValue" SG_ 819 RRSideSensorObj03_ObjID 63;
BA_ "GenSigSendType" SG_ 819 RRSideSensorObj03_TimeStamp 1;
BA_ "GenSigStartValue" SG_ 819 RRSideSensorObj03_TimeStamp 65535;
BA_ "GenSigSendType" SG_ 819 RRSideSensorObj03_LongPosVar 1;
BA_ "GenSigStartValue" SG_ 819 RRSideSensorObj03_LongPosVar 255;
BA_ "GenSigSendType" SG_ 819 RRSideSensorObj03_LatExtLeft 1;
BA_ "GenSigStartValue" SG_ 819 RRSideSensorObj03_LatExtLeft 127;
BA_ "GenSigSendType" SG_ 819 RRSideSensorObj03_LongExtFrVar 1;
BA_ "GenSigStartValue" SG_ 819 RRSideSensorObj03_LongExtFrVar 255;
BA_ "GenSigSendType" SG_ 819 RRSideSensorObj03_LongVel 1;
BA_ "GenSigStartValue" SG_ 819 RRSideSensorObj03_LongVel 8191;
BA_ "GenSigSendType" SG_ 819 RRSideSensorObj03_LatVel 1;
BA_ "GenSigStartValue" SG_ 819 RRSideSensorObj03_LatVel 8191;
BA_ "GenSigSendType" SG_ 819 RRSideSensorObj03_Prioritisation 1;
BA_ "GenSigStartValue" SG_ 819 RRSideSensorObj03_Prioritisation 3;
BA_ "GenSigSendType" SG_ 819 RRSideSensorObj03_Height 1;
BA_ "GenSigStartValue" SG_ 819 RRSideSensorObj03_Height 255;
BA_ "GenSigSendType" SG_ 819 RRSideSensorObj03_CRC 1;
BA_ "GenSigStartValue" SG_ 819 RRSideSensorObj03_CRC 65535;
BA_ "E2EDataId" SG_ 819 RRSideSensorObj03_CRC 57;
BA_ "E2EDataLength" SG_ 819 RRSideSensorObj03_CRC 312;
BA_ "E2EProfile" SG_ 819 RRSideSensorObj03_CRC "P05";
BA_ "GenSigSendType" SG_ 819 RRSideSensorObj03_LatExtRtVar 1;
BA_ "GenSigStartValue" SG_ 819 RRSideSensorObj03_LatExtRtVar 255;
BA_ "GenSigSendType" SG_ 819 RRSideSensorObj03_ExistConf 1;
BA_ "GenSigStartValue" SG_ 819 RRSideSensorObj03_ExistConf 127;
BA_ "GenSigSendType" SG_ 819 RRSideSensorObj03_Counter 1;
BA_ "GenSigStartValue" SG_ 819 RRSideSensorObj03_Counter 255;
BA_ "GenSigSendType" SG_ 819 RRSideSensorObj03_LongExtBkVar 1;
BA_ "GenSigStartValue" SG_ 819 RRSideSensorObj03_LongExtBkVar 255;
BA_ "GenSigSendType" SG_ 819 RRSideSensorObj03_LatVelVar 1;
BA_ "GenSigStartValue" SG_ 819 RRSideSensorObj03_LatVelVar 255;
BA_ "GenSigSendType" SG_ 819 RRSideSensorObj03_LatExtRight 1;
BA_ "GenSigStartValue" SG_ 819 RRSideSensorObj03_LatExtRight 127;
BA_ "GenSigSendType" SG_ 819 RRSideSensorObj03_LifeTime 1;
BA_ "GenSigStartValue" SG_ 819 RRSideSensorObj03_LifeTime 65535;
BA_ "GenSigSendType" SG_ 819 RRSideSensorObj03_LatExtLeftVar 1;
BA_ "GenSigStartValue" SG_ 819 RRSideSensorObj03_LatExtLeftVar 255;
BA_ "GenSigSendType" SG_ 819 RRSideSensorObj03_HeadingVar 1;
BA_ "GenSigStartValue" SG_ 819 RRSideSensorObj03_HeadingVar 255;
BA_ "GenSigSendType" SG_ 819 RRSideSensorObj03_LatPos 1;
BA_ "GenSigStartValue" SG_ 819 RRSideSensorObj03_LatPos 8191;
BA_ "GenSigSendType" SG_ 819 RRSideSensorObj03_ObstacleConf 1;
BA_ "GenSigStartValue" SG_ 819 RRSideSensorObj03_ObstacleConf 127;
BA_ "GenSigSendType" SG_ 819 RRSideSensorObj03_LatPosVar 1;
BA_ "GenSigStartValue" SG_ 819 RRSideSensorObj03_LatPosVar 255;
BA_ "GenSigSendType" SG_ 819 RRSideSensorObj03_LongExtFront 1;
BA_ "GenSigStartValue" SG_ 819 RRSideSensorObj03_LongExtFront 1023;
BA_ "GenSigSendType" SG_ 819 RRSideSensorObj03_LongAcc 1;
BA_ "GenSigStartValue" SG_ 819 RRSideSensorObj03_LongAcc 511;
BA_ "GenSigSendType" SG_ 819 RRSideSensorObj03_CoastIndex 1;
BA_ "GenSigStartValue" SG_ 819 RRSideSensorObj03_CoastIndex 31;
BA_ "GenSigSendType" SG_ 819 RRSideSensorObj03_TrackStatus 1;
BA_ "GenSigStartValue" SG_ 819 RRSideSensorObj03_TrackStatus 7;
BA_ "GenSigSendType" SG_ 819 RRSideSensorObj03_MOISPrio 1;
BA_ "GenSigSendType" SG_ 819 RRSideSensorObj03_LongAccVar 1;
BA_ "GenSigStartValue" SG_ 819 RRSideSensorObj03_LongAccVar 255;
BA_ "GenSigSendType" SG_ 819 RRSideSensorObj03_LongVelVar 1;
BA_ "GenSigStartValue" SG_ 819 RRSideSensorObj03_LongVelVar 255;
BA_ "GenSigSendType" SG_ 819 RRSideSensorObj03_LatAccVar 1;
BA_ "GenSigStartValue" SG_ 819 RRSideSensorObj03_LatAccVar 255;
BA_ "GenSigSendType" SG_ 818 RRSideSensorObj02_Prioritisation 1;
BA_ "GenSigStartValue" SG_ 818 RRSideSensorObj02_Prioritisation 3;
BA_ "GenSigSendType" SG_ 818 RRSideSensorObj02_LongAcc 1;
BA_ "GenSigStartValue" SG_ 818 RRSideSensorObj02_LongAcc 511;
BA_ "GenSigSendType" SG_ 818 RRSideSensorObj02_LatAcc 1;
BA_ "GenSigStartValue" SG_ 818 RRSideSensorObj02_LatAcc 511;
BA_ "GenSigSendType" SG_ 818 RRSideSensorObj02_LatExtRight 1;
BA_ "GenSigStartValue" SG_ 818 RRSideSensorObj02_LatExtRight 127;
BA_ "GenSigSendType" SG_ 818 RRSideSensorObj02_LongAccVar 1;
BA_ "GenSigStartValue" SG_ 818 RRSideSensorObj02_LongAccVar 255;
BA_ "GenSigSendType" SG_ 818 RRSideSensorObj02_LongPos 1;
BA_ "GenSigStartValue" SG_ 818 RRSideSensorObj02_LongPos 8191;
BA_ "GenSigSendType" SG_ 818 RRSideSensorObj02_ObstacleConf 1;
BA_ "GenSigStartValue" SG_ 818 RRSideSensorObj02_ObstacleConf 127;
BA_ "GenSigSendType" SG_ 818 RRSideSensorObj02_LongExtFrVar 1;
BA_ "GenSigStartValue" SG_ 818 RRSideSensorObj02_LongExtFrVar 255;
BA_ "GenSigSendType" SG_ 818 RRSideSensorObj02_LatVelVar 1;
BA_ "GenSigStartValue" SG_ 818 RRSideSensorObj02_LatVelVar 255;
BA_ "GenSigSendType" SG_ 818 RRSideSensorObj02_MOISPrio 1;
BA_ "GenSigSendType" SG_ 818 RRSideSensorObj02_LatPos 1;
BA_ "GenSigStartValue" SG_ 818 RRSideSensorObj02_LatPos 8191;
BA_ "GenSigSendType" SG_ 818 RRSideSensorObj02_LatVel 1;
BA_ "GenSigStartValue" SG_ 818 RRSideSensorObj02_LatVel 8191;
BA_ "GenSigSendType" SG_ 818 RRSideSensorObj02_LongVelVar 1;
BA_ "GenSigStartValue" SG_ 818 RRSideSensorObj02_LongVelVar 255;
BA_ "GenSigSendType" SG_ 818 RRSideSensorObj02_LongExtBack 1;
BA_ "GenSigStartValue" SG_ 818 RRSideSensorObj02_LongExtBack 1023;
BA_ "GenSigSendType" SG_ 818 RRSideSensorObj02_Height 1;
BA_ "GenSigStartValue" SG_ 818 RRSideSensorObj02_Height 255;
BA_ "GenSigSendType" SG_ 818 RRSideSensorObj02_ExistConf 1;
BA_ "GenSigStartValue" SG_ 818 RRSideSensorObj02_ExistConf 127;
BA_ "GenSigSendType" SG_ 818 RRSideSensorObj02_ObjDynClass 1;
BA_ "GenSigStartValue" SG_ 818 RRSideSensorObj02_ObjDynClass 3;
BA_ "GenSigSendType" SG_ 818 RRSideSensorObj02_ObjID 1;
BA_ "GenSigStartValue" SG_ 818 RRSideSensorObj02_ObjID 63;
BA_ "GenSigSendType" SG_ 818 RRSideSensorObj02_ObjClassConf 1;
BA_ "GenSigStartValue" SG_ 818 RRSideSensorObj02_ObjClassConf 15;
BA_ "GenSigSendType" SG_ 818 RRSideSensorObj02_LongPosVar 1;
BA_ "GenSigStartValue" SG_ 818 RRSideSensorObj02_LongPosVar 255;
BA_ "GenSigSendType" SG_ 818 RRSideSensorObj02_TrackStatus 1;
BA_ "GenSigStartValue" SG_ 818 RRSideSensorObj02_TrackStatus 7;
BA_ "GenSigSendType" SG_ 818 RRSideSensorObj02_CoastIndex 1;
BA_ "GenSigStartValue" SG_ 818 RRSideSensorObj02_CoastIndex 31;
BA_ "GenSigSendType" SG_ 818 RRSideSensorObj02_LatExtLeft 1;
BA_ "GenSigStartValue" SG_ 818 RRSideSensorObj02_LatExtLeft 127;
BA_ "GenSigSendType" SG_ 818 RRSideSensorObj02_Counter 1;
BA_ "GenSigStartValue" SG_ 818 RRSideSensorObj02_Counter 255;
BA_ "GenSigSendType" SG_ 818 RRSideSensorObj02_HeadingVar 1;
BA_ "GenSigStartValue" SG_ 818 RRSideSensorObj02_HeadingVar 255;
BA_ "GenSigSendType" SG_ 818 RRSideSensorObj02_LatExtRtVar 1;
BA_ "GenSigStartValue" SG_ 818 RRSideSensorObj02_LatExtRtVar 255;
BA_ "GenSigSendType" SG_ 818 RRSideSensorObj02_Heading 1;
BA_ "GenSigStartValue" SG_ 818 RRSideSensorObj02_Heading 2047;
BA_ "GenSigSendType" SG_ 818 RRSideSensorObj02_TimeStamp 1;
BA_ "GenSigStartValue" SG_ 818 RRSideSensorObj02_TimeStamp 65535;
BA_ "GenSigSendType" SG_ 818 RRSideSensorObj02_LatExtLeftVar 1;
BA_ "GenSigStartValue" SG_ 818 RRSideSensorObj02_LatExtLeftVar 255;
BA_ "GenSigSendType" SG_ 818 RRSideSensorObj02_CRC 1;
BA_ "GenSigStartValue" SG_ 818 RRSideSensorObj02_CRC 65535;
BA_ "E2EDataId" SG_ 818 RRSideSensorObj02_CRC 56;
BA_ "E2EDataLength" SG_ 818 RRSideSensorObj02_CRC 312;
BA_ "E2EProfile" SG_ 818 RRSideSensorObj02_CRC "P05";
BA_ "GenSigSendType" SG_ 818 RRSideSensorObj02_LatPosVar 1;
BA_ "GenSigStartValue" SG_ 818 RRSideSensorObj02_LatPosVar 255;
BA_ "GenSigSendType" SG_ 818 RRSideSensorObj02_LongVel 1;
BA_ "GenSigStartValue" SG_ 818 RRSideSensorObj02_LongVel 8191;
BA_ "GenSigSendType" SG_ 818 RRSideSensorObj02_LongExtBkVar 1;
BA_ "GenSigStartValue" SG_ 818 RRSideSensorObj02_LongExtBkVar 255;
BA_ "GenSigSendType" SG_ 818 RRSideSensorObj02_LatAccVar 1;
BA_ "GenSigStartValue" SG_ 818 RRSideSensorObj02_LatAccVar 255;
BA_ "GenSigSendType" SG_ 818 RRSideSensorObj02_LifeTime 1;
BA_ "GenSigStartValue" SG_ 818 RRSideSensorObj02_LifeTime 65535;
BA_ "GenSigSendType" SG_ 818 RRSideSensorObj02_ObjClass 1;
BA_ "GenSigStartValue" SG_ 818 RRSideSensorObj02_ObjClass 15;
BA_ "GenSigSendType" SG_ 818 RRSideSensorObj02_LongExtFront 1;
BA_ "GenSigStartValue" SG_ 818 RRSideSensorObj02_LongExtFront 1023;
BA_ "GenSigSendType" SG_ 817 RRSideSensorObj01_ExistConf 1;
BA_ "GenSigStartValue" SG_ 817 RRSideSensorObj01_ExistConf 127;
BA_ "GenSigSendType" SG_ 817 RRSideSensorObj01_MOISPrio 1;
BA_ "GenSigSendType" SG_ 817 RRSideSensorObj01_LatVelVar 1;
BA_ "GenSigStartValue" SG_ 817 RRSideSensorObj01_LatVelVar 255;
BA_ "GenSigSendType" SG_ 817 RRSideSensorObj01_LongAcc 1;
BA_ "GenSigStartValue" SG_ 817 RRSideSensorObj01_LongAcc 511;
BA_ "GenSigSendType" SG_ 817 RRSideSensorObj01_Prioritisation 1;
BA_ "GenSigStartValue" SG_ 817 RRSideSensorObj01_Prioritisation 3;
BA_ "GenSigSendType" SG_ 817 RRSideSensorObj01_LifeTime 1;
BA_ "GenSigStartValue" SG_ 817 RRSideSensorObj01_LifeTime 65535;
BA_ "GenSigSendType" SG_ 817 RRSideSensorObj01_LatExtRight 1;
BA_ "GenSigStartValue" SG_ 817 RRSideSensorObj01_LatExtRight 127;
BA_ "GenSigSendType" SG_ 817 RRSideSensorObj01_HeadingVar 1;
BA_ "GenSigStartValue" SG_ 817 RRSideSensorObj01_HeadingVar 255;
BA_ "GenSigSendType" SG_ 817 RRSideSensorObj01_LatAccVar 1;
BA_ "GenSigStartValue" SG_ 817 RRSideSensorObj01_LatAccVar 255;
BA_ "GenSigSendType" SG_ 817 RRSideSensorObj01_LongAccVar 1;
BA_ "GenSigStartValue" SG_ 817 RRSideSensorObj01_LongAccVar 255;
BA_ "GenSigSendType" SG_ 817 RRSideSensorObj01_CoastIndex 1;
BA_ "GenSigStartValue" SG_ 817 RRSideSensorObj01_CoastIndex 31;
BA_ "GenSigSendType" SG_ 817 RRSideSensorObj01_ObstacleConf 1;
BA_ "GenSigStartValue" SG_ 817 RRSideSensorObj01_ObstacleConf 127;
BA_ "GenSigSendType" SG_ 817 RRSideSensorObj01_TimeStamp 1;
BA_ "GenSigStartValue" SG_ 817 RRSideSensorObj01_TimeStamp 65535;
BA_ "GenSigSendType" SG_ 817 RRSideSensorObj01_LongVel 1;
BA_ "GenSigStartValue" SG_ 817 RRSideSensorObj01_LongVel 8191;
BA_ "GenSigSendType" SG_ 817 RRSideSensorObj01_ObjID 1;
BA_ "GenSigStartValue" SG_ 817 RRSideSensorObj01_ObjID 63;
BA_ "GenSigSendType" SG_ 817 RRSideSensorObj01_LongPos 1;
BA_ "GenSigStartValue" SG_ 817 RRSideSensorObj01_LongPos 8191;
BA_ "GenSigSendType" SG_ 817 RRSideSensorObj01_LatPos 1;
BA_ "GenSigStartValue" SG_ 817 RRSideSensorObj01_LatPos 8191;
BA_ "GenSigSendType" SG_ 817 RRSideSensorObj01_LatAcc 1;
BA_ "GenSigStartValue" SG_ 817 RRSideSensorObj01_LatAcc 511;
BA_ "GenSigSendType" SG_ 817 RRSideSensorObj01_LongExtBack 1;
BA_ "GenSigStartValue" SG_ 817 RRSideSensorObj01_LongExtBack 1023;
BA_ "GenSigSendType" SG_ 817 RRSideSensorObj01_LongVelVar 1;
BA_ "GenSigStartValue" SG_ 817 RRSideSensorObj01_LongVelVar 255;
BA_ "GenSigSendType" SG_ 817 RRSideSensorObj01_LongExtFrVar 1;
BA_ "GenSigStartValue" SG_ 817 RRSideSensorObj01_LongExtFrVar 255;
BA_ "GenSigSendType" SG_ 817 RRSideSensorObj01_ObjDynClass 1;
BA_ "GenSigStartValue" SG_ 817 RRSideSensorObj01_ObjDynClass 3;
BA_ "GenSigSendType" SG_ 817 RRSideSensorObj01_Counter 1;
BA_ "GenSigStartValue" SG_ 817 RRSideSensorObj01_Counter 255;
BA_ "GenSigSendType" SG_ 817 RRSideSensorObj01_ObjClassConf 1;
BA_ "GenSigStartValue" SG_ 817 RRSideSensorObj01_ObjClassConf 15;
BA_ "GenSigSendType" SG_ 817 RRSideSensorObj01_LatExtLeft 1;
BA_ "GenSigStartValue" SG_ 817 RRSideSensorObj01_LatExtLeft 127;
BA_ "GenSigSendType" SG_ 817 RRSideSensorObj01_Height 1;
BA_ "GenSigStartValue" SG_ 817 RRSideSensorObj01_Height 255;
BA_ "GenSigSendType" SG_ 817 RRSideSensorObj01_ObjClass 1;
BA_ "GenSigStartValue" SG_ 817 RRSideSensorObj01_ObjClass 15;
BA_ "GenSigSendType" SG_ 817 RRSideSensorObj01_LongPosVar 1;
BA_ "GenSigStartValue" SG_ 817 RRSideSensorObj01_LongPosVar 255;
BA_ "GenSigSendType" SG_ 817 RRSideSensorObj01_Heading 1;
BA_ "GenSigStartValue" SG_ 817 RRSideSensorObj01_Heading 2047;
BA_ "GenSigSendType" SG_ 817 RRSideSensorObj01_LatExtRtVar 1;
BA_ "GenSigStartValue" SG_ 817 RRSideSensorObj01_LatExtRtVar 255;
BA_ "GenSigSendType" SG_ 817 RRSideSensorObj01_LongExtFront 1;
BA_ "GenSigStartValue" SG_ 817 RRSideSensorObj01_LongExtFront 1023;
BA_ "GenSigSendType" SG_ 817 RRSideSensorObj01_LatExtLeftVar 1;
BA_ "GenSigStartValue" SG_ 817 RRSideSensorObj01_LatExtLeftVar 255;
BA_ "GenSigSendType" SG_ 817 RRSideSensorObj01_LatPosVar 1;
BA_ "GenSigStartValue" SG_ 817 RRSideSensorObj01_LatPosVar 255;
BA_ "GenSigSendType" SG_ 817 RRSideSensorObj01_TrackStatus 1;
BA_ "GenSigStartValue" SG_ 817 RRSideSensorObj01_TrackStatus 7;
BA_ "GenSigSendType" SG_ 817 RRSideSensorObj01_LatVel 1;
BA_ "GenSigStartValue" SG_ 817 RRSideSensorObj01_LatVel 8191;
BA_ "GenSigSendType" SG_ 817 RRSideSensorObj01_LongExtBkVar 1;
BA_ "GenSigStartValue" SG_ 817 RRSideSensorObj01_LongExtBkVar 255;
BA_ "GenSigSendType" SG_ 817 RRSideSensorObj01_CRC 1;
BA_ "GenSigStartValue" SG_ 817 RRSideSensorObj01_CRC 65535;
BA_ "E2EDataId" SG_ 817 RRSideSensorObj01_CRC 55;
BA_ "E2EDataLength" SG_ 817 RRSideSensorObj01_CRC 312;
BA_ "E2EProfile" SG_ 817 RRSideSensorObj01_CRC "P05";
BA_REL_ "GenSigFirstTimeoutTime" BU_SG_REL_ DACU SG_ 1072 RRSideSensorMALElevation 3000;
BA_REL_ "GenSigTimeoutTime" BU_SG_REL_ DACU SG_ 1072 RRSideSensorMALElevation 300;
BA_REL_ "GenSigFirstTimeoutTime" BU_SG_REL_ DACU SG_ 1072 RRSideSensorMALAzimuth 3000;
BA_REL_ "GenSigTimeoutTime" BU_SG_REL_ DACU SG_ 1072 RRSideSensorMALAzimuth 300;
BA_REL_ "GenSigFirstTimeoutTime" BU_SG_REL_ DACU SG_ 1072 RRSideSensorSafeState 3000;
BA_REL_ "GenSigTimeoutTime" BU_SG_REL_ DACU SG_ 1072 RRSideSensorSafeState 300;
BA_REL_ "GenSigFirstTimeoutTime" BU_SG_REL_ DACU SG_ 829 SideRadarRR_CalibState 3000;
BA_REL_ "GenSigTimeoutTime" BU_SG_REL_ DACU SG_ 829 SideRadarRR_CalibState 300;
BA_REL_ "GenSigFirstTimeoutTime" BU_SG_REL_ DACU SG_ 829 RRSRSensingRadarStat_DecalDetect 3000;
BA_REL_ "GenSigTimeoutTime" BU_SG_REL_ DACU SG_ 829 RRSRSensingRadarStat_DecalDetect 300;
BA_REL_ "GenSigFirstTimeoutTime" BU_SG_REL_ DACU SG_ 829 RRSRSensingRadarStat_Counter 3000;
BA_REL_ "GenSigTimeoutTime" BU_SG_REL_ DACU SG_ 829 RRSRSensingRadarStat_Counter 300;
BA_REL_ "GenSigFirstTimeoutTime" BU_SG_REL_ DACU SG_ 829 RRSRSideSensorStatus 3000;
BA_REL_ "GenSigTimeoutTime" BU_SG_REL_ DACU SG_ 829 RRSRSideSensorStatus 300;
BA_REL_ "GenSigFirstTimeoutTime" BU_SG_REL_ DACU SG_ 829 SideRadarRR_CalibProgress 3000;
BA_REL_ "GenSigTimeoutTime" BU_SG_REL_ DACU SG_ 829 SideRadarRR_CalibProgress 300;
BA_REL_ "GenSigFirstTimeoutTime" BU_SG_REL_ DACU SG_ 829 RRSRSensingRadarStat_Target 3000;
BA_REL_ "GenSigTimeoutTime" BU_SG_REL_ DACU SG_ 829 RRSRSensingRadarStat_Target 300;
BA_REL_ "GenSigFirstTimeoutTime" BU_SG_REL_ DACU SG_ 829 RRSRSensingRadarStat_RoadEdge 3000;
BA_REL_ "GenSigTimeoutTime" BU_SG_REL_ DACU SG_ 829 RRSRSensingRadarStat_RoadEdge 300;
BA_REL_ "GenSigFirstTimeoutTime" BU_SG_REL_ DACU SG_ 829 SideRadarRR_CalibPausedAcc 3000;
BA_REL_ "GenSigTimeoutTime" BU_SG_REL_ DACU SG_ 829 SideRadarRR_CalibPausedAcc 300;
BA_REL_ "GenSigFirstTimeoutTime" BU_SG_REL_ DACU SG_ 829 RRSRSensingRadarStat_Trailer 3000;
BA_REL_ "GenSigTimeoutTime" BU_SG_REL_ DACU SG_ 829 RRSRSensingRadarStat_Trailer 300;
BA_REL_ "GenSigFirstTimeoutTime" BU_SG_REL_ DACU SG_ 829 SideRadarRR_CalibPausedSpeed 3000;
BA_REL_ "GenSigTimeoutTime" BU_SG_REL_ DACU SG_ 829 SideRadarRR_CalibPausedSpeed 300;
BA_REL_ "GenSigFirstTimeoutTime" BU_SG_REL_ DACU SG_ 829 RRSRSensingRadarStat_TimeSynch 3000;
BA_REL_ "GenSigTimeoutTime" BU_SG_REL_ DACU SG_ 829 RRSRSensingRadarStat_TimeSynch 300;
BA_REL_ "GenSigFirstTimeoutTime" BU_SG_REL_ DACU SG_ 829 RRSRSensingRadarStat_CRC 3000;
BA_REL_ "GenSigTimeoutTime" BU_SG_REL_ DACU SG_ 829 RRSRSensingRadarStat_CRC 300;
BA_REL_ "GenSigFirstTimeoutTime" BU_SG_REL_ DACU SG_ 829 SideRadarRR_CalibPausedYaw 3000;
BA_REL_ "GenSigTimeoutTime" BU_SG_REL_ DACU SG_ 829 SideRadarRR_CalibPausedYaw 300;
BA_REL_ "GenSigFirstTimeoutTime" BU_SG_REL_ DACU SG_ 1056 RFSideSensorSafeState 3000;
BA_REL_ "GenSigTimeoutTime" BU_SG_REL_ DACU SG_ 1056 RFSideSensorSafeState 300;
BA_REL_ "GenSigFirstTimeoutTime" BU_SG_REL_ DACU SG_ 1056 RFSideSensorMALElevation 3000;
BA_REL_ "GenSigTimeoutTime" BU_SG_REL_ DACU SG_ 1056 RFSideSensorMALElevation 300;
BA_REL_ "GenSigFirstTimeoutTime" BU_SG_REL_ DACU SG_ 1056 RFSideSensorMALAzimuth 3000;
BA_REL_ "GenSigTimeoutTime" BU_SG_REL_ DACU SG_ 1056 RFSideSensorMALAzimuth 300;
BA_REL_ "GenSigFirstTimeoutTime" BU_SG_REL_ DACU SG_ 813 RFSRSensingRadarStat_Counter 3000;
BA_REL_ "GenSigTimeoutTime" BU_SG_REL_ DACU SG_ 813 RFSRSensingRadarStat_Counter 300;
BA_REL_ "GenSigFirstTimeoutTime" BU_SG_REL_ DACU SG_ 813 RFSRSensingRadarStat_CRC 3000;
BA_REL_ "GenSigTimeoutTime" BU_SG_REL_ DACU SG_ 813 RFSRSensingRadarStat_CRC 300;
BA_REL_ "GenSigFirstTimeoutTime" BU_SG_REL_ DACU SG_ 813 SideRadarRF_CalibProgress 3000;
BA_REL_ "GenSigTimeoutTime" BU_SG_REL_ DACU SG_ 813 SideRadarRF_CalibProgress 300;
BA_REL_ "GenSigFirstTimeoutTime" BU_SG_REL_ DACU SG_ 813 RFSRSensingRadarStat_RoadEdge 3000;
BA_REL_ "GenSigTimeoutTime" BU_SG_REL_ DACU SG_ 813 RFSRSensingRadarStat_RoadEdge 300;
BA_REL_ "GenSigFirstTimeoutTime" BU_SG_REL_ DACU SG_ 813 SideRadarRF_CalibPausedAcc 3000;
BA_REL_ "GenSigTimeoutTime" BU_SG_REL_ DACU SG_ 813 SideRadarRF_CalibPausedAcc 300;
BA_REL_ "GenSigFirstTimeoutTime" BU_SG_REL_ DACU SG_ 813 SideRadarRF_CalibPausedSpeed 3000;
BA_REL_ "GenSigTimeoutTime" BU_SG_REL_ DACU SG_ 813 SideRadarRF_CalibPausedSpeed 300;
BA_REL_ "GenSigFirstTimeoutTime" BU_SG_REL_ DACU SG_ 813 SideRadarRF_CalibPausedYaw 3000;
BA_REL_ "GenSigTimeoutTime" BU_SG_REL_ DACU SG_ 813 SideRadarRF_CalibPausedYaw 300;
BA_REL_ "GenSigFirstTimeoutTime" BU_SG_REL_ DACU SG_ 813 RFSRSideSensorStatus 3000;
BA_REL_ "GenSigTimeoutTime" BU_SG_REL_ DACU SG_ 813 RFSRSideSensorStatus 300;
BA_REL_ "GenSigFirstTimeoutTime" BU_SG_REL_ DACU SG_ 813 RFSRSensingRadarStat_TimeSynch 3000;
BA_REL_ "GenSigTimeoutTime" BU_SG_REL_ DACU SG_ 813 RFSRSensingRadarStat_TimeSynch 300;
BA_REL_ "GenSigFirstTimeoutTime" BU_SG_REL_ DACU SG_ 813 RFSRSensingRadarStat_Target 3000;
BA_REL_ "GenSigTimeoutTime" BU_SG_REL_ DACU SG_ 813 RFSRSensingRadarStat_Target 300;
BA_REL_ "GenSigFirstTimeoutTime" BU_SG_REL_ DACU SG_ 813 SideRadarRF_CalibState 3000;
BA_REL_ "GenSigTimeoutTime" BU_SG_REL_ DACU SG_ 813 SideRadarRF_CalibState 300;
BA_REL_ "GenSigFirstTimeoutTime" BU_SG_REL_ DACU SG_ 813 RFSRSensingRadarStat_DecalDetect 3000;
BA_REL_ "GenSigTimeoutTime" BU_SG_REL_ DACU SG_ 813 RFSRSensingRadarStat_DecalDetect 300;
BA_REL_ "GenSigFirstTimeoutTime" BU_SG_REL_ DACU SG_ 813 RFSRSensingRadarStat_Trailer 3000;
BA_REL_ "GenSigTimeoutTime" BU_SG_REL_ DACU SG_ 813 RFSRSensingRadarStat_Trailer 300;
BA_REL_ "GenSigFirstTimeoutTime" BU_SG_REL_ DACU SG_ 1040 LRSideSensorMALElevation 3000;
BA_REL_ "GenSigTimeoutTime" BU_SG_REL_ DACU SG_ 1040 LRSideSensorMALElevation 300;
BA_REL_ "GenSigFirstTimeoutTime" BU_SG_REL_ DACU SG_ 1040 LRSideSensorSafeState 3000;
BA_REL_ "GenSigTimeoutTime" BU_SG_REL_ DACU SG_ 1040 LRSideSensorSafeState 300;
BA_REL_ "GenSigFirstTimeoutTime" BU_SG_REL_ DACU SG_ 1040 LRSideSensorMALAzimuth 3000;
BA_REL_ "GenSigTimeoutTime" BU_SG_REL_ DACU SG_ 1040 LRSideSensorMALAzimuth 300;
BA_REL_ "GenSigFirstTimeoutTime" BU_SG_REL_ DACU SG_ 797 LRSRSensingRadarStat_RoadEdge 3000;
BA_REL_ "GenSigTimeoutTime" BU_SG_REL_ DACU SG_ 797 LRSRSensingRadarStat_RoadEdge 300;
BA_REL_ "GenSigFirstTimeoutTime" BU_SG_REL_ DACU SG_ 797 SideRadarLR_CalibState 3000;
BA_REL_ "GenSigTimeoutTime" BU_SG_REL_ DACU SG_ 797 SideRadarLR_CalibState 300;
BA_REL_ "GenSigFirstTimeoutTime" BU_SG_REL_ DACU SG_ 797 LRSRSensingRadarStat_Counter 3000;
BA_REL_ "GenSigTimeoutTime" BU_SG_REL_ DACU SG_ 797 LRSRSensingRadarStat_Counter 300;
BA_REL_ "GenSigFirstTimeoutTime" BU_SG_REL_ DACU SG_ 797 LRSRSensingRadarStat_CRC 3000;
BA_REL_ "GenSigTimeoutTime" BU_SG_REL_ DACU SG_ 797 LRSRSensingRadarStat_CRC 300;
BA_REL_ "GenSigFirstTimeoutTime" BU_SG_REL_ DACU SG_ 797 LRSRSensingRadarStat_Target 3000;
BA_REL_ "GenSigTimeoutTime" BU_SG_REL_ DACU SG_ 797 LRSRSensingRadarStat_Target 300;
BA_REL_ "GenSigFirstTimeoutTime" BU_SG_REL_ DACU SG_ 797 SideRadarLR_CalibPausedAcc 3000;
BA_REL_ "GenSigTimeoutTime" BU_SG_REL_ DACU SG_ 797 SideRadarLR_CalibPausedAcc 300;
BA_REL_ "GenSigFirstTimeoutTime" BU_SG_REL_ DACU SG_ 797 SideRadarLR_CalibPausedYaw 3000;
BA_REL_ "GenSigTimeoutTime" BU_SG_REL_ DACU SG_ 797 SideRadarLR_CalibPausedYaw 300;
BA_REL_ "GenSigFirstTimeoutTime" BU_SG_REL_ DACU SG_ 797 LRSRSideSensorStatus 3000;
BA_REL_ "GenSigTimeoutTime" BU_SG_REL_ DACU SG_ 797 LRSRSideSensorStatus 300;
BA_REL_ "GenSigFirstTimeoutTime" BU_SG_REL_ DACU SG_ 797 SideRadarLR_CalibProgress 3000;
BA_REL_ "GenSigTimeoutTime" BU_SG_REL_ DACU SG_ 797 SideRadarLR_CalibProgress 300;
BA_REL_ "GenSigFirstTimeoutTime" BU_SG_REL_ DACU SG_ 797 SideRadarLR_CalibPausedSpeed 3000;
BA_REL_ "GenSigTimeoutTime" BU_SG_REL_ DACU SG_ 797 SideRadarLR_CalibPausedSpeed 300;
BA_REL_ "GenSigFirstTimeoutTime" BU_SG_REL_ DACU SG_ 797 LRSRSensingRadarStat_TimeSynch 3000;
BA_REL_ "GenSigTimeoutTime" BU_SG_REL_ DACU SG_ 797 LRSRSensingRadarStat_TimeSynch 300;
BA_REL_ "GenSigFirstTimeoutTime" BU_SG_REL_ DACU SG_ 797 LRSRSensingRadarStat_Trailer 3000;
BA_REL_ "GenSigTimeoutTime" BU_SG_REL_ DACU SG_ 797 LRSRSensingRadarStat_Trailer 300;
BA_REL_ "GenSigFirstTimeoutTime" BU_SG_REL_ DACU SG_ 797 LRSRSensingRadarStat_DecalDetect 3000;
BA_REL_ "GenSigTimeoutTime" BU_SG_REL_ DACU SG_ 797 LRSRSensingRadarStat_DecalDetect 300;
BA_REL_ "GenSigFirstTimeoutTime" BU_SG_REL_ DACU SG_ 1088 LFSideSensorMALElevation 3000;
BA_REL_ "GenSigTimeoutTime" BU_SG_REL_ DACU SG_ 1088 LFSideSensorMALElevation 300;
BA_REL_ "GenSigFirstTimeoutTime" BU_SG_REL_ DACU SG_ 1088 LFSideSensorSafeState 3000;
BA_REL_ "GenSigTimeoutTime" BU_SG_REL_ DACU SG_ 1088 LFSideSensorSafeState 300;
BA_REL_ "GenSigFirstTimeoutTime" BU_SG_REL_ DACU SG_ 1088 LFSideSensorMALAzimuth 3000;
BA_REL_ "GenSigTimeoutTime" BU_SG_REL_ DACU SG_ 1088 LFSideSensorMALAzimuth 300;
BA_REL_ "GenSigFirstTimeoutTime" BU_SG_REL_ DACU SG_ 845 LFSRSensingRadarStat_DecalDetect 3000;
BA_REL_ "GenSigTimeoutTime" BU_SG_REL_ DACU SG_ 845 LFSRSensingRadarStat_DecalDetect 300;
BA_REL_ "GenSigFirstTimeoutTime" BU_SG_REL_ DACU SG_ 845 SideRadarLF_CalibPausedSpeed 3000;
BA_REL_ "GenSigTimeoutTime" BU_SG_REL_ DACU SG_ 845 SideRadarLF_CalibPausedSpeed 300;
BA_REL_ "GenSigFirstTimeoutTime" BU_SG_REL_ DACU SG_ 845 SideRadarLF_CalibState 3000;
BA_REL_ "GenSigTimeoutTime" BU_SG_REL_ DACU SG_ 845 SideRadarLF_CalibState 300;
BA_REL_ "GenSigFirstTimeoutTime" BU_SG_REL_ DACU SG_ 845 SideRadarLF_CalibPausedYaw 3000;
BA_REL_ "GenSigTimeoutTime" BU_SG_REL_ DACU SG_ 845 SideRadarLF_CalibPausedYaw 300;
BA_REL_ "GenSigFirstTimeoutTime" BU_SG_REL_ DACU SG_ 845 LFSRSensingRadarStat_Counter 3000;
BA_REL_ "GenSigTimeoutTime" BU_SG_REL_ DACU SG_ 845 LFSRSensingRadarStat_Counter 300;
BA_REL_ "GenSigFirstTimeoutTime" BU_SG_REL_ DACU SG_ 845 LFSRSensingRadarStat_Target 3000;
BA_REL_ "GenSigTimeoutTime" BU_SG_REL_ DACU SG_ 845 LFSRSensingRadarStat_Target 300;
BA_REL_ "GenSigFirstTimeoutTime" BU_SG_REL_ DACU SG_ 845 LFSRSideSensorStatus 3000;
BA_REL_ "GenSigTimeoutTime" BU_SG_REL_ DACU SG_ 845 LFSRSideSensorStatus 300;
BA_REL_ "GenSigFirstTimeoutTime" BU_SG_REL_ DACU SG_ 845 LFSRSensingRadarStat_TimeSynch 3000;
BA_REL_ "GenSigTimeoutTime" BU_SG_REL_ DACU SG_ 845 LFSRSensingRadarStat_TimeSynch 300;
BA_REL_ "GenSigFirstTimeoutTime" BU_SG_REL_ DACU SG_ 845 LFSRSensingRadarStat_CRC 3000;
BA_REL_ "GenSigTimeoutTime" BU_SG_REL_ DACU SG_ 845 LFSRSensingRadarStat_CRC 300;
BA_REL_ "GenSigFirstTimeoutTime" BU_SG_REL_ DACU SG_ 845 LFSRSensingRadarStat_RoadEdge 3000;
BA_REL_ "GenSigTimeoutTime" BU_SG_REL_ DACU SG_ 845 LFSRSensingRadarStat_RoadEdge 300;
BA_REL_ "GenSigFirstTimeoutTime" BU_SG_REL_ DACU SG_ 845 SideRadarLF_CalibProgress 3000;
BA_REL_ "GenSigTimeoutTime" BU_SG_REL_ DACU SG_ 845 SideRadarLF_CalibProgress 300;
BA_REL_ "GenSigFirstTimeoutTime" BU_SG_REL_ DACU SG_ 845 LFSRSensingRadarStat_Trailer 3000;
BA_REL_ "GenSigTimeoutTime" BU_SG_REL_ DACU SG_ 845 LFSRSensingRadarStat_Trailer 300;
BA_REL_ "GenSigFirstTimeoutTime" BU_SG_REL_ DACU SG_ 845 SideRadarLF_CalibPausedAcc 3000;
BA_REL_ "GenSigTimeoutTime" BU_SG_REL_ DACU SG_ 845 SideRadarLF_CalibPausedAcc 300;
BA_REL_ "GenSigFirstTimeoutTime" BU_SG_REL_ DACU SG_ 828 RRSideSensorTrlrObj_TrlAnglConf 3000;
BA_REL_ "GenSigTimeoutTime" BU_SG_REL_ DACU SG_ 828 RRSideSensorTrlrObj_TrlAnglConf 300;
BA_REL_ "GenSigFirstTimeoutTime" BU_SG_REL_ DACU SG_ 828 RRSideSensorTrlrObj_Seg3Length 3000;
BA_REL_ "GenSigTimeoutTime" BU_SG_REL_ DACU SG_ 828 RRSideSensorTrlrObj_Seg3Length 300;
BA_REL_ "GenSigFirstTimeoutTime" BU_SG_REL_ DACU SG_ 828 RRSideSensorTrlrObj_SegTrlrType1 3000;
BA_REL_ "GenSigTimeoutTime" BU_SG_REL_ DACU SG_ 828 RRSideSensorTrlrObj_SegTrlrType1 300;
BA_REL_ "GenSigFirstTimeoutTime" BU_SG_REL_ DACU SG_ 828 RRSideSensorTrlrObj_SegAngle4 3000;
BA_REL_ "GenSigTimeoutTime" BU_SG_REL_ DACU SG_ 828 RRSideSensorTrlrObj_SegAngle4 300;
BA_REL_ "GenSigFirstTimeoutTime" BU_SG_REL_ DACU SG_ 828 RRSideSensorTrlrObj_WheelBased2 3000;
BA_REL_ "GenSigTimeoutTime" BU_SG_REL_ DACU SG_ 828 RRSideSensorTrlrObj_WheelBased2 300;
BA_REL_ "GenSigFirstTimeoutTime" BU_SG_REL_ DACU SG_ 828 RRSideSensorTrlrObj_SegAngle3 3000;
BA_REL_ "GenSigTimeoutTime" BU_SG_REL_ DACU SG_ 828 RRSideSensorTrlrObj_SegAngle3 300;
BA_REL_ "GenSigFirstTimeoutTime" BU_SG_REL_ DACU SG_ 828 RRSideSensorTrlrObj_SegAngle5 3000;
BA_REL_ "GenSigTimeoutTime" BU_SG_REL_ DACU SG_ 828 RRSideSensorTrlrObj_SegAngle5 300;
BA_REL_ "GenSigFirstTimeoutTime" BU_SG_REL_ DACU SG_ 828 RRSideSensorTrlrObj_SegTrlrType5 3000;
BA_REL_ "GenSigTimeoutTime" BU_SG_REL_ DACU SG_ 828 RRSideSensorTrlrObj_SegTrlrType5 300;
BA_REL_ "GenSigFirstTimeoutTime" BU_SG_REL_ DACU SG_ 828 RRSideSensorTrlrObj_WheelBased1 3000;
BA_REL_ "GenSigTimeoutTime" BU_SG_REL_ DACU SG_ 828 RRSideSensorTrlrObj_WheelBased1 300;
BA_REL_ "GenSigFirstTimeoutTime" BU_SG_REL_ DACU SG_ 828 RRSideSensorTrlrObj_SegTrlrType4 3000;
BA_REL_ "GenSigTimeoutTime" BU_SG_REL_ DACU SG_ 828 RRSideSensorTrlrObj_SegTrlrType4 300;
BA_REL_ "GenSigFirstTimeoutTime" BU_SG_REL_ DACU SG_ 828 RRSideSensorTrlrObj_WheelBased5 3000;
BA_REL_ "GenSigTimeoutTime" BU_SG_REL_ DACU SG_ 828 RRSideSensorTrlrObj_WheelBased5 300;
BA_REL_ "GenSigFirstTimeoutTime" BU_SG_REL_ DACU SG_ 828 RRSideSensorTrlrObj_SegAngle1 3000;
BA_REL_ "GenSigTimeoutTime" BU_SG_REL_ DACU SG_ 828 RRSideSensorTrlrObj_SegAngle1 300;
BA_REL_ "GenSigFirstTimeoutTime" BU_SG_REL_ DACU SG_ 828 RRSideSensorTrlrObj_Seg5Length 3000;
BA_REL_ "GenSigTimeoutTime" BU_SG_REL_ DACU SG_ 828 RRSideSensorTrlrObj_Seg5Length 300;
BA_REL_ "GenSigFirstTimeoutTime" BU_SG_REL_ DACU SG_ 828 RRSideSensorTrlrObj_SegTrlrType3 3000;
BA_REL_ "GenSigTimeoutTime" BU_SG_REL_ DACU SG_ 828 RRSideSensorTrlrObj_SegTrlrType3 300;
BA_REL_ "GenSigFirstTimeoutTime" BU_SG_REL_ DACU SG_ 828 RRSideSensorTrlrObj_WheelBased4 3000;
BA_REL_ "GenSigTimeoutTime" BU_SG_REL_ DACU SG_ 828 RRSideSensorTrlrObj_WheelBased4 300;
BA_REL_ "GenSigFirstTimeoutTime" BU_SG_REL_ DACU SG_ 828 RRSideSensorTrlrObj_Seg4Length 3000;
BA_REL_ "GenSigTimeoutTime" BU_SG_REL_ DACU SG_ 828 RRSideSensorTrlrObj_Seg4Length 300;
BA_REL_ "GenSigFirstTimeoutTime" BU_SG_REL_ DACU SG_ 828 RRSideSensorTrlrObj_WhlBasedConf 3000;
BA_REL_ "GenSigTimeoutTime" BU_SG_REL_ DACU SG_ 828 RRSideSensorTrlrObj_WhlBasedConf 300;
BA_REL_ "GenSigFirstTimeoutTime" BU_SG_REL_ DACU SG_ 828 RRSideSensorTrlrObj_Seg1Length 3000;
BA_REL_ "GenSigTimeoutTime" BU_SG_REL_ DACU SG_ 828 RRSideSensorTrlrObj_Seg1Length 300;
BA_REL_ "GenSigFirstTimeoutTime" BU_SG_REL_ DACU SG_ 828 RRSideSensorTrlrObj_SegTrlrType2 3000;
BA_REL_ "GenSigTimeoutTime" BU_SG_REL_ DACU SG_ 828 RRSideSensorTrlrObj_SegTrlrType2 300;
BA_REL_ "GenSigFirstTimeoutTime" BU_SG_REL_ DACU SG_ 828 RRSideSensorTrlrObj_SegAngle2 3000;
BA_REL_ "GenSigTimeoutTime" BU_SG_REL_ DACU SG_ 828 RRSideSensorTrlrObj_SegAngle2 300;
BA_REL_ "GenSigFirstTimeoutTime" BU_SG_REL_ DACU SG_ 828 RRSideSensorTrlrObj_WheelBased3 3000;
BA_REL_ "GenSigTimeoutTime" BU_SG_REL_ DACU SG_ 828 RRSideSensorTrlrObj_WheelBased3 300;
BA_REL_ "GenSigFirstTimeoutTime" BU_SG_REL_ DACU SG_ 828 RRSideSensorTrlrObj_TotLenConf 3000;
BA_REL_ "GenSigTimeoutTime" BU_SG_REL_ DACU SG_ 828 RRSideSensorTrlrObj_TotLenConf 300;
BA_REL_ "GenSigFirstTimeoutTime" BU_SG_REL_ DACU SG_ 828 RRSideSensorTrlrObj_TrlrTypeConf 3000;
BA_REL_ "GenSigTimeoutTime" BU_SG_REL_ DACU SG_ 828 RRSideSensorTrlrObj_TrlrTypeConf 300;
BA_REL_ "GenSigFirstTimeoutTime" BU_SG_REL_ DACU SG_ 828 RRSideSensorTrlrObj_Seg2Length 3000;
BA_REL_ "GenSigTimeoutTime" BU_SG_REL_ DACU SG_ 828 RRSideSensorTrlrObj_Seg2Length 300;
BA_REL_ "GenSigFirstTimeoutTime" BU_SG_REL_ DACU SG_ 828 RRSideSensorTrlrObj_TotalLength 3000;
BA_REL_ "GenSigTimeoutTime" BU_SG_REL_ DACU SG_ 828 RRSideSensorTrlrObj_TotalLength 300;
VAL_ 1072 RRSideSensorSafeState 3 "InactiveActive_NotAvailable" 2 "InactiveActive_Error" 1 "InactiveActive_Active" 0 "InactiveActive_Inactive" ;
VAL_ 829 SideRadarRR_CalibState 3 "CalibState_NotAvailable" 2 "CalibState_Failure" 1 "CalibState_Running" 0 "CalibState_Success" ;
VAL_ 829 RRSRSensingRadarStat_DecalDetect 7 "DecalibrationDetection_NotAvailable" 6 "DecalibrationDetection_Error" 5 "DecalibrationDetection_CalibrationNotVerified" 4 "DecalibrationDetection_Spare3" 3 "DecalibrationDetection_Spare2" 2 "DecalibrationDetection_Spare1" 1 "DecalibrationDetection_NotCalibrated" 0 "DecalibrationDetection_FullyCalibrated" ;
VAL_ 829 RRSRSideSensorStatus 15 "RadarSensorStatus_NotAvailable" 14 "RadarSensorStatus_Error" 13 "RadarSensorStatus_TemporaryNotAvailable" 12 "RadarSensorStatus_Spare04" 11 "RadarSensorStatus_Spare03" 10 "RadarSensorStatus_Spare02" 9 "RadarSensorStatus_Spare01" 8 "RadarSensorStatus_Blinded" 7 "RadarSensorStatus_ShutDownCompleted" 6 "RadarSensorStatus_ShutDownInitiated" 5 "RadarSensorStatus_CalibrationOngoing" 4 "RadarSensorStatus_NotCalibrated" 3 "RadarSensorStatus_Misaligned" 2 "RadarSensorStatus_Blocked" 1 "RadarSensorStatus_WarmingUp" 0 "RadarSensorStatus_FullyOperational" ;
VAL_ 829 RRSRSensingRadarStat_Target 7 "SensorStatus3bit_NotAvailable" 6 "SensorStatus3bit_Error" 5 "SensorStatus3bit_Spare2" 4 "SensorStatus3bit_Spare1" 3 "SensorStatus3bit_NotOperational" 2 "SensorStatus3bit_Initialisation" 1 "SensorStatus3bit_ReducedMode" 0 "SensorStatus3bit_FullyOperational" ;
VAL_ 829 RRSRSensingRadarStat_RoadEdge 7 "SensorStatus3bit_NotAvailable" 6 "SensorStatus3bit_Error" 5 "SensorStatus3bit_Spare2" 4 "SensorStatus3bit_Spare1" 3 "SensorStatus3bit_NotOperational" 2 "SensorStatus3bit_Initialisation" 1 "SensorStatus3bit_ReducedMode" 0 "SensorStatus3bit_FullyOperational" ;
VAL_ 829 SideRadarRR_CalibPausedAcc 1 "FalseTrue1bit_True" 0 "FalseTrue1bit_False" ;
VAL_ 829 RRSRSensingRadarStat_Trailer 7 "SideSensorTrailerStat_NotAvailable" 6 "SideSensorTrailerStat_Error" 5 "SideSensorTrailerStat_Spare" 4 "SideSensorTrailerStat_NoTrailerConnected" 3 "SideSensorTrailerStat_NotOperational" 2 "SideSensorTrailerStat_Initialisation" 1 "SideSensorTrailerStat_ReducedMode" 0 "SideSensorTrailerStat_FullyOperational" ;
VAL_ 829 SideRadarRR_CalibPausedSpeed 1 "FalseTrue1bit_True" 0 "FalseTrue1bit_False" ;
VAL_ 829 SideRadarRR_CalibPausedYaw 1 "FalseTrue1bit_True" 0 "FalseTrue1bit_False" ;
VAL_ 1056 RFSideSensorSafeState 3 "InactiveActive_NotAvailable" 2 "InactiveActive_Error" 1 "InactiveActive_Active" 0 "InactiveActive_Inactive" ;
VAL_ 813 RFSRSensingRadarStat_RoadEdge 7 "SensorStatus3bit_NotAvailable" 6 "SensorStatus3bit_Error" 5 "SensorStatus3bit_Spare2" 4 "SensorStatus3bit_Spare1" 3 "SensorStatus3bit_NotOperational" 2 "SensorStatus3bit_Initialisation" 1 "SensorStatus3bit_ReducedMode" 0 "SensorStatus3bit_FullyOperational" ;
VAL_ 813 SideRadarRF_CalibPausedAcc 1 "FalseTrue1bit_True" 0 "FalseTrue1bit_False" ;
VAL_ 813 SideRadarRF_CalibPausedSpeed 1 "FalseTrue1bit_True" 0 "FalseTrue1bit_False" ;
VAL_ 813 SideRadarRF_CalibPausedYaw 1 "FalseTrue1bit_True" 0 "FalseTrue1bit_False" ;
VAL_ 813 RFSRSideSensorStatus 15 "RadarSensorStatus_NotAvailable" 14 "RadarSensorStatus_Error" 13 "RadarSensorStatus_TemporaryNotAvailable" 12 "RadarSensorStatus_Spare04" 11 "RadarSensorStatus_Spare03" 10 "RadarSensorStatus_Spare02" 9 "RadarSensorStatus_Spare01" 8 "RadarSensorStatus_Blinded" 7 "RadarSensorStatus_ShutDownCompleted" 6 "RadarSensorStatus_ShutDownInitiated" 5 "RadarSensorStatus_CalibrationOngoing" 4 "RadarSensorStatus_NotCalibrated" 3 "RadarSensorStatus_Misaligned" 2 "RadarSensorStatus_Blocked" 1 "RadarSensorStatus_WarmingUp" 0 "RadarSensorStatus_FullyOperational" ;
VAL_ 813 RFSRSensingRadarStat_Target 7 "SensorStatus3bit_NotAvailable" 6 "SensorStatus3bit_Error" 5 "SensorStatus3bit_Spare2" 4 "SensorStatus3bit_Spare1" 3 "SensorStatus3bit_NotOperational" 2 "SensorStatus3bit_Initialisation" 1 "SensorStatus3bit_ReducedMode" 0 "SensorStatus3bit_FullyOperational" ;
VAL_ 813 SideRadarRF_CalibState 3 "CalibState_NotAvailable" 2 "CalibState_Failure" 1 "CalibState_Running" 0 "CalibState_Success" ;
VAL_ 813 RFSRSensingRadarStat_DecalDetect 7 "DecalibrationDetection_NotAvailable" 6 "DecalibrationDetection_Error" 5 "DecalibrationDetection_CalibrationNotVerified" 4 "DecalibrationDetection_Spare3" 3 "DecalibrationDetection_Spare2" 2 "DecalibrationDetection_Spare1" 1 "DecalibrationDetection_NotCalibrated" 0 "DecalibrationDetection_FullyCalibrated" ;
VAL_ 813 RFSRSensingRadarStat_Trailer 7 "SideSensorTrailerStat_NotAvailable" 6 "SideSensorTrailerStat_Error" 5 "SideSensorTrailerStat_Spare" 4 "SideSensorTrailerStat_NoTrailerConnected" 3 "SideSensorTrailerStat_NotOperational" 2 "SideSensorTrailerStat_Initialisation" 1 "SideSensorTrailerStat_ReducedMode" 0 "SideSensorTrailerStat_FullyOperational" ;
VAL_ 1040 LRSideSensorSafeState 3 "InactiveActive_NotAvailable" 2 "InactiveActive_Error" 1 "InactiveActive_Active" 0 "InactiveActive_Inactive" ;
VAL_ 797 LRSRSensingRadarStat_RoadEdge 7 "SensorStatus3bit_NotAvailable" 6 "SensorStatus3bit_Error" 5 "SensorStatus3bit_Spare2" 4 "SensorStatus3bit_Spare1" 3 "SensorStatus3bit_NotOperational" 2 "SensorStatus3bit_Initialisation" 1 "SensorStatus3bit_ReducedMode" 0 "SensorStatus3bit_FullyOperational" ;
VAL_ 797 SideRadarLR_CalibState 3 "CalibState_NotAvailable" 2 "CalibState_Failure" 1 "CalibState_Running" 0 "CalibState_Success" ;
VAL_ 797 LRSRSensingRadarStat_Target 7 "SensorStatus3bit_NotAvailable" 6 "SensorStatus3bit_Error" 5 "SensorStatus3bit_Spare2" 4 "SensorStatus3bit_Spare1" 3 "SensorStatus3bit_NotOperational" 2 "SensorStatus3bit_Initialisation" 1 "SensorStatus3bit_ReducedMode" 0 "SensorStatus3bit_FullyOperational" ;
VAL_ 797 SideRadarLR_CalibPausedAcc 1 "FalseTrue1bit_True" 0 "FalseTrue1bit_False" ;
VAL_ 797 SideRadarLR_CalibPausedYaw 1 "FalseTrue1bit_True" 0 "FalseTrue1bit_False" ;
VAL_ 797 LRSRSideSensorStatus 15 "RadarSensorStatus_NotAvailable" 14 "RadarSensorStatus_Error" 13 "RadarSensorStatus_TemporaryNotAvailable" 12 "RadarSensorStatus_Spare04" 11 "RadarSensorStatus_Spare03" 10 "RadarSensorStatus_Spare02" 9 "RadarSensorStatus_Spare01" 8 "RadarSensorStatus_Blinded" 7 "RadarSensorStatus_ShutDownCompleted" 6 "RadarSensorStatus_ShutDownInitiated" 5 "RadarSensorStatus_CalibrationOngoing" 4 "RadarSensorStatus_NotCalibrated" 3 "RadarSensorStatus_Misaligned" 2 "RadarSensorStatus_Blocked" 1 "RadarSensorStatus_WarmingUp" 0 "RadarSensorStatus_FullyOperational" ;
VAL_ 797 SideRadarLR_CalibPausedSpeed 1 "FalseTrue1bit_True" 0 "FalseTrue1bit_False" ;
VAL_ 797 LRSRSensingRadarStat_Trailer 7 "SideSensorTrailerStat_NotAvailable" 6 "SideSensorTrailerStat_Error" 5 "SideSensorTrailerStat_Spare" 4 "SideSensorTrailerStat_NoTrailerConnected" 3 "SideSensorTrailerStat_NotOperational" 2 "SideSensorTrailerStat_Initialisation" 1 "SideSensorTrailerStat_ReducedMode" 0 "SideSensorTrailerStat_FullyOperational" ;
VAL_ 797 LRSRSensingRadarStat_DecalDetect 7 "DecalibrationDetection_NotAvailable" 6 "DecalibrationDetection_Error" 5 "DecalibrationDetection_CalibrationNotVerified" 4 "DecalibrationDetection_Spare3" 3 "DecalibrationDetection_Spare2" 2 "DecalibrationDetection_Spare1" 1 "DecalibrationDetection_NotCalibrated" 0 "DecalibrationDetection_FullyCalibrated" ;
VAL_ 1088 LFSideSensorSafeState 3 "InactiveActive_NotAvailable" 2 "InactiveActive_Error" 1 "InactiveActive_Active" 0 "InactiveActive_Inactive" ;
VAL_ 845 LFSRSensingRadarStat_DecalDetect 7 "DecalibrationDetection_NotAvailable" 6 "DecalibrationDetection_Error" 5 "DecalibrationDetection_CalibrationNotVerified" 4 "DecalibrationDetection_Spare3" 3 "DecalibrationDetection_Spare2" 2 "DecalibrationDetection_Spare1" 1 "DecalibrationDetection_NotCalibrated" 0 "DecalibrationDetection_FullyCalibrated" ;
VAL_ 845 SideRadarLF_CalibPausedSpeed 1 "FalseTrue1bit_True" 0 "FalseTrue1bit_False" ;
VAL_ 845 SideRadarLF_CalibState 3 "CalibState_NotAvailable" 2 "CalibState_Failure" 1 "CalibState_Running" 0 "CalibState_Success" ;
VAL_ 845 SideRadarLF_CalibPausedYaw 1 "FalseTrue1bit_True" 0 "FalseTrue1bit_False" ;
VAL_ 845 LFSRSensingRadarStat_Target 7 "SensorStatus3bit_NotAvailable" 6 "SensorStatus3bit_Error" 5 "SensorStatus3bit_Spare2" 4 "SensorStatus3bit_Spare1" 3 "SensorStatus3bit_NotOperational" 2 "SensorStatus3bit_Initialisation" 1 "SensorStatus3bit_ReducedMode" 0 "SensorStatus3bit_FullyOperational" ;
VAL_ 845 LFSRSideSensorStatus 15 "RadarSensorStatus_NotAvailable" 14 "RadarSensorStatus_Error" 13 "RadarSensorStatus_TemporaryNotAvailable" 12 "RadarSensorStatus_Spare04" 11 "RadarSensorStatus_Spare03" 10 "RadarSensorStatus_Spare02" 9 "RadarSensorStatus_Spare01" 8 "RadarSensorStatus_Blinded" 7 "RadarSensorStatus_ShutDownCompleted" 6 "RadarSensorStatus_ShutDownInitiated" 5 "RadarSensorStatus_CalibrationOngoing" 4 "RadarSensorStatus_NotCalibrated" 3 "RadarSensorStatus_Misaligned" 2 "RadarSensorStatus_Blocked" 1 "RadarSensorStatus_WarmingUp" 0 "RadarSensorStatus_FullyOperational" ;
VAL_ 845 LFSRSensingRadarStat_RoadEdge 7 "SensorStatus3bit_NotAvailable" 6 "SensorStatus3bit_Error" 5 "SensorStatus3bit_Spare2" 4 "SensorStatus3bit_Spare1" 3 "SensorStatus3bit_NotOperational" 2 "SensorStatus3bit_Initialisation" 1 "SensorStatus3bit_ReducedMode" 0 "SensorStatus3bit_FullyOperational" ;
VAL_ 845 LFSRSensingRadarStat_Trailer 7 "SideSensorTrailerStat_NotAvailable" 6 "SideSensorTrailerStat_Error" 5 "SideSensorTrailerStat_Spare" 4 "SideSensorTrailerStat_NoTrailerConnected" 3 "SideSensorTrailerStat_NotOperational" 2 "SideSensorTrailerStat_Initialisation" 1 "SideSensorTrailerStat_ReducedMode" 0 "SideSensorTrailerStat_FullyOperational" ;
VAL_ 845 SideRadarLF_CalibPausedAcc 1 "FalseTrue1bit_True" 0 "FalseTrue1bit_False" ;
VAL_ 828 RRSideSensorTrlrObj_SegTrlrType1 15 "SegTrailerType_NotAvailable" 14 "SegTrailerType_Error" 13 "SegTrailerType_Spare6" 12 "SegTrailerType_Spare5" 11 "SegTrailerType_Spare4" 10 "SegTrailerType_Spare3" 9 "SegTrailerType_Spare2" 8 "SegTrailerType_Spare1" 7 "SegTrailerType_TowingFullTrailer" 6 "SegTrailerType_TowingCentreAxleTrailer" 5 "SegTrailerType_TowingSemiTrailer" 4 "SegTrailerType_LinkTrailer" 3 "SegTrailerType_ConverterDolly" 2 "SegTrailerType_FullTrailer" 1 "SegTrailerType_CentreAxleTrailer" 0 "SegTrailerType_SemiTrailer" ;
VAL_ 828 RRSideSensorTrlrObj_SegTrlrType5 15 "SegTrailerType_NotAvailable" 14 "SegTrailerType_Error" 13 "SegTrailerType_Spare6" 12 "SegTrailerType_Spare5" 11 "SegTrailerType_Spare4" 10 "SegTrailerType_Spare3" 9 "SegTrailerType_Spare2" 8 "SegTrailerType_Spare1" 7 "SegTrailerType_TowingFullTrailer" 6 "SegTrailerType_TowingCentreAxleTrailer" 5 "SegTrailerType_TowingSemiTrailer" 4 "SegTrailerType_LinkTrailer" 3 "SegTrailerType_ConverterDolly" 2 "SegTrailerType_FullTrailer" 1 "SegTrailerType_CentreAxleTrailer" 0 "SegTrailerType_SemiTrailer" ;
VAL_ 828 RRSideSensorTrlrObj_SegTrlrType4 15 "SegTrailerType_NotAvailable" 14 "SegTrailerType_Error" 13 "SegTrailerType_Spare6" 12 "SegTrailerType_Spare5" 11 "SegTrailerType_Spare4" 10 "SegTrailerType_Spare3" 9 "SegTrailerType_Spare2" 8 "SegTrailerType_Spare1" 7 "SegTrailerType_TowingFullTrailer" 6 "SegTrailerType_TowingCentreAxleTrailer" 5 "SegTrailerType_TowingSemiTrailer" 4 "SegTrailerType_LinkTrailer" 3 "SegTrailerType_ConverterDolly" 2 "SegTrailerType_FullTrailer" 1 "SegTrailerType_CentreAxleTrailer" 0 "SegTrailerType_SemiTrailer" ;
VAL_ 828 RRSideSensorTrlrObj_SegTrlrType3 15 "SegTrailerType_NotAvailable" 14 "SegTrailerType_Error" 13 "SegTrailerType_Spare6" 12 "SegTrailerType_Spare5" 11 "SegTrailerType_Spare4" 10 "SegTrailerType_Spare3" 9 "SegTrailerType_Spare2" 8 "SegTrailerType_Spare1" 7 "SegTrailerType_TowingFullTrailer" 6 "SegTrailerType_TowingCentreAxleTrailer" 5 "SegTrailerType_TowingSemiTrailer" 4 "SegTrailerType_LinkTrailer" 3 "SegTrailerType_ConverterDolly" 2 "SegTrailerType_FullTrailer" 1 "SegTrailerType_CentreAxleTrailer" 0 "SegTrailerType_SemiTrailer" ;
VAL_ 828 RRSideSensorTrlrObj_SegTrlrType2 15 "SegTrailerType_NotAvailable" 14 "SegTrailerType_Error" 13 "SegTrailerType_Spare6" 12 "SegTrailerType_Spare5" 11 "SegTrailerType_Spare4" 10 "SegTrailerType_Spare3" 9 "SegTrailerType_Spare2" 8 "SegTrailerType_Spare1" 7 "SegTrailerType_TowingFullTrailer" 6 "SegTrailerType_TowingCentreAxleTrailer" 5 "SegTrailerType_TowingSemiTrailer" 4 "SegTrailerType_LinkTrailer" 3 "SegTrailerType_ConverterDolly" 2 "SegTrailerType_FullTrailer" 1 "SegTrailerType_CentreAxleTrailer" 0 "SegTrailerType_SemiTrailer" ;
VAL_ 828 RRSideSensorTrlrObj_TotLenConf 7 "TotLenConf_NotAvailable" 6 "TotLenConf_Error" 5 "TotLenConf_Spare" 4 "TotLenConf_LessThanPoint1m" 3 "TotLenConf_LessThanPoint5m" 2 "TotLenConf_LessThan1m" 1 "TotLenConf_LessThan3m" 0 "TotLenConf_GreaterThan3m" ;
VAL_ 827 RRSideSensorObj11_TrackStatus 7 "TrackStatus_NotAvailable" 6 "TrackStatus_Error" 5 "TrackStatus_Spare3" 4 "TrackStatus_Spare2" 3 "TrackStatus_Spare1" 2 "TrackStatus_Invalid" 1 "TrackStatus_Predicted" 0 "TrackStatus_Tracked" ;
VAL_ 827 RRSideSensorObj11_ObjClass 15 "ObjClassSideS_NotAvailable" 14 "ObjClassSideS_Error" 13 "ObjClassSideS_Spare4" 12 "ObjClassSideS_Spare3" 11 "ObjClassSideS_Motorcycle" 10 "ObjClassSideS_Bicycle" 9 "ObjClassSideS_UnidentifiedMovableObject" 8 "ObjClassSideS_UnidentifiedVRU" 7 "ObjClassSideS_UnidentifiedVehicle" 6 "ObjClassSideS_StaticObject" 5 "ObjClassSideS_Pedestrian" 4 "ObjClassSideS_2Wheeler" 3 "ObjClassSideS_HeavyVehicle" 2 "ObjClassSideS_Car" 1 "ObjClassSideS_Obstacle" 0 "ObjClassSideS_Undetermined" ;
VAL_ 827 RRSideSensorObj11_ObjDynClass 3 "ObjDynClass_Error" 2 "ObjDynClass_Movable" 1 "ObjDynClass_Stationary" 0 "ObjDynClass_Reserved" ;
VAL_ 827 RRSideSensorObj11_Prioritisation 3 "Prioritisation_NotAvailable" 2 "Prioritisation_StaticPrioritisation" 1 "Prioritisation_VolvoPrioritisation" 0 "Prioritisation_BoschPrioritisation" ;
VAL_ 826 RRSideSensorObj10_ObjDynClass 3 "ObjDynClass_Error" 2 "ObjDynClass_Movable" 1 "ObjDynClass_Stationary" 0 "ObjDynClass_Reserved" ;
VAL_ 826 RRSideSensorObj10_Prioritisation 3 "Prioritisation_NotAvailable" 2 "Prioritisation_StaticPrioritisation" 1 "Prioritisation_VolvoPrioritisation" 0 "Prioritisation_BoschPrioritisation" ;
VAL_ 826 RRSideSensorObj10_ObjClass 15 "ObjClassSideS_NotAvailable" 14 "ObjClassSideS_Error" 13 "ObjClassSideS_Spare4" 12 "ObjClassSideS_Spare3" 11 "ObjClassSideS_Motorcycle" 10 "ObjClassSideS_Bicycle" 9 "ObjClassSideS_UnidentifiedMovableObject" 8 "ObjClassSideS_UnidentifiedVRU" 7 "ObjClassSideS_UnidentifiedVehicle" 6 "ObjClassSideS_StaticObject" 5 "ObjClassSideS_Pedestrian" 4 "ObjClassSideS_2Wheeler" 3 "ObjClassSideS_HeavyVehicle" 2 "ObjClassSideS_Car" 1 "ObjClassSideS_Obstacle" 0 "ObjClassSideS_Undetermined" ;
VAL_ 826 RRSideSensorObj10_TrackStatus 7 "TrackStatus_NotAvailable" 6 "TrackStatus_Error" 5 "TrackStatus_Spare3" 4 "TrackStatus_Spare2" 3 "TrackStatus_Spare1" 2 "TrackStatus_Invalid" 1 "TrackStatus_Predicted" 0 "TrackStatus_Tracked" ;
VAL_ 825 RRSideSensorObj09_ObjDynClass 3 "ObjDynClass_Error" 2 "ObjDynClass_Movable" 1 "ObjDynClass_Stationary" 0 "ObjDynClass_Reserved" ;
VAL_ 825 RRSideSensorObj09_ObjClass 15 "ObjClassSideS_NotAvailable" 14 "ObjClassSideS_Error" 13 "ObjClassSideS_Spare4" 12 "ObjClassSideS_Spare3" 11 "ObjClassSideS_Motorcycle" 10 "ObjClassSideS_Bicycle" 9 "ObjClassSideS_UnidentifiedMovableObject" 8 "ObjClassSideS_UnidentifiedVRU" 7 "ObjClassSideS_UnidentifiedVehicle" 6 "ObjClassSideS_StaticObject" 5 "ObjClassSideS_Pedestrian" 4 "ObjClassSideS_2Wheeler" 3 "ObjClassSideS_HeavyVehicle" 2 "ObjClassSideS_Car" 1 "ObjClassSideS_Obstacle" 0 "ObjClassSideS_Undetermined" ;
VAL_ 825 RRSideSensorObj09_Prioritisation 3 "Prioritisation_NotAvailable" 2 "Prioritisation_StaticPrioritisation" 1 "Prioritisation_VolvoPrioritisation" 0 "Prioritisation_BoschPrioritisation" ;
VAL_ 825 RRSideSensorObj09_TrackStatus 7 "TrackStatus_NotAvailable" 6 "TrackStatus_Error" 5 "TrackStatus_Spare3" 4 "TrackStatus_Spare2" 3 "TrackStatus_Spare1" 2 "TrackStatus_Invalid" 1 "TrackStatus_Predicted" 0 "TrackStatus_Tracked" ;
VAL_ 824 RRSideSensorObj08_Prioritisation 3 "Prioritisation_NotAvailable" 2 "Prioritisation_StaticPrioritisation" 1 "Prioritisation_VolvoPrioritisation" 0 "Prioritisation_BoschPrioritisation" ;
VAL_ 824 RRSideSensorObj08_TrackStatus 7 "TrackStatus_NotAvailable" 6 "TrackStatus_Error" 5 "TrackStatus_Spare3" 4 "TrackStatus_Spare2" 3 "TrackStatus_Spare1" 2 "TrackStatus_Invalid" 1 "TrackStatus_Predicted" 0 "TrackStatus_Tracked" ;
VAL_ 824 RRSideSensorObj08_ObjDynClass 3 "ObjDynClass_Error" 2 "ObjDynClass_Movable" 1 "ObjDynClass_Stationary" 0 "ObjDynClass_Reserved" ;
VAL_ 824 RRSideSensorObj08_ObjClass 15 "ObjClassSideS_NotAvailable" 14 "ObjClassSideS_Error" 13 "ObjClassSideS_Spare4" 12 "ObjClassSideS_Spare3" 11 "ObjClassSideS_Motorcycle" 10 "ObjClassSideS_Bicycle" 9 "ObjClassSideS_UnidentifiedMovableObject" 8 "ObjClassSideS_UnidentifiedVRU" 7 "ObjClassSideS_UnidentifiedVehicle" 6 "ObjClassSideS_StaticObject" 5 "ObjClassSideS_Pedestrian" 4 "ObjClassSideS_2Wheeler" 3 "ObjClassSideS_HeavyVehicle" 2 "ObjClassSideS_Car" 1 "ObjClassSideS_Obstacle" 0 "ObjClassSideS_Undetermined" ;
VAL_ 823 RRSideSensorObj07_Prioritisation 3 "Prioritisation_NotAvailable" 2 "Prioritisation_StaticPrioritisation" 1 "Prioritisation_VolvoPrioritisation" 0 "Prioritisation_BoschPrioritisation" ;
VAL_ 823 RRSideSensorObj07_TrackStatus 7 "TrackStatus_NotAvailable" 6 "TrackStatus_Error" 5 "TrackStatus_Spare3" 4 "TrackStatus_Spare2" 3 "TrackStatus_Spare1" 2 "TrackStatus_Invalid" 1 "TrackStatus_Predicted" 0 "TrackStatus_Tracked" ;
VAL_ 823 RRSideSensorObj07_ObjDynClass 3 "ObjDynClass_Error" 2 "ObjDynClass_Movable" 1 "ObjDynClass_Stationary" 0 "ObjDynClass_Reserved" ;
VAL_ 823 RRSideSensorObj07_ObjClass 15 "ObjClassSideS_NotAvailable" 14 "ObjClassSideS_Error" 13 "ObjClassSideS_Spare4" 12 "ObjClassSideS_Spare3" 11 "ObjClassSideS_Motorcycle" 10 "ObjClassSideS_Bicycle" 9 "ObjClassSideS_UnidentifiedMovableObject" 8 "ObjClassSideS_UnidentifiedVRU" 7 "ObjClassSideS_UnidentifiedVehicle" 6 "ObjClassSideS_StaticObject" 5 "ObjClassSideS_Pedestrian" 4 "ObjClassSideS_2Wheeler" 3 "ObjClassSideS_HeavyVehicle" 2 "ObjClassSideS_Car" 1 "ObjClassSideS_Obstacle" 0 "ObjClassSideS_Undetermined" ;
VAL_ 822 RRSideSensorObj06_ObjDynClass 3 "ObjDynClass_Error" 2 "ObjDynClass_Movable" 1 "ObjDynClass_Stationary" 0 "ObjDynClass_Reserved" ;
VAL_ 822 RRSideSensorObj06_Prioritisation 3 "Prioritisation_NotAvailable" 2 "Prioritisation_StaticPrioritisation" 1 "Prioritisation_VolvoPrioritisation" 0 "Prioritisation_BoschPrioritisation" ;
VAL_ 822 RRSideSensorObj06_ObjClass 15 "ObjClassSideS_NotAvailable" 14 "ObjClassSideS_Error" 13 "ObjClassSideS_Spare4" 12 "ObjClassSideS_Spare3" 11 "ObjClassSideS_Motorcycle" 10 "ObjClassSideS_Bicycle" 9 "ObjClassSideS_UnidentifiedMovableObject" 8 "ObjClassSideS_UnidentifiedVRU" 7 "ObjClassSideS_UnidentifiedVehicle" 6 "ObjClassSideS_StaticObject" 5 "ObjClassSideS_Pedestrian" 4 "ObjClassSideS_2Wheeler" 3 "ObjClassSideS_HeavyVehicle" 2 "ObjClassSideS_Car" 1 "ObjClassSideS_Obstacle" 0 "ObjClassSideS_Undetermined" ;
VAL_ 822 RRSideSensorObj06_TrackStatus 7 "TrackStatus_NotAvailable" 6 "TrackStatus_Error" 5 "TrackStatus_Spare3" 4 "TrackStatus_Spare2" 3 "TrackStatus_Spare1" 2 "TrackStatus_Invalid" 1 "TrackStatus_Predicted" 0 "TrackStatus_Tracked" ;
VAL_ 821 RRSideSensorObj05_ObjClass 15 "ObjClassSideS_NotAvailable" 14 "ObjClassSideS_Error" 13 "ObjClassSideS_Spare4" 12 "ObjClassSideS_Spare3" 11 "ObjClassSideS_Motorcycle" 10 "ObjClassSideS_Bicycle" 9 "ObjClassSideS_UnidentifiedMovableObject" 8 "ObjClassSideS_UnidentifiedVRU" 7 "ObjClassSideS_UnidentifiedVehicle" 6 "ObjClassSideS_StaticObject" 5 "ObjClassSideS_Pedestrian" 4 "ObjClassSideS_2Wheeler" 3 "ObjClassSideS_HeavyVehicle" 2 "ObjClassSideS_Car" 1 "ObjClassSideS_Obstacle" 0 "ObjClassSideS_Undetermined" ;
VAL_ 821 RRSideSensorObj05_Prioritisation 3 "Prioritisation_NotAvailable" 2 "Prioritisation_StaticPrioritisation" 1 "Prioritisation_VolvoPrioritisation" 0 "Prioritisation_BoschPrioritisation" ;
VAL_ 821 RRSideSensorObj05_TrackStatus 7 "TrackStatus_NotAvailable" 6 "TrackStatus_Error" 5 "TrackStatus_Spare3" 4 "TrackStatus_Spare2" 3 "TrackStatus_Spare1" 2 "TrackStatus_Invalid" 1 "TrackStatus_Predicted" 0 "TrackStatus_Tracked" ;
VAL_ 821 RRSideSensorObj05_ObjDynClass 3 "ObjDynClass_Error" 2 "ObjDynClass_Movable" 1 "ObjDynClass_Stationary" 0 "ObjDynClass_Reserved" ;
VAL_ 820 RRSideSensorObj04_TrackStatus 7 "TrackStatus_NotAvailable" 6 "TrackStatus_Error" 5 "TrackStatus_Spare3" 4 "TrackStatus_Spare2" 3 "TrackStatus_Spare1" 2 "TrackStatus_Invalid" 1 "TrackStatus_Predicted" 0 "TrackStatus_Tracked" ;
VAL_ 820 RRSideSensorObj04_ObjDynClass 3 "ObjDynClass_Error" 2 "ObjDynClass_Movable" 1 "ObjDynClass_Stationary" 0 "ObjDynClass_Reserved" ;
VAL_ 820 RRSideSensorObj04_ObjClass 15 "ObjClassSideS_NotAvailable" 14 "ObjClassSideS_Error" 13 "ObjClassSideS_Spare4" 12 "ObjClassSideS_Spare3" 11 "ObjClassSideS_Motorcycle" 10 "ObjClassSideS_Bicycle" 9 "ObjClassSideS_UnidentifiedMovableObject" 8 "ObjClassSideS_UnidentifiedVRU" 7 "ObjClassSideS_UnidentifiedVehicle" 6 "ObjClassSideS_StaticObject" 5 "ObjClassSideS_Pedestrian" 4 "ObjClassSideS_2Wheeler" 3 "ObjClassSideS_HeavyVehicle" 2 "ObjClassSideS_Car" 1 "ObjClassSideS_Obstacle" 0 "ObjClassSideS_Undetermined" ;
VAL_ 820 RRSideSensorObj04_Prioritisation 3 "Prioritisation_NotAvailable" 2 "Prioritisation_StaticPrioritisation" 1 "Prioritisation_VolvoPrioritisation" 0 "Prioritisation_BoschPrioritisation" ;
VAL_ 819 RRSideSensorObj03_ObjDynClass 3 "ObjDynClass_Error" 2 "ObjDynClass_Movable" 1 "ObjDynClass_Stationary" 0 "ObjDynClass_Reserved" ;
VAL_ 819 RRSideSensorObj03_ObjClass 15 "ObjClassSideS_NotAvailable" 14 "ObjClassSideS_Error" 13 "ObjClassSideS_Spare4" 12 "ObjClassSideS_Spare3" 11 "ObjClassSideS_Motorcycle" 10 "ObjClassSideS_Bicycle" 9 "ObjClassSideS_UnidentifiedMovableObject" 8 "ObjClassSideS_UnidentifiedVRU" 7 "ObjClassSideS_UnidentifiedVehicle" 6 "ObjClassSideS_StaticObject" 5 "ObjClassSideS_Pedestrian" 4 "ObjClassSideS_2Wheeler" 3 "ObjClassSideS_HeavyVehicle" 2 "ObjClassSideS_Car" 1 "ObjClassSideS_Obstacle" 0 "ObjClassSideS_Undetermined" ;
VAL_ 819 RRSideSensorObj03_Prioritisation 3 "Prioritisation_NotAvailable" 2 "Prioritisation_StaticPrioritisation" 1 "Prioritisation_VolvoPrioritisation" 0 "Prioritisation_BoschPrioritisation" ;
VAL_ 819 RRSideSensorObj03_TrackStatus 7 "TrackStatus_NotAvailable" 6 "TrackStatus_Error" 5 "TrackStatus_Spare3" 4 "TrackStatus_Spare2" 3 "TrackStatus_Spare1" 2 "TrackStatus_Invalid" 1 "TrackStatus_Predicted" 0 "TrackStatus_Tracked" ;
VAL_ 818 RRSideSensorObj02_Prioritisation 3 "Prioritisation_NotAvailable" 2 "Prioritisation_StaticPrioritisation" 1 "Prioritisation_VolvoPrioritisation" 0 "Prioritisation_BoschPrioritisation" ;
VAL_ 818 RRSideSensorObj02_ObjDynClass 3 "ObjDynClass_Error" 2 "ObjDynClass_Movable" 1 "ObjDynClass_Stationary" 0 "ObjDynClass_Reserved" ;
VAL_ 818 RRSideSensorObj02_TrackStatus 7 "TrackStatus_NotAvailable" 6 "TrackStatus_Error" 5 "TrackStatus_Spare3" 4 "TrackStatus_Spare2" 3 "TrackStatus_Spare1" 2 "TrackStatus_Invalid" 1 "TrackStatus_Predicted" 0 "TrackStatus_Tracked" ;
VAL_ 818 RRSideSensorObj02_ObjClass 15 "ObjClassSideS_NotAvailable" 14 "ObjClassSideS_Error" 13 "ObjClassSideS_Spare4" 12 "ObjClassSideS_Spare3" 11 "ObjClassSideS_Motorcycle" 10 "ObjClassSideS_Bicycle" 9 "ObjClassSideS_UnidentifiedMovableObject" 8 "ObjClassSideS_UnidentifiedVRU" 7 "ObjClassSideS_UnidentifiedVehicle" 6 "ObjClassSideS_StaticObject" 5 "ObjClassSideS_Pedestrian" 4 "ObjClassSideS_2Wheeler" 3 "ObjClassSideS_HeavyVehicle" 2 "ObjClassSideS_Car" 1 "ObjClassSideS_Obstacle" 0 "ObjClassSideS_Undetermined" ;
VAL_ 817 RRSideSensorObj01_Prioritisation 3 "Prioritisation_NotAvailable" 2 "Prioritisation_StaticPrioritisation" 1 "Prioritisation_VolvoPrioritisation" 0 "Prioritisation_BoschPrioritisation" ;
VAL_ 817 RRSideSensorObj01_ObjDynClass 3 "ObjDynClass_Error" 2 "ObjDynClass_Movable" 1 "ObjDynClass_Stationary" 0 "ObjDynClass_Reserved" ;
VAL_ 817 RRSideSensorObj01_ObjClass 15 "ObjClassSideS_NotAvailable" 14 "ObjClassSideS_Error" 13 "ObjClassSideS_Spare4" 12 "ObjClassSideS_Spare3" 11 "ObjClassSideS_Motorcycle" 10 "ObjClassSideS_Bicycle" 9 "ObjClassSideS_UnidentifiedMovableObject" 8 "ObjClassSideS_UnidentifiedVRU" 7 "ObjClassSideS_UnidentifiedVehicle" 6 "ObjClassSideS_StaticObject" 5 "ObjClassSideS_Pedestrian" 4 "ObjClassSideS_2Wheeler" 3 "ObjClassSideS_HeavyVehicle" 2 "ObjClassSideS_Car" 1 "ObjClassSideS_Obstacle" 0 "ObjClassSideS_Undetermined" ;
VAL_ 817 RRSideSensorObj01_TrackStatus 7 "TrackStatus_NotAvailable" 6 "TrackStatus_Error" 5 "TrackStatus_Spare3" 4 "TrackStatus_Spare2" 3 "TrackStatus_Spare1" 2 "TrackStatus_Invalid" 1 "TrackStatus_Predicted" 0 "TrackStatus_Tracked" ;
SIG_GROUP_ 829 SideRadarRR_sg 1 : SideRadarRR_CalibState SideRadarRR_CalibProgress SideRadarRR_CalibPausedAcc SideRadarRR_CalibPausedSpeed SideRadarRR_CalibPausedYaw;
SIG_GROUP_ 829 RRSRSensingRadarStat_sg 1 : RRSRSensingRadarStat_DecalDetect RRSRSensingRadarStat_Counter RRSRSensingRadarStat_Target RRSRSensingRadarStat_RoadEdge RRSRSensingRadarStat_Trailer RRSRSensingRadarStat_TimeSynch RRSRSensingRadarStat_CRC;
SIG_GROUP_ 813 RFSRSensingRadarStat_sg 1 : RFSRSensingRadarStat_Counter RFSRSensingRadarStat_CRC RFSRSensingRadarStat_RoadEdge RFSRSensingRadarStat_TimeSynch RFSRSensingRadarStat_Target RFSRSensingRadarStat_DecalDetect RFSRSensingRadarStat_Trailer;
SIG_GROUP_ 813 SideRadarRF_sg 1 : SideRadarRF_CalibProgress SideRadarRF_CalibPausedAcc SideRadarRF_CalibPausedSpeed SideRadarRF_CalibPausedYaw SideRadarRF_CalibState;
SIG_GROUP_ 797 LRSRSensingRadarStat_sg 1 : LRSRSensingRadarStat_RoadEdge LRSRSensingRadarStat_Counter LRSRSensingRadarStat_CRC LRSRSensingRadarStat_Target LRSRSensingRadarStat_TimeSynch LRSRSensingRadarStat_Trailer LRSRSensingRadarStat_DecalDetect;
SIG_GROUP_ 797 SideRadarLR_sg 1 : SideRadarLR_CalibState SideRadarLR_CalibPausedAcc SideRadarLR_CalibPausedYaw SideRadarLR_CalibProgress SideRadarLR_CalibPausedSpeed;
SIG_GROUP_ 845 LFSRSensingRadarStat_sg 1 : LFSRSensingRadarStat_DecalDetect LFSRSensingRadarStat_Counter LFSRSensingRadarStat_Target LFSRSensingRadarStat_TimeSynch LFSRSensingRadarStat_CRC LFSRSensingRadarStat_RoadEdge LFSRSensingRadarStat_Trailer;
SIG_GROUP_ 845 SideRadarLF_sg 1 : SideRadarLF_CalibPausedSpeed SideRadarLF_CalibState SideRadarLF_CalibPausedYaw SideRadarLF_CalibProgress SideRadarLF_CalibPausedAcc;
SIG_GROUP_ 828 RRSideSensorTrlrObj_sg 1 : RRSideSensorTrlrObj_TrlAnglConf RRSideSensorTrlrObj_Seg3Length RRSideSensorTrlrObj_SegTrlrType1 RRSideSensorTrlrObj_SegAngle4 RRSideSensorTrlrObj_WheelBased2 RRSideSensorTrlrObj_SegAngle3 RRSideSensorTrlrObj_SegAngle5 RRSideSensorTrlrObj_SegTrlrType5 RRSideSensorTrlrObj_WheelBased1 RRSideSensorTrlrObj_SegTrlrType4 RRSideSensorTrlrObj_WheelBased5 RRSideSensorTrlrObj_SegAngle1 RRSideSensorTrlrObj_Seg5Length RRSideSensorTrlrObj_SegTrlrType3 RRSideSensorTrlrObj_WheelBased4 RRSideSensorTrlrObj_Seg4Length RRSideSensorTrlrObj_WhlBasedConf RRSideSensorTrlrObj_Seg1Length RRSideSensorTrlrObj_SegTrlrType2 RRSideSensorTrlrObj_SegAngle2 RRSideSensorTrlrObj_WheelBased3 RRSideSensorTrlrObj_TotLenConf RRSideSensorTrlrObj_TrlrTypeConf RRSideSensorTrlrObj_Seg2Length RRSideSensorTrlrObj_TotalLength;
SIG_GROUP_ 827 RRSideSensorObj11_sg 1 : RRSideSensorObj11_TrackStatus RRSideSensorObj11_CoastIndex RRSideSensorObj11_ExistConf RRSideSensorObj11_LatExtLeft RRSideSensorObj11_CRC RRSideSensorObj11_LongExtBkVar RRSideSensorObj11_MOISPrio RRSideSensorObj11_LongPosVar RRSideSensorObj11_ObjClass RRSideSensorObj11_LatVel RRSideSensorObj11_LatExtLeftVar RRSideSensorObj11_LatPos RRSideSensorObj11_LongExtFront RRSideSensorObj11_LongAcc RRSideSensorObj11_LifeTime RRSideSensorObj11_LongVelVar RRSideSensorObj11_TimeStamp RRSideSensorObj11_LatAcc RRSideSensorObj11_HeadingVar RRSideSensorObj11_Counter RRSideSensorObj11_LatPosVar RRSideSensorObj11_LongPos RRSideSensorObj11_LongVel RRSideSensorObj11_ObjID RRSideSensorObj11_ObstacleConf RRSideSensorObj11_LatExtRight RRSideSensorObj11_LongExtBack RRSideSensorObj11_ObjClassConf RRSideSensorObj11_LatVelVar RRSideSensorObj11_Heading RRSideSensorObj11_Height RRSideSensorObj11_LatAccVar RRSideSensorObj11_LongAccVar RRSideSensorObj11_LatExtRtVar RRSideSensorObj11_LongExtFrVar RRSideSensorObj11_ObjDynClass RRSideSensorObj11_Prioritisation;
SIG_GROUP_ 826 RRSideSensorObj10_sg 1 : RRSideSensorObj10_Counter RRSideSensorObj10_LatExtRight RRSideSensorObj10_ObjClassConf RRSideSensorObj10_ObjDynClass RRSideSensorObj10_Prioritisation RRSideSensorObj10_ObjClass RRSideSensorObj10_LatPosVar RRSideSensorObj10_Height RRSideSensorObj10_LatExtRtVar RRSideSensorObj10_LatExtLeft RRSideSensorObj10_LongAccVar RRSideSensorObj10_LongExtBack RRSideSensorObj10_HeadingVar RRSideSensorObj10_CRC RRSideSensorObj10_LongExtBkVar RRSideSensorObj10_TrackStatus RRSideSensorObj10_LongVelVar RRSideSensorObj10_ObjID RRSideSensorObj10_LatExtLeftVar RRSideSensorObj10_LongAcc RRSideSensorObj10_ExistConf RRSideSensorObj10_Heading RRSideSensorObj10_LatAccVar RRSideSensorObj10_LatAcc RRSideSensorObj10_LongExtFront RRSideSensorObj10_LongExtFrVar RRSideSensorObj10_LatVel RRSideSensorObj10_LongPos RRSideSensorObj10_LatPos RRSideSensorObj10_LongPosVar RRSideSensorObj10_LongVel RRSideSensorObj10_ObstacleConf RRSideSensorObj10_MOISPrio RRSideSensorObj10_TimeStamp RRSideSensorObj10_LifeTime RRSideSensorObj10_CoastIndex RRSideSensorObj10_LatVelVar;
SIG_GROUP_ 825 RRSideSensorObj09_sg 1 : RRSideSensorObj09_LatExtRight RRSideSensorObj09_LongPosVar RRSideSensorObj09_Height RRSideSensorObj09_LongAccVar RRSideSensorObj09_LongExtBack RRSideSensorObj09_LatPosVar RRSideSensorObj09_LatVelVar RRSideSensorObj09_LatVel RRSideSensorObj09_LatExtLeft RRSideSensorObj09_HeadingVar RRSideSensorObj09_LatExtRtVar RRSideSensorObj09_ObjClassConf RRSideSensorObj09_CoastIndex RRSideSensorObj09_ObjDynClass RRSideSensorObj09_LongExtFrVar RRSideSensorObj09_LongPos RRSideSensorObj09_Counter RRSideSensorObj09_CRC RRSideSensorObj09_LatAcc RRSideSensorObj09_LongExtBkVar RRSideSensorObj09_Heading RRSideSensorObj09_LatAccVar RRSideSensorObj09_ObjClass RRSideSensorObj09_Prioritisation RRSideSensorObj09_LongVel RRSideSensorObj09_TrackStatus RRSideSensorObj09_LongExtFront RRSideSensorObj09_LatExtLeftVar RRSideSensorObj09_TimeStamp RRSideSensorObj09_ObjID RRSideSensorObj09_LongAcc RRSideSensorObj09_LatPos RRSideSensorObj09_ObstacleConf RRSideSensorObj09_MOISPrio RRSideSensorObj09_LongVelVar RRSideSensorObj09_ExistConf RRSideSensorObj09_LifeTime;
SIG_GROUP_ 824 RRSideSensorObj08_sg 1 : RRSideSensorObj08_LongExtBkVar RRSideSensorObj08_ExistConf RRSideSensorObj08_CRC RRSideSensorObj08_LifeTime RRSideSensorObj08_LatAcc RRSideSensorObj08_LongAcc RRSideSensorObj08_Counter RRSideSensorObj08_LongExtBack RRSideSensorObj08_LatExtLeft RRSideSensorObj08_TimeStamp RRSideSensorObj08_LatPosVar RRSideSensorObj08_LatExtLeftVar RRSideSensorObj08_Height RRSideSensorObj08_LongExtFront RRSideSensorObj08_Prioritisation RRSideSensorObj08_HeadingVar RRSideSensorObj08_LongAccVar RRSideSensorObj08_LatAccVar RRSideSensorObj08_ObstacleConf RRSideSensorObj08_LatVelVar RRSideSensorObj08_TrackStatus RRSideSensorObj08_MOISPrio RRSideSensorObj08_LatExtRight RRSideSensorObj08_LongPosVar RRSideSensorObj08_LongExtFrVar RRSideSensorObj08_LatVel RRSideSensorObj08_LatExtRtVar RRSideSensorObj08_ObjDynClass RRSideSensorObj08_LongVelVar RRSideSensorObj08_Heading RRSideSensorObj08_CoastIndex RRSideSensorObj08_ObjClass RRSideSensorObj08_LongVel RRSideSensorObj08_LatPos RRSideSensorObj08_ObjID RRSideSensorObj08_LongPos RRSideSensorObj08_ObjClassConf;
SIG_GROUP_ 823 RRSideSensorObj07_sg 1 : RRSideSensorObj07_LifeTime RRSideSensorObj07_HeadingVar RRSideSensorObj07_LongExtFrVar RRSideSensorObj07_ObjID RRSideSensorObj07_Heading RRSideSensorObj07_LongVelVar RRSideSensorObj07_TimeStamp RRSideSensorObj07_LatPosVar RRSideSensorObj07_ExistConf RRSideSensorObj07_Prioritisation RRSideSensorObj07_Counter RRSideSensorObj07_LatPos RRSideSensorObj07_LongVel RRSideSensorObj07_LongExtBack RRSideSensorObj07_LongExtFront RRSideSensorObj07_TrackStatus RRSideSensorObj07_LongExtBkVar RRSideSensorObj07_LatAccVar RRSideSensorObj07_LongAcc RRSideSensorObj07_LatAcc RRSideSensorObj07_ObjDynClass RRSideSensorObj07_ObjClassConf RRSideSensorObj07_CRC RRSideSensorObj07_LongPosVar RRSideSensorObj07_LatExtLeftVar RRSideSensorObj07_MOISPrio RRSideSensorObj07_ObjClass RRSideSensorObj07_ObstacleConf RRSideSensorObj07_LatExtRtVar RRSideSensorObj07_LatExtRight RRSideSensorObj07_LatExtLeft RRSideSensorObj07_Height RRSideSensorObj07_LatVel RRSideSensorObj07_LongAccVar RRSideSensorObj07_LongPos RRSideSensorObj07_CoastIndex RRSideSensorObj07_LatVelVar;
SIG_GROUP_ 822 RRSideSensorObj06_sg 1 : RRSideSensorObj06_LongExtFront RRSideSensorObj06_ObjDynClass RRSideSensorObj06_MOISPrio RRSideSensorObj06_LatExtLeft RRSideSensorObj06_ObjClassConf RRSideSensorObj06_LongPosVar RRSideSensorObj06_LatExtRight RRSideSensorObj06_LongVel RRSideSensorObj06_LifeTime RRSideSensorObj06_LongExtBack RRSideSensorObj06_HeadingVar RRSideSensorObj06_LatVel RRSideSensorObj06_LatExtRtVar RRSideSensorObj06_LongExtFrVar RRSideSensorObj06_LongAccVar RRSideSensorObj06_LatExtLeftVar RRSideSensorObj06_LongVelVar RRSideSensorObj06_Prioritisation RRSideSensorObj06_LongPos RRSideSensorObj06_Counter RRSideSensorObj06_LatVelVar RRSideSensorObj06_LatAccVar RRSideSensorObj06_Heading RRSideSensorObj06_ObjClass RRSideSensorObj06_ObstacleConf RRSideSensorObj06_LatPosVar RRSideSensorObj06_LongAcc RRSideSensorObj06_LongExtBkVar RRSideSensorObj06_Height RRSideSensorObj06_LatPos RRSideSensorObj06_CoastIndex RRSideSensorObj06_TrackStatus RRSideSensorObj06_LatAcc RRSideSensorObj06_ExistConf RRSideSensorObj06_CRC RRSideSensorObj06_ObjID RRSideSensorObj06_TimeStamp;
SIG_GROUP_ 821 RRSideSensorObj05_sg 1 : RRSideSensorObj05_LatPos RRSideSensorObj05_ObjClass RRSideSensorObj05_LongVel RRSideSensorObj05_ObjID RRSideSensorObj05_LatPosVar RRSideSensorObj05_Prioritisation RRSideSensorObj05_LifeTime RRSideSensorObj05_LongAccVar RRSideSensorObj05_CRC RRSideSensorObj05_TrackStatus RRSideSensorObj05_ObstacleConf RRSideSensorObj05_ObjDynClass RRSideSensorObj05_LatExtRight RRSideSensorObj05_LongPosVar RRSideSensorObj05_Heading RRSideSensorObj05_LongExtFront RRSideSensorObj05_LatAcc RRSideSensorObj05_MOISPrio RRSideSensorObj05_LatVelVar RRSideSensorObj05_LatAccVar RRSideSensorObj05_LongAcc RRSideSensorObj05_LongExtBack RRSideSensorObj05_ObjClassConf RRSideSensorObj05_ExistConf RRSideSensorObj05_Height RRSideSensorObj05_LongExtFrVar RRSideSensorObj05_Counter RRSideSensorObj05_TimeStamp RRSideSensorObj05_LongPos RRSideSensorObj05_LongVelVar RRSideSensorObj05_HeadingVar RRSideSensorObj05_LatExtRtVar RRSideSensorObj05_LatVel RRSideSensorObj05_LatExtLeft RRSideSensorObj05_LongExtBkVar RRSideSensorObj05_CoastIndex RRSideSensorObj05_LatExtLeftVar;
SIG_GROUP_ 820 RRSideSensorObj04_sg 1 : RRSideSensorObj04_HeadingVar RRSideSensorObj04_TrackStatus RRSideSensorObj04_LongExtFront RRSideSensorObj04_LatAcc RRSideSensorObj04_LongPosVar RRSideSensorObj04_LatVelVar RRSideSensorObj04_CoastIndex RRSideSensorObj04_LatPosVar RRSideSensorObj04_ExistConf RRSideSensorObj04_LatExtRight RRSideSensorObj04_LatAccVar RRSideSensorObj04_ObjID RRSideSensorObj04_LongAccVar RRSideSensorObj04_ObstacleConf RRSideSensorObj04_MOISPrio RRSideSensorObj04_LongPos RRSideSensorObj04_LatVel RRSideSensorObj04_LongExtBack RRSideSensorObj04_TimeStamp RRSideSensorObj04_LatExtRtVar RRSideSensorObj04_CRC RRSideSensorObj04_LatExtLeft RRSideSensorObj04_LongVel RRSideSensorObj04_LongExtFrVar RRSideSensorObj04_Counter RRSideSensorObj04_LatPos RRSideSensorObj04_LatExtLeftVar RRSideSensorObj04_LifeTime RRSideSensorObj04_Height RRSideSensorObj04_LongAcc RRSideSensorObj04_ObjDynClass RRSideSensorObj04_LongVelVar RRSideSensorObj04_ObjClass RRSideSensorObj04_ObjClassConf RRSideSensorObj04_Prioritisation RRSideSensorObj04_Heading RRSideSensorObj04_LongExtBkVar;
SIG_GROUP_ 819 RRSideSensorObj03_sg 1 : RRSideSensorObj03_LongExtBack RRSideSensorObj03_ObjDynClass RRSideSensorObj03_ObjClass RRSideSensorObj03_LatAcc RRSideSensorObj03_Heading RRSideSensorObj03_ObjClassConf RRSideSensorObj03_LongPos RRSideSensorObj03_ObjID RRSideSensorObj03_TimeStamp RRSideSensorObj03_LongPosVar RRSideSensorObj03_LatExtLeft RRSideSensorObj03_LongExtFrVar RRSideSensorObj03_LongVel RRSideSensorObj03_LatVel RRSideSensorObj03_Prioritisation RRSideSensorObj03_Height RRSideSensorObj03_CRC RRSideSensorObj03_LatExtRtVar RRSideSensorObj03_ExistConf RRSideSensorObj03_Counter RRSideSensorObj03_LongExtBkVar RRSideSensorObj03_LatVelVar RRSideSensorObj03_LatExtRight RRSideSensorObj03_LifeTime RRSideSensorObj03_LatExtLeftVar RRSideSensorObj03_HeadingVar RRSideSensorObj03_LatPos RRSideSensorObj03_ObstacleConf RRSideSensorObj03_LatPosVar RRSideSensorObj03_LongExtFront RRSideSensorObj03_LongAcc RRSideSensorObj03_CoastIndex RRSideSensorObj03_TrackStatus RRSideSensorObj03_MOISPrio RRSideSensorObj03_LongAccVar RRSideSensorObj03_LongVelVar RRSideSensorObj03_LatAccVar;
SIG_GROUP_ 818 RRSideSensorObj02_sg 1 : RRSideSensorObj02_Prioritisation RRSideSensorObj02_LongAcc RRSideSensorObj02_LatAcc RRSideSensorObj02_LatExtRight RRSideSensorObj02_LongAccVar RRSideSensorObj02_LongPos RRSideSensorObj02_ObstacleConf RRSideSensorObj02_LongExtFrVar RRSideSensorObj02_LatVelVar RRSideSensorObj02_MOISPrio RRSideSensorObj02_LatPos RRSideSensorObj02_LatVel RRSideSensorObj02_LongVelVar RRSideSensorObj02_LongExtBack RRSideSensorObj02_Height RRSideSensorObj02_ExistConf RRSideSensorObj02_ObjDynClass RRSideSensorObj02_ObjID RRSideSensorObj02_ObjClassConf RRSideSensorObj02_LongPosVar RRSideSensorObj02_TrackStatus RRSideSensorObj02_CoastIndex RRSideSensorObj02_LatExtLeft RRSideSensorObj02_Counter RRSideSensorObj02_HeadingVar RRSideSensorObj02_LatExtRtVar RRSideSensorObj02_Heading RRSideSensorObj02_TimeStamp RRSideSensorObj02_LatExtLeftVar RRSideSensorObj02_CRC RRSideSensorObj02_LatPosVar RRSideSensorObj02_LongVel RRSideSensorObj02_LongExtBkVar RRSideSensorObj02_LatAccVar RRSideSensorObj02_LifeTime RRSideSensorObj02_ObjClass RRSideSensorObj02_LongExtFront;
SIG_GROUP_ 817 RRSideSensorObj01_sg 1 : RRSideSensorObj01_ExistConf RRSideSensorObj01_MOISPrio RRSideSensorObj01_LatVelVar RRSideSensorObj01_LongAcc RRSideSensorObj01_Prioritisation RRSideSensorObj01_LifeTime RRSideSensorObj01_LatExtRight RRSideSensorObj01_HeadingVar RRSideSensorObj01_LatAccVar RRSideSensorObj01_LongAccVar RRSideSensorObj01_CoastIndex RRSideSensorObj01_ObstacleConf RRSideSensorObj01_TimeStamp RRSideSensorObj01_LongVel RRSideSensorObj01_ObjID RRSideSensorObj01_LongPos RRSideSensorObj01_LatPos RRSideSensorObj01_LatAcc RRSideSensorObj01_LongExtBack RRSideSensorObj01_LongVelVar RRSideSensorObj01_LongExtFrVar RRSideSensorObj01_ObjDynClass RRSideSensorObj01_Counter RRSideSensorObj01_ObjClassConf RRSideSensorObj01_LatExtLeft RRSideSensorObj01_Height RRSideSensorObj01_ObjClass RRSideSensorObj01_LongPosVar RRSideSensorObj01_Heading RRSideSensorObj01_LatExtRtVar RRSideSensorObj01_LongExtFront RRSideSensorObj01_LatExtLeftVar RRSideSensorObj01_LatPosVar RRSideSensorObj01_TrackStatus RRSideSensorObj01_LatVel RRSideSensorObj01_LongExtBkVar RRSideSensorObj01_CRC;
